// Generated by BusNet PQ (Produktiv) 6.6.4  © 2008 Sulzer GmbH
VERSION "HNNBNNNYNNNNNNNNNNNNNNNNNNNNNNNNNNNNNNNNNN/4/%%%/4/'%**4NNN///"

NS_ :

BS_:

BU_: BAP_Tester Booster_AMP DSP_SKODA Gateway_PQ35 Gateway_PQ46 GSM_Pager Kompassmodul MDI Radio_2DIN Radio_Modul Radio_SKODA Rearview RNS_300_NF RNS_MFD2 RNS_midline SDARS_Tuner Sprachbedienung Standheizung Tastatur Telematik_Basis TV_hybrid UHV_High UHV_low UHV_NAR UHV_Premium UHV_UMTS

BO_ 1349 mParkhilfe_3: 4 Gateway_PQ35
 SG_ PA3_System_codierung : 0|1@1+ (1,0) [0|1] "" Vector__XXX
 SG_ PA3_Anlage_defekt : 1|1@1+ (1,0) [0|1] "" Vector__XXX
 SG_ PA3_Taster_aktiviert : 2|1@1+ (1,0) [0|1] "" Vector__XXX
 SG_ PA3_Rueckwaertsgang_aktiv : 3|1@1+ (1,0) [0|1] "" Vector__XXX
 SG_ PA3_Geschwindigkeit_aus : 4|1@1+ (1,0) [0|1] "" Vector__XXX
 SG_ PA3_Tongeber_v_defekt : 5|1@1+ (1,0) [0|1] "" Vector__XXX
 SG_ PA3_Tongeber_h_defekt : 6|1@1+ (1,0) [0|1] "" Vector__XXX
 SG_ PA3_Audioabsenkung_Anforderung : 7|1@1+ (1,0) [0|1] "" Vector__XXX
 SG_ PA3_Eis_aus : 8|1@1+ (1,0) [0|1] "" Vector__XXX
 SG_ PA3_Schlechtweg_aus : 9|1@1+ (1,0) [0|1] "" Vector__XXX
 SG_ PA3_KD_Fehler : 15|1@1+ (1,0) [0|1] "" Vector__XXX
 SG_ PA3_Sensor_hll_defekt : 16|1@1+ (1,0) [0|1] "" Vector__XXX
 SG_ PA3_Sensor_hlm_defekt : 17|1@1+ (1,0) [0|1] "" Vector__XXX
 SG_ PA3_Sensor_hrm_defekt : 18|1@1+ (1,0) [0|1] "" Vector__XXX
 SG_ PA3_Sensor_hrr_defekt : 19|1@1+ (1,0) [0|1] "" Vector__XXX
 SG_ PA3_Sensor_vll_defekt : 20|1@1+ (1,0) [0|1] "" Vector__XXX
 SG_ PA3_Sensor_vlm_defekt : 21|1@1+ (1,0) [0|1] "" Vector__XXX
 SG_ PA3_Sensor_vrm_defekt : 22|1@1+ (1,0) [0|1] "" Vector__XXX
 SG_ PA3_Sensor_vrr_defekt : 23|1@1+ (1,0) [0|1] "" Vector__XXX
 SG_ PA3_Bereit : 24|1@1+ (1,0) [0|1] "" Vector__XXX
 SG_ PA3_Bereich_vo : 26|2@1+ (1,0) [0|3] "" Vector__XXX
 SG_ PA3_Bereich_hi : 28|2@1+ (1,0) [0|3] "" Vector__XXX
 SG_ PA3_Akust_aus : 30|1@1+ (1,0) [0|1] "" Vector__XXX
 SG_ PA3_Aufbau_erk : 31|1@1+ (1,0) [0|1] "" Vector__XXX

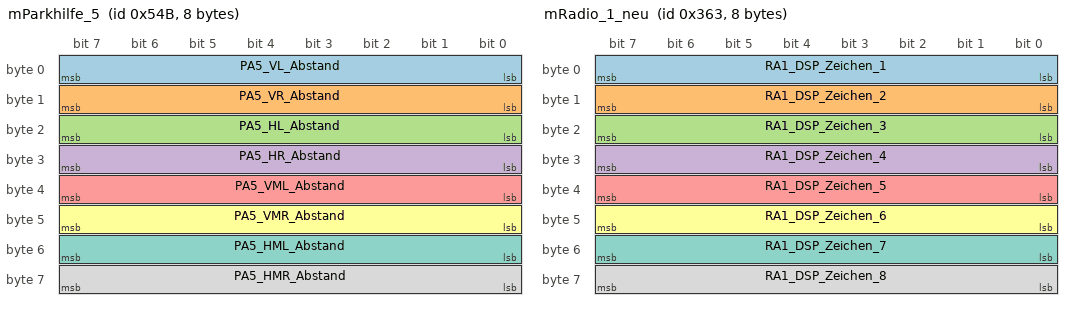
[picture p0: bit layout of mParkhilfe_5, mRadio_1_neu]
BO_ 1355 mParkhilfe_5: 8 Gateway_PQ35
 SG_ PA5_VL_Abstand : 0|8@1+ (1,0) [0|254] "Unit_CentiMeter"  Radio_SKODA
 SG_ PA5_VR_Abstand : 8|8@1+ (1,0) [0|254] "Unit_CentiMeter"  Radio_SKODA
 SG_ PA5_HL_Abstand : 16|8@1+ (1,0) [0|254] "Unit_CentiMeter"  Radio_SKODA
 SG_ PA5_HR_Abstand : 24|8@1+ (1,0) [0|254] "Unit_CentiMeter"  Radio_SKODA
 SG_ PA5_VML_Abstand : 32|8@1+ (1,0) [0|254] "Unit_CentiMeter"  Radio_SKODA
 SG_ PA5_VMR_Abstand : 40|8@1+ (1,0) [0|254] "Unit_CentiMeter"  Radio_SKODA
 SG_ PA5_HML_Abstand : 48|8@1+ (1,0) [0|254] "Unit_CentiMeter"  Radio_SKODA
 SG_ PA5_HMR_Abstand : 56|8@1+ (1,0) [0|254] "Unit_CentiMeter"  Radio_SKODA

BO_ 867 mRadio_1_neu: 8 Vector__XXX
 SG_ RA1_DSP_Zeichen_1 : 0|8@1+ (1,0) [0|255] ""  Gateway_PQ35,Gateway_PQ46
 SG_ RA1_DSP_Zeichen_2 : 8|8@1+ (1,0) [0|255] ""  Gateway_PQ35,Gateway_PQ46
 SG_ RA1_DSP_Zeichen_3 : 16|8@1+ (1,0) [0|255] ""  Gateway_PQ35,Gateway_PQ46
 SG_ RA1_DSP_Zeichen_4 : 24|8@1+ (1,0) [0|255] ""  Gateway_PQ35,Gateway_PQ46
 SG_ RA1_DSP_Zeichen_5 : 32|8@1+ (1,0) [0|255] ""  Gateway_PQ35,Gateway_PQ46
 SG_ RA1_DSP_Zeichen_6 : 40|8@1+ (1,0) [0|255] ""  Gateway_PQ35,Gateway_PQ46
 SG_ RA1_DSP_Zeichen_7 : 48|8@1+ (1,0) [0|255] ""  Gateway_PQ35,Gateway_PQ46
 SG_ RA1_DSP_Zeichen_8 : 56|8@1+ (1,0) [0|255] ""  Gateway_PQ35,Gateway_PQ46

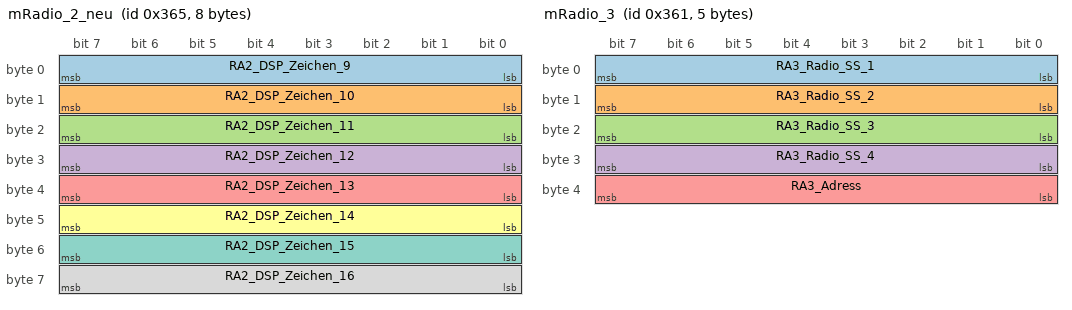
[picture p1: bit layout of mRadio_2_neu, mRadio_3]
BO_ 869 mRadio_2_neu: 8 Vector__XXX
 SG_ RA2_DSP_Zeichen_9 : 0|8@1+ (1,0) [0|255] ""  Gateway_PQ35,Gateway_PQ46
 SG_ RA2_DSP_Zeichen_10 : 8|8@1+ (1,0) [0|255] ""  Gateway_PQ35,Gateway_PQ46
 SG_ RA2_DSP_Zeichen_11 : 16|8@1+ (1,0) [0|255] ""  Gateway_PQ35,Gateway_PQ46
 SG_ RA2_DSP_Zeichen_12 : 24|8@1+ (1,0) [0|255] ""  Gateway_PQ35,Gateway_PQ46
 SG_ RA2_DSP_Zeichen_13 : 32|8@1+ (1,0) [0|255] ""  Gateway_PQ35,Gateway_PQ46
 SG_ RA2_DSP_Zeichen_14 : 40|8@1+ (1,0) [0|255] ""  Gateway_PQ35,Gateway_PQ46
 SG_ RA2_DSP_Zeichen_15 : 48|8@1+ (1,0) [0|255] ""  Gateway_PQ35,Gateway_PQ46
 SG_ RA2_DSP_Zeichen_16 : 56|8@1+ (1,0) [0|255] ""  Gateway_PQ35,Gateway_PQ46

BO_ 865 mRadio_3: 5 Radio_2DIN
 SG_ RA3_Radio_SS_1 : 0|8@1+ (1,0) [0|255] ""  Gateway_PQ35,Gateway_PQ46
 SG_ RA3_Radio_SS_2 : 8|8@1+ (1,0) [0|255] ""  Gateway_PQ35,Gateway_PQ46
 SG_ RA3_Radio_SS_3 : 16|8@1+ (1,0) [0|255] ""  Gateway_PQ35,Gateway_PQ46
 SG_ RA3_Radio_SS_4 : 24|8@1+ (1,0) [0|255] ""  Gateway_PQ35,Gateway_PQ46
 SG_ RA3_Adress : 32|8@1+ (1,0) [0|255] ""  Gateway_PQ35,Gateway_PQ46

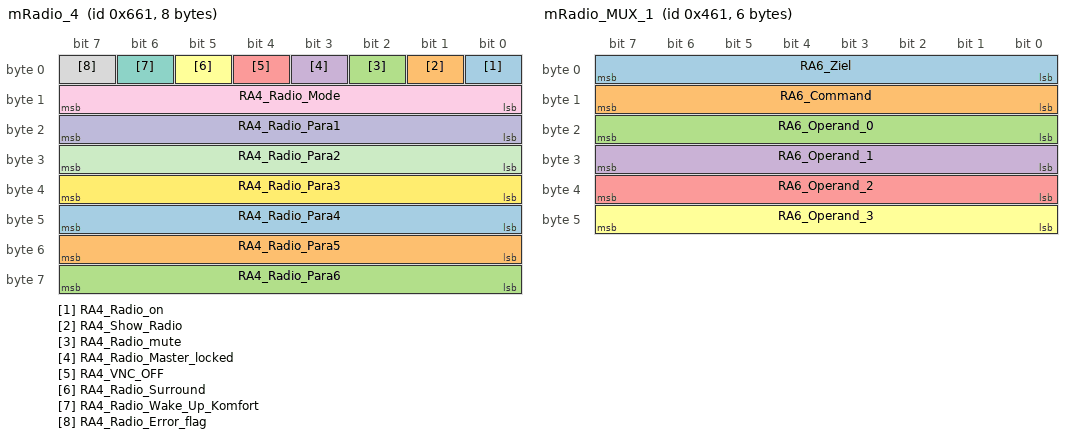
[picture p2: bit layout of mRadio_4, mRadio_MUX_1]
BO_ 1633 mRadio_4: 8 Radio_2DIN
 SG_ RA4_Radio_on : 0|1@1+ (1,0) [0|1] ""  DSP_SKODA,Gateway_PQ35,Gateway_PQ46,MDI,Telematik_Basis,TV_hybrid,UHV_High,UHV_low,UHV_NAR,UHV_Premium,UHV_UMTS
 SG_ RA4_Show_Radio : 1|1@1+ (1,0) [0|1] ""  Gateway_PQ35,Gateway_PQ46
 SG_ RA4_Radio_mute : 2|1@1+ (1,0) [0|1] ""  Booster_AMP,Gateway_PQ35,Gateway_PQ46,Telematik_Basis,UHV_low,UHV_NAR,UHV_Premium,UHV_UMTS
 SG_ RA4_Radio_Master_locked : 3|1@1+ (1,0) [0|1] ""  Gateway_PQ35,Gateway_PQ46
 SG_ RA4_VNC_OFF : 4|1@1+ (1,0) [0|1] ""  Gateway_PQ35,Gateway_PQ46
 SG_ RA4_Radio_Surround : 5|1@1+ (1,0) [0|1] ""  Gateway_PQ35,Gateway_PQ46
 SG_ RA4_Radio_Wake_Up_Komfort : 6|1@1+ (1,0) [0|1] ""  Gateway_PQ35,Gateway_PQ46
 SG_ RA4_Radio_Error_flag : 7|1@1+ (1,0) [0|1] ""  Gateway_PQ35,Gateway_PQ46
 SG_ RA4_Radio_Mode : 8|8@1+ (1,0) [0|255] ""  Gateway_PQ35,Gateway_PQ46
 SG_ RA4_Radio_Para1 : 16|8@1+ (1,0) [0|255] ""  Gateway_PQ35,Gateway_PQ46
 SG_ RA4_Radio_Para2 : 24|8@1+ (1,0) [0|255] ""  Gateway_PQ35,Gateway_PQ46
 SG_ RA4_Radio_Para3 : 32|8@1+ (1,0) [0|255] ""  Gateway_PQ35,Gateway_PQ46
 SG_ RA4_Radio_Para4 : 40|8@1+ (1,0) [0|255] ""  Gateway_PQ35,Gateway_PQ46
 SG_ RA4_Radio_Para5 : 48|8@1+ (1,0) [0|255] ""  Gateway_PQ35,Gateway_PQ46
 SG_ RA4_Radio_Para6 : 56|8@1+ (1,0) [0|255] ""  Gateway_PQ35,Gateway_PQ46

BO_ 1121 mRadio_MUX_1: 6 RNS_MFD2
 SG_ RA6_Ziel : 0|8@1+ (1,0) [0|255] "" Vector__XXX
 SG_ RA6_Command : 8|8@1+ (1,0) [0|255] "" Vector__XXX
 SG_ RA6_Operand_0 : 16|8@1+ (1,0) [0|255] "" Vector__XXX
 SG_ RA6_Operand_1 : 24|8@1+ (1,0) [0|255] "" Vector__XXX
 SG_ RA6_Operand_2 : 32|8@1+ (1,0) [0|255] "" Vector__XXX
 SG_ RA6_Operand_3 : 40|8@1+ (1,0) [0|255] "" Vector__XXX

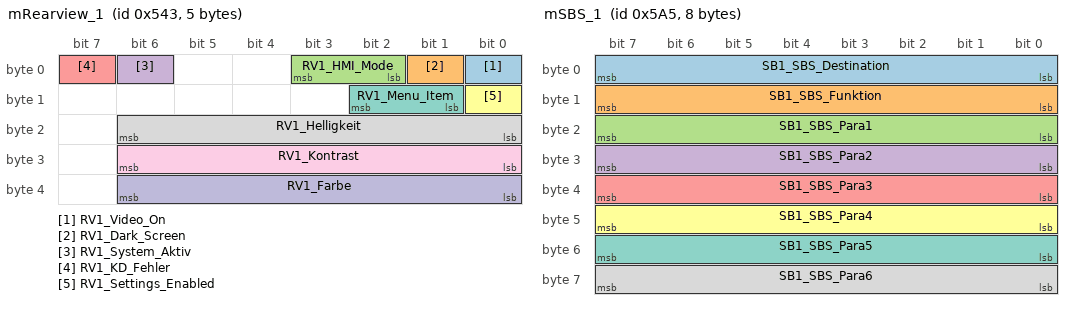
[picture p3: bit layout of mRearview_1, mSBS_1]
BO_ 1347 mRearview_1: 5 Rearview
 SG_ RV1_Video_On : 0|1@1+ (1,0) [0|1] ""  Radio_Modul,RNS_300_NF,RNS_midline
 SG_ RV1_Dark_Screen : 1|1@1+ (1,0) [0|1] "" Vector__XXX
 SG_ RV1_HMI_Mode : 2|2@1+ (1,0) [0|3] "" Vector__XXX
 SG_ RV1_System_Aktiv : 6|1@1+ (1,0) [0|1] "" Vector__XXX
 SG_ RV1_KD_Fehler : 7|1@1+ (1,0) [0|1] ""  Gateway_PQ35,Gateway_PQ46
 SG_ RV1_Settings_Enabled : 8|1@1+ (1,0) [0|1] "" Vector__XXX
 SG_ RV1_Menu_Item : 9|2@1+ (1,0) [0|3] "" Vector__XXX
 SG_ RV1_Helligkeit : 16|7@1+ (1,0) [0|100] "Unit_PerCent" Vector__XXX
 SG_ RV1_Kontrast : 24|7@1+ (1,0) [0|100] "Unit_PerCent" Vector__XXX
 SG_ RV1_Farbe : 32|7@1+ (1,0) [0|100] "Unit_PerCent" Vector__XXX

BO_ 1445 mSBS_1: 8 Sprachbedienung
 SG_ SB1_SBS_Destination : 0|8@1+ (1,0) [1|255] "" Vector__XXX
 SG_ SB1_SBS_Funktion : 8|8@1+ (1,0) [1|255] "" Vector__XXX
 SG_ SB1_SBS_Para1 : 16|8@1+ (1,0) [1|255] "" Vector__XXX
 SG_ SB1_SBS_Para2 : 24|8@1+ (1,0) [1|255] "" Vector__XXX
 SG_ SB1_SBS_Para3 : 32|8@1+ (1,0) [1|255] "" Vector__XXX
 SG_ SB1_SBS_Para4 : 40|8@1+ (1,0) [1|255] "" Vector__XXX
 SG_ SB1_SBS_Para5 : 48|8@1+ (1,0) [1|255] "" Vector__XXX
 SG_ SB1_SBS_Para6 : 56|8@1+ (1,0) [1|255] "" Vector__XXX

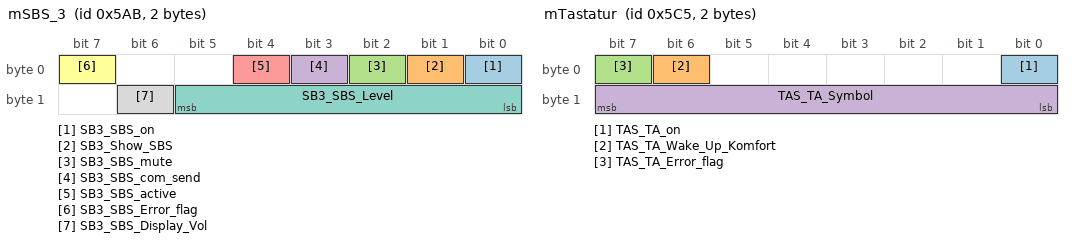
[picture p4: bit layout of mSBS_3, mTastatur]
BO_ 1451 mSBS_3: 2 Sprachbedienung
 SG_ SB3_SBS_on : 0|1@1+ (1,0) [0|1] ""  Gateway_PQ35,Gateway_PQ46
 SG_ SB3_Show_SBS : 1|1@1+ (1,0) [0|1] ""  Gateway_PQ35,Gateway_PQ46
 SG_ SB3_SBS_mute : 2|1@1+ (1,0) [0|1] ""  Gateway_PQ35,Gateway_PQ46,Radio_2DIN,Radio_SKODA
 SG_ SB3_SBS_com_send : 3|1@1+ (1,0) [0|1] ""  Gateway_PQ35,Gateway_PQ46
 SG_ SB3_SBS_active : 4|1@1+ (1,0) [0|1] ""  Gateway_PQ35,Gateway_PQ46
 SG_ SB3_SBS_Error_flag : 7|1@1+ (1,0) [0|1] ""  Gateway_PQ35,Gateway_PQ46
 SG_ SB3_SBS_Level : 8|6@1+ (1,0) [0|63] ""  Gateway_PQ35,Gateway_PQ46
 SG_ SB3_SBS_Display_Vol : 14|1@1+ (1,0) [0|1] ""  Gateway_PQ35,Gateway_PQ46

BO_ 1621 mSollverbau_neu: 8 Gateway_PQ35
 SG_ VBN_Motor_A : 0|1@1+ (1,0) [0|1] ""  Telematik_Basis
 SG_ VBN_Getriebe_A : 1|1@1+ (1,0) [0|1] ""  Telematik_Basis
 SG_ VBN_Bremse_A : 2|1@1+ (1,0) [0|1] ""  Telematik_Basis
 SG_ VBN_Kombi_A : 3|1@1+ (1,0) [0|1] "" Vector__XXX
 SG_ VBN_LSM_A : 4|1@1+ (1,0) [0|1] ""  Telematik_Basis
 SG_ VBN_Airbag_A : 5|1@1+ (1,0) [0|1] ""  Telematik_Basis
 SG_ VBN_Lenkhilfe_A : 6|1@1+ (1,0) [0|1] ""  Telematik_Basis
 SG_ VBN_dyn_LWR_A : 7|1@1+ (1,0) [0|1] ""  Telematik_Basis
 SG_ VBN_Niveau_A : 8|1@1+ (1,0) [0|1] "" Vector__XXX
 SG_ VBN_Allrad_A : 9|1@1+ (1,0) [0|1] ""  RNS_300_NF,RNS_midline,Telematik_Basis
 SG_ VBN_ADR_Sensor_A : 10|1@1+ (1,0) [0|1] ""  Telematik_Basis
 SG_ VBN_ADR_getrennt : 11|1@1+ (1,0) [0|1] ""  Telematik_Basis
 SG_ VBN_Parkbremse_A : 12|1@1+ (1,0) [0|1] ""  Telematik_Basis
 SG_ VBN_EZS_A : 13|1@1+ (1,0) [0|1] "" Vector__XXX
 SG_ VBN_Daempfer_A : 14|1@1+ (1,0) [0|1] ""  Telematik_Basis
 SG_ VBN_Quersperre : 15|1@1+ (1,0) [0|1] "" Vector__XXX
 SG_ VBN_Motor_Slave_A : 16|1@1+ (1,0) [0|1] "" Vector__XXX
 SG_ VBN_SWA_A : 17|1@1+ (1,0) [0|1] "" Vector__XXX
 SG_ VBN_LDW_A : 18|1@1+ (1,0) [0|1] "" Vector__XXX
 SG_ VBN_RKA_Plus_A : 19|1@1+ (1,0) [0|1] "" Vector__XXX
 SG_ VBN_PLA_A : 20|1@1+ (1,0) [0|1] ""  Radio_Modul,RNS_300_NF,RNS_midline
 SG_ VBN_WFS_KBI : 21|1@1+ (1,0) [0|1] ""  Telematik_Basis
 SG_ VBN_Kombi_KBI : 22|1@1+ (1,0) [0|1] ""  Telematik_Basis
 SG_ VBN_Soll_Ist_OK : 23|1@1+ (1,0) [0|1] ""  Booster_AMP,DSP_SKODA,Radio_2DIN,Radio_Modul,Radio_SKODA,RNS_300_NF,RNS_midline,Sprachbedienung,Standheizung,Telematik_Basis,TV_hybrid,UHV_NAR,UHV_UMTS
 SG_ VBN_BSG_K : 24|1@1+ (1,0) [0|1] ""  Telematik_Basis
 SG_ VBN_KSG_K : 25|1@1+ (1,0) [0|1] ""  Telematik_Basis
 SG_ VBN_TSG_FT_K : 26|1@1+ (1,0) [0|1] ""  Telematik_Basis
 SG_ VBN_TSG_BT_K : 27|1@1+ (1,0) [0|1] ""  Telematik_Basis
 SG_ VBN_TSG_HL_K : 28|1@1+ (1,0) [0|1] ""  Telematik_Basis
 SG_ VBN_TSG_HR_K : 29|1@1+ (1,0) [0|1] ""  Telematik_Basis
 SG_ VBN_Memory_K : 30|1@1+ (1,0) [0|1] ""  Telematik_Basis
 SG_ VBN_Dachmodul_K : 31|1@1+ (1,0) [0|1] "" Vector__XXX
 SG_ VBN_Zentralelektrik_II_K : 32|1@1+ (1,0) [0|1] "" Vector__XXX
 SG_ VBN_RDK_K : 33|1@1+ (1,0) [0|1] ""  Telematik_Basis
 SG_ VBN_SMLS_K : 34|1@1+ (1,0) [0|1] ""  Telematik_Basis,UHV_low,UHV_NAR,UHV_Premium,UHV_UMTS
 SG_ VBN_Gateway_K : 35|1@1+ (1,0) [0|1] ""  Telematik_Basis
 SG_ VBN_Clima_K : 36|1@1+ (1,0) [0|1] ""  Radio_Modul,RNS_300_NF,RNS_midline,Standheizung,Telematik_Basis
 SG_ VBN_APS_K : 37|1@1+ (1,0) [0|1] ""  RNS_300_NF,RNS_midline,Telematik_Basis
 SG_ VBN_PTC_Heizung_K : 38|1@1+ (1,0) [0|1] ""  Standheizung,Telematik_Basis
 SG_ VBN_Standhzg_K : 39|1@1+ (1,0) [0|1] ""  Standheizung,Telematik_Basis
 SG_ VBN_VSG_K : 40|1@1+ (1,0) [0|1] ""  Telematik_Basis
 SG_ VBN_RSE_I : 41|1@1+ (1,0) [0|1] "" Vector__XXX
 SG_ VBN_Wischer_K : 42|1@1+ (1,0) [0|1] "" Vector__XXX
 SG_ VBN_MDI_I : 43|1@1+ (1,0) [0|1] ""  Radio_Modul,RNS_300_NF,RNS_midline
 SG_ VBN_AAG_K : 44|1@1+ (1,0) [0|1] ""  Telematik_Basis
 SG_ VBN_Mem_BF_K : 45|1@1+ (1,0) [0|1] ""  Telematik_Basis
 SG_ VBN_Easy_Entry_VF : 46|1@1+ (1,0) [0|1] "" Vector__XXX
 SG_ VBN_Easy_Entry_VB : 47|1@1+ (1,0) [0|1] "" Vector__XXX
 SG_ VBN_Heckdeckel_K : 48|1@1+ (1,0) [0|1] ""  Telematik_Basis
 SG_ VBN_Rearview_I : 49|1@1+ (1,0) [0|1] ""  Radio_Modul
 SG_ VBN_Sonderfahrzeug_SG_K : 50|1@1+ (1,0) [0|1] ""  Telematik_Basis
 SG_ VBN_Tastenmodul_I : 51|1@1+ (1,0) [0|1] ""  Telematik_Basis,UHV_low,UHV_NAR,UHV_Premium,UHV_UMTS
 SG_ VBN_Kompass_I : 52|1@1+ (1,0) [0|1] ""  Telematik_Basis
 SG_ VBN_WFS_K : 53|1@1+ (1,0) [0|1] ""  Telematik_Basis
 SG_ VBN_GSM_Pager_I : 54|1@1+ (1,0) [0|1] "" Vector__XXX
 SG_ VBN_InfoElektronik : 55|1@1+ (1,0) [0|1] "" Vector__XXX
 SG_ VBN_DSP_I : 56|1@1+ (1,0) [0|1] ""  Booster_AMP,DSP_SKODA,Radio_2DIN,Radio_Modul,Radio_SKODA,RNS_300_NF,RNS_midline,Telematik_Basis,UHV_low,UHV_NAR,UHV_Premium,UHV_UMTS
 SG_ VBN_DAB_I : 57|1@1+ (1,0) [0|1] ""  Radio_2DIN,SDARS_Tuner,Telematik_Basis
 SG_ VBN_Telematik_I : 58|1@1+ (1,0) [0|1] ""  Telematik_Basis,UHV_NAR
 SG_ VBN_Navigation_I : 59|1@1+ (1,0) [0|1] ""  Rearview,Telematik_Basis,TV_hybrid,UHV_low,UHV_NAR,UHV_Premium,UHV_UMTS
 SG_ VBN_TV_Tuner_I : 60|1@1+ (1,0) [0|1] ""  Radio_Modul,Rearview,RNS_midline,Telematik_Basis,TV_hybrid
 SG_ VBN_Neigungsmodul_I : 61|1@1+ (1,0) [0|1] "" Vector__XXX
 SG_ VBN_Radio_I : 62|1@1+ (1,0) [0|1] ""  Booster_AMP,DSP_SKODA,Radio_2DIN,Radio_SKODA,Rearview,Telematik_Basis,UHV_low,UHV_NAR,UHV_Premium,UHV_UMTS
 SG_ VBN_Telefon_I : 63|1@1+ (1,0) [0|1] ""  Booster_AMP,DSP_SKODA,Radio_2DIN,Radio_Modul,Radio_SKODA,RNS_300_NF,RNS_midline,Telematik_Basis,UHV_NAR,UHV_UMTS

BO_ 997 mStHeizung_1: 8 Standheizung
 SG_ SH1_Funk_ein : 0|1@1+ (1,0) [0|1] ""  Gateway_PQ35,Gateway_PQ46,Telematik_Basis
 SG_ SH1_Funk_aus : 1|1@1+ (1,0) [0|1] ""  Gateway_PQ35,Gateway_PQ46,Telematik_Basis
 SG_ SH1_FunkSH_Ein : 2|1@1+ (1,0) [0|1] ""  Gateway_PQ35,Gateway_PQ46,Telematik_Basis
 SG_ SH1_FunkStLftg : 3|1@1+ (1,0) [0|1] ""  Gateway_PQ35,Gateway_PQ46,Telematik_Basis
 SG_ SH1_Clima_aus : 4|1@1+ (1,0) [0|1] ""  Gateway_PQ35,Gateway_PQ46
 SG_ SH1_SH_Modus : 5|1@1+ (1,0) [0|1] ""  Gateway_PQ35,Gateway_PQ46,Telematik_Basis
 SG_ SH1_Prog_Modus : 6|1@1+ (1,0) [0|1] ""  Gateway_PQ35,Gateway_PQ46,Telematik_Basis
 SG_ SH1_Wake_Up_Komfort : 7|1@1+ (1,0) [0|1] ""  Gateway_PQ35,Gateway_PQ46
 SG_ SH1_Geblaese : 8|1@1+ (1,0) [0|1] ""  Gateway_PQ35,Gateway_PQ46,Telematik_Basis
 SG_ SH1_LED : 9|1@1+ (1,0) [0|1] ""  Gateway_PQ35,Gateway_PQ46,Telematik_Basis
 SG_ SH1_ZusatzHeizung : 10|1@1+ (1,0) [0|1] ""  Gateway_PQ35,Gateway_PQ46,Telematik_Basis
 SG_ SH1_ein_Wasserpumpe : 11|1@1+ (1,0) [0|1] ""  Gateway_PQ35,Gateway_PQ46
 SG_ SH1_Fehlerstatus : 12|3@1+ (1,0) [0|7] ""  Gateway_PQ35,Gateway_PQ46,Telematik_Basis
 SG_ SH1_KD_Fehler : 15|1@1+ (1,0) [0|1] ""  Gateway_PQ35,Gateway_PQ46
 SG_ SH1_K_Verbrauch : 16|14@1+ (1,0) [0|8191] "Unit_MilliLiter"  Gateway_PQ35,Gateway_PQ46,Telematik_Basis
 SG_ SH1_SH_Verbau : 30|1@1+ (1,0) [0|1] ""  Gateway_PQ35,Gateway_PQ46,Telematik_Basis
 SG_ SH1_K_Fehler : 31|1@1+ (1,0) [0|1] ""  Gateway_PQ35,Gateway_PQ46,Telematik_Basis
 SG_ SH1_Heizleistung : 32|8@1+ (1,0) [0|255] ""  Gateway_PQ35,Gateway_PQ46,Telematik_Basis
 SG_ SH1_HeizkreisTemp : 40|8@1+ (0.75,-48) [-48|142.5] "Unit_DegreCelsi"  Gateway_PQ35,Gateway_PQ46,Telematik_Basis
 SG_ SH1_Pumpe_on : 48|1@1+ (1,0) [0|1] ""  Gateway_PQ35,Gateway_PQ46
 SG_ SH1_KW_Warm : 49|1@1+ (1,0) [0|1] ""  Gateway_PQ35,Gateway_PQ46
 SG_ SH1_Lueften : 56|1@1+ (1,0) [0|1] ""  Gateway_PQ35,Gateway_PQ46

BO_ 1617 mSysteminfo_1: 8 Gateway_PQ35
 SG_ SY1_CAN_Extern : 0|1@1+ (1,0) [0|1] "" Vector__XXX
 SG_ SY1_Diag_Antrieb : 1|1@1+ (1,0) [0|1] "" Vector__XXX
 SG_ SY1_Sleep_Komfort : 2|1@1+ (1,0) [0|1] ""  Booster_AMP,DSP_SKODA,Kompassmodul,MDI,Radio_2DIN,Radio_Modul,Radio_SKODA,Rearview,RNS_300_NF,RNS_MFD2,RNS_midline,SDARS_Tuner,Sprachbedienung,Standheizung,Tastatur,Telematik_Basis,TV_hybrid,UHV_High,UHV_low,UHV_NAR,UHV_Premium,UHV_UMTS
 SG_ SY1_Diag_Komfort : 3|1@1+ (1,0) [0|1] "" Vector__XXX
 SG_ SY1_Sleep_Infotainment : 4|1@1+ (1,0) [0|1] "" Vector__XXX
 SG_ SY1_Diag_Infotainment : 5|1@1+ (1,0) [0|1] ""  UHV_NAR,UHV_UMTS
 SG_ SY1_Infotainment : 6|1@1+ (1,0) [0|1] ""  MDI,RNS_300_NF,RNS_midline,UHV_NAR,UHV_UMTS
 SG_ SY1_Verbauliste_gueltig : 7|1@1+ (1,0) [0|1] ""  Booster_AMP,DSP_SKODA,Kompassmodul,Radio_Modul,RNS_300_NF,RNS_midline,SDARS_Tuner,Sprachbedienung,Standheizung,Tastatur,Telematik_Basis,TV_hybrid,UHV_low,UHV_NAR,UHV_Premium,UHV_UMTS
 SG_ SY1_Klasse : 8|4@1+ (1,0) [0|15] ""  Booster_AMP,DSP_SKODA,Kompassmodul,Radio_2DIN,Radio_Modul,Radio_SKODA,Rearview,RNS_300_NF,RNS_midline,SDARS_Tuner,Sprachbedienung,Standheizung,Tastatur,Telematik_Basis,TV_hybrid,UHV_low,UHV_NAR,UHV_Premium,UHV_UMTS
 SG_ SY1_Marke : 12|4@1+ (1,0) [0|15] ""  Booster_AMP,DSP_SKODA,Kompassmodul,Radio_2DIN,Radio_Modul,Radio_SKODA,Rearview,RNS_300_NF,RNS_midline,SDARS_Tuner,Sprachbedienung,Standheizung,Tastatur,Telematik_Basis,TV_hybrid,UHV_low,UHV_NAR,UHV_Premium,UHV_UMTS
 SG_ SY1_Derivat : 16|4@1+ (1,0) [0|15] ""  Booster_AMP,DSP_SKODA,Kompassmodul,Radio_2DIN,Radio_Modul,Radio_SKODA,Rearview,RNS_300_NF,RNS_midline,SDARS_Tuner,Sprachbedienung,Standheizung,Tastatur,Telematik_Basis,TV_hybrid,UHV_low,UHV_NAR,UHV_Premium,UHV_UMTS
 SG_ SY1_Generation : 20|4@1+ (1,0) [0|15] ""  Booster_AMP,DSP_SKODA,Kompassmodul,Radio_2DIN,Radio_Modul,Radio_SKODA,Rearview,RNS_300_NF,RNS_midline,SDARS_Tuner,Sprachbedienung,Standheizung,Tastatur,Telematik_Basis,TV_hybrid,UHV_low,UHV_NAR,UHV_Premium,UHV_UMTS
 SG_ SY1_Erweiterung : 24|4@1+ (1,0) [0|15] ""  UHV_NAR
 SG_ SY1_Rechtslenker : 28|1@1+ (1,0) [0|1] ""  Booster_AMP,DSP_SKODA,Kompassmodul,Radio_Modul,RNS_300_NF,RNS_midline,SDARS_Tuner,Sprachbedienung,Standheizung,Tastatur,Telematik_Basis,UHV_NAR,UHV_UMTS
 SG_ SY1_Viertuerer : 29|1@1+ (1,0) [0|1] ""  Booster_AMP,DSP_SKODA,Kompassmodul,SDARS_Tuner,Sprachbedienung,Tastatur,Telematik_Basis
 SG_ SY1_Transportmode : 30|1@1+ (1,0) [0|1] ""  Booster_AMP,DSP_SKODA,Kompassmodul,MDI,Radio_2DIN,Radio_Modul,Radio_SKODA,RNS_300_NF,RNS_midline,SDARS_Tuner,Sprachbedienung,Standheizung,Tastatur,Telematik_Basis,TV_hybrid,UHV_low,UHV_NAR,UHV_Premium,UHV_UMTS
 SG_ SY1_KD_Fehler : 31|1@1+ (1,0) [0|1] "" Vector__XXX
 SG_ SY1_VersLowCAN_Komfort : 32|4@1+ (1,0) [0|9] "" Vector__XXX
 SG_ SY1_VersHighCAN_Komfort : 36|4@1+ (1,0) [0|9] "" Vector__XXX
 SG_ SY1_VersLowCAN_Antrieb : 40|4@1+ (1,0) [0|9] "" Vector__XXX
 SG_ SY1_VersHighCAN_Antrieb : 44|4@1+ (1,0) [0|9] "" Vector__XXX
 SG_ SY1_Relais_FAS_Zweig : 48|2@1+ (1,0) [0|3] "" Vector__XXX
 SG_ SY1_ELV_Lock_Supply : 50|1@1+ (1,0) [0|1] "" Vector__XXX
 SG_ SY1_QRS_Messmodus : 51|1@1+ (1,0) [0|1] ""  Radio_Modul,RNS_300_NF,RNS_midline,Standheizung
 SG_ SY1_NWDF_gueltig : 54|1@1+ (1,0) [0|1] ""  MDI,Radio_Modul,Rearview,RNS_300_NF,RNS_midline,Standheizung,UHV_High,UHV_low,UHV_NAR,UHV_Premium,UHV_UMTS
 SG_ SY1_NWDF : 55|1@1+ (1,0) [0|1] ""  MDI,Radio_Modul,Rearview,RNS_300_NF,RNS_midline,Standheizung,UHV_High,UHV_low,UHV_NAR,UHV_Premium,UHV_UMTS
 SG_ SY1_Notbrems_Status : 56|1@1+ (1,0) [0|1] "" Vector__XXX

BO_ 1477 mTastatur: 2 Tastatur
 SG_ TAS_TA_on : 0|1@1+ (1,0) [0|1] ""  Gateway_PQ35,Gateway_PQ46,UHV_Premium,UHV_UMTS
 SG_ TAS_TA_Wake_Up_Komfort : 6|1@1+ (1,0) [0|1] ""  Gateway_PQ35,Gateway_PQ46
 SG_ TAS_TA_Error_flag : 7|1@1+ (1,0) [0|1] ""  Gateway_PQ35,Gateway_PQ46
 SG_ TAS_TA_Symbol : 8|8@1+ (1,0) [0|255] ""  Gateway_PQ35,Gateway_PQ46,UHV_Premium,UHV_UMTS

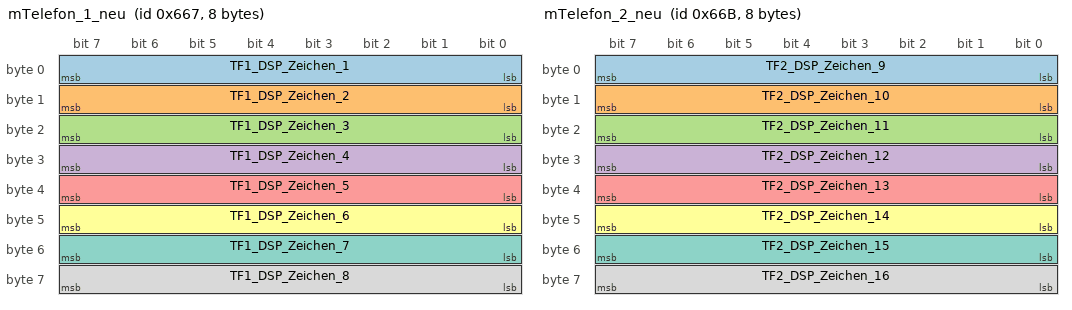
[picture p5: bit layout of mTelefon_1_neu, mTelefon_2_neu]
BO_ 1639 mTelefon_1_neu: 8 Vector__XXX
 SG_ TF1_DSP_Zeichen_1 : 0|8@1+ (1,0) [0|255] ""  Gateway_PQ35,Gateway_PQ46
 SG_ TF1_DSP_Zeichen_2 : 8|8@1+ (1,0) [0|255] ""  Gateway_PQ35,Gateway_PQ46
 SG_ TF1_DSP_Zeichen_3 : 16|8@1+ (1,0) [0|255] ""  Gateway_PQ35,Gateway_PQ46
 SG_ TF1_DSP_Zeichen_4 : 24|8@1+ (1,0) [0|255] ""  Gateway_PQ35,Gateway_PQ46
 SG_ TF1_DSP_Zeichen_5 : 32|8@1+ (1,0) [0|255] ""  Gateway_PQ35,Gateway_PQ46
 SG_ TF1_DSP_Zeichen_6 : 40|8@1+ (1,0) [0|255] ""  Gateway_PQ35,Gateway_PQ46
 SG_ TF1_DSP_Zeichen_7 : 48|8@1+ (1,0) [0|255] ""  Gateway_PQ35,Gateway_PQ46
 SG_ TF1_DSP_Zeichen_8 : 56|8@1+ (1,0) [0|255] ""  Gateway_PQ35,Gateway_PQ46

BO_ 1643 mTelefon_2_neu: 8 Vector__XXX
 SG_ TF2_DSP_Zeichen_9 : 0|8@1+ (1,0) [0|255] ""  Gateway_PQ35,Gateway_PQ46
 SG_ TF2_DSP_Zeichen_10 : 8|8@1+ (1,0) [0|255] ""  Gateway_PQ35,Gateway_PQ46
 SG_ TF2_DSP_Zeichen_11 : 16|8@1+ (1,0) [0|255] ""  Gateway_PQ35,Gateway_PQ46
 SG_ TF2_DSP_Zeichen_12 : 24|8@1+ (1,0) [0|255] ""  Gateway_PQ35,Gateway_PQ46
 SG_ TF2_DSP_Zeichen_13 : 32|8@1+ (1,0) [0|255] ""  Gateway_PQ35,Gateway_PQ46
 SG_ TF2_DSP_Zeichen_14 : 40|8@1+ (1,0) [0|255] ""  Gateway_PQ35,Gateway_PQ46
 SG_ TF2_DSP_Zeichen_15 : 48|8@1+ (1,0) [0|255] ""  Gateway_PQ35,Gateway_PQ46
 SG_ TF2_DSP_Zeichen_16 : 56|8@1+ (1,0) [0|255] ""  Gateway_PQ35,Gateway_PQ46

BO_ 1637 mTelefon_3: 7 UHV_UMTS
 SG_ TF3_BT_ConnectionState : 22|1@1+ (1,0) [0|1] ""  Gateway_PQ46,Gateway_PQ35
 SG_ TF3_Phone_on : 0|1@1+ (1,0) [0|1] ""  Gateway_PQ35,Gateway_PQ46
 SG_ TF3_Show_Phone : 1|1@1+ (1,0) [0|1] ""  Gateway_PQ35,Gateway_PQ46,Radio_Modul,Radio_SKODA,RNS_300_NF,RNS_midline
 SG_ TF3_Phone_mute : 2|1@1+ (1,0) [0|1] ""  Gateway_PQ35,Gateway_PQ46,Radio_2DIN,Radio_Modul,Radio_SKODA,RNS_300_NF,RNS_MFD2,RNS_midline
 SG_ TF3_Phone_active_call : 3|1@1+ (1,0) [0|1] ""  Gateway_PQ35,Gateway_PQ46
 SG_ TF3_Phone_ring : 4|1@1+ (1,0) [0|1] ""  Gateway_PQ35,Gateway_PQ46
 SG_ TF3_Phone_sim_OK : 5|1@1+ (1,0) [0|1] ""  Gateway_PQ35,Gateway_PQ46
 SG_ TF3_Phone_pin_OK : 6|1@1+ (1,0) [0|1] ""  Gateway_PQ35,Gateway_PQ46
 SG_ TF3_Phone_Error_flag : 7|1@1+ (1,0) [0|1] ""  Gateway_PQ35,Gateway_PQ46
 SG_ TF3_Phone_Level : 8|6@1+ (1,0) [0|63] ""  Gateway_PQ35,Gateway_PQ46
 SG_ TF3_Phone_Display_Vol : 14|1@1+ (1,0) [0|1] ""  Gateway_PQ35,Gateway_PQ46
 SG_ TF3_Phone_Init : 15|1@1+ (1,0) [0|1] ""  Gateway_PQ35,Gateway_PQ46
 SG_ TF3_Mute_Msg_Code : 16|3@1+ (1,0) [0|7] ""  Gateway_PQ35,Gateway_PQ46,Radio_2DIN,Radio_Modul,RNS_300_NF,RNS_MFD2,RNS_midline
 SG_ TF3_Wake_Up_Komfort : 19|1@1+ (1,0) [0|1] ""  Gateway_PQ35,Gateway_PQ46
 SG_ TF3_Radio_Access : 20|2@1+ (1,0) [0|3] ""  Gateway_PQ35,Gateway_PQ46
 SG_ TF3_Provider : 24|12@1+ (1,0) [0|4095] ""  Gateway_PQ35,Gateway_PQ46
 SG_ TF3_Feldstaerke : 36|4@1+ (1,0) [0|15] ""  Gateway_PQ35,Gateway_PQ46
 SG_ TF3_Laendercode : 40|12@1+ (1,0) [0|4095] ""  Gateway_PQ35,Gateway_PQ46
 SG_ TF3_Feldstaerke_Fehler : 52|1@1+ (1,0) [0|1] ""  Gateway_PQ35,Gateway_PQ46
 SG_ TF3_Registrierungsstatus : 53|3@1+ (1,0) [0|7] ""  Gateway_PQ35,Gateway_PQ46

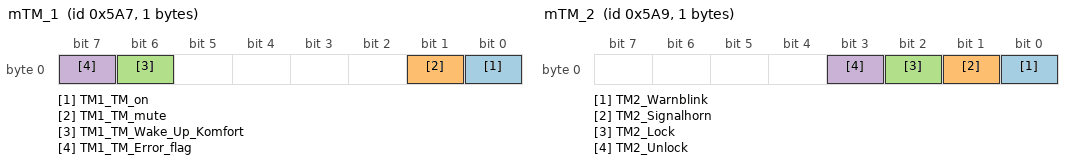
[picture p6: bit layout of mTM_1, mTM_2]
BO_ 1447 mTM_1: 1 Telematik_Basis
 SG_ TM1_TM_on : 0|1@1+ (1,0) [0|1] "" Vector__XXX
 SG_ TM1_TM_mute : 1|1@1+ (1,0) [0|1] ""  Radio_2DIN,Radio_SKODA
 SG_ TM1_TM_Wake_Up_Komfort : 6|1@1+ (1,0) [0|1] ""  Gateway_PQ35,Gateway_PQ46
 SG_ TM1_TM_Error_flag : 7|1@1+ (1,0) [0|1] ""  Gateway_PQ35,Gateway_PQ46

BO_ 1449 mTM_2: 1 Telematik_Basis
 SG_ TM2_Warnblink : 0|1@1+ (1,0) [0|1] ""  Gateway_PQ35,Gateway_PQ46
 SG_ TM2_Signalhorn : 1|1@1+ (1,0) [0|1] ""  Gateway_PQ35,Gateway_PQ46
 SG_ TM2_Lock : 2|1@1+ (1,0) [0|1] ""  Gateway_PQ35,Gateway_PQ46
 SG_ TM2_Unlock : 3|1@1+ (1,0) [0|1] ""  Gateway_PQ35,Gateway_PQ46

BO_ 1745 mTP_DAB_Radio: 8 SDARS_Tuner
 SG_ TP_DAB_Radio : 0|64@1+ (1,0) [0|4294967295] ""  Radio_2DIN,Radio_SKODA,RNS_MFD2

BO_ 1244 mTP_Dyn_DAB_1: 8 Gateway_PQ35
 SG_ TPDyn_DAB_1 : 0|64@1+ (1,0) [0|4294967295] ""  SDARS_Tuner

BO_ 1245 mTP_Dyn_DAB_2: 8 Gateway_PQ35
 SG_ mTPDyn_DAB_2 : 0|64@1+ (1,0) [0|4294967295] ""  SDARS_Tuner

BO_ 768 mTP_Dyn_Diag_1_1: 8 Booster_AMP
 SG_ TPDyn_Diag_1_1 : 0|64@1+ (1,0) [0|4294967295] ""  Gateway_PQ35,Gateway_PQ46

BO_ 769 mTP_Dyn_Diag_1_2: 8 Booster_AMP
 SG_ TPDyn_Diag_1_2 : 0|64@1+ (1,0) [0|4294967295] ""  Gateway_PQ35,Gateway_PQ46

BO_ 770 mTP_Dyn_Diag_1_3: 8 Booster_AMP
 SG_ TPDyn_Diag_1_3 : 0|64@1+ (1,0) [0|4294967295] ""  Gateway_PQ35,Gateway_PQ46

BO_ 771 mTP_Dyn_Diag_1_4: 8 Booster_AMP
 SG_ TPDyn_Diag_1_4 : 0|64@1+ (1,0) [0|4294967295] ""  Gateway_PQ35,Gateway_PQ46

BO_ 772 mTP_Dyn_Diag_1_5: 8 Booster_AMP
 SG_ TPDyn_Diag_1_5 : 0|64@1+ (1,0) [0|4294967295] ""  Gateway_PQ35,Gateway_PQ46

BO_ 773 mTP_Dyn_Diag_1_6: 8 Booster_AMP
 SG_ TPDyn_Diag_1_6 : 0|64@1+ (1,0) [0|4294967295] ""  Gateway_PQ35,Gateway_PQ46

BO_ 774 mTP_Dyn_Diag_1_7: 8 Booster_AMP
 SG_ TPDyn_Diag_1_7 : 0|64@1+ (1,0) [0|4294967295] ""  Gateway_PQ35,Gateway_PQ46

BO_ 775 mTP_Dyn_Diag_1_8: 8 Booster_AMP
 SG_ TPDyn_Diag_1_8 : 0|64@1+ (1,0) [0|4294967295] ""  Gateway_PQ35,Gateway_PQ46

BO_ 1246 mTP_Dyn_DSP_1: 8 Gateway_PQ35
 SG_ TPDyn_DSP_1 : 0|64@1+ (1,0) [0|4294967295] ""  Booster_AMP,DSP_SKODA

BO_ 1247 mTP_Dyn_DSP_2: 8 Gateway_PQ35
 SG_ TPDyn_DSP_2 : 0|64@1+ (1,0) [0|4294967295] ""  Booster_AMP,DSP_SKODA

BO_ 1232 mTP_Dyn_Grafik_1: 8 Standheizung
 SG_ TPDyn_Grafik_1 : 0|64@1+ (1,0) [0|4294967295] ""  Gateway_PQ35,Gateway_PQ46

BO_ 1233 mTP_Dyn_Grafik_2: 8 Standheizung
 SG_ TPDyn_Grafik_2 : 0|64@1+ (1,0) [0|4294967295] ""  Gateway_PQ35,Gateway_PQ46

BO_ 1234 mTP_Dyn_Grafik_3: 8 Standheizung
 SG_ TPDyn_Grafik_3 : 0|64@1+ (1,0) [0|4294967295] ""  Gateway_PQ35,Gateway_PQ46

BO_ 1235 mTP_Dyn_Grafik_4: 8 Standheizung
 SG_ TPDyn_Grafik_4 : 0|64@1+ (1,0) [0|4294967295] ""  Gateway_PQ35,Gateway_PQ46

BO_ 1279 mTP_Dyn_GSM_Pager_1: 8 Gateway_PQ35
 SG_ TPDyn_GSM_1 : 0|64@1+ (1,0) [0|4294967295] ""  GSM_Pager

BO_ 720 mTP_Dyn_Informationselektronik_1: 8 Gateway_PQ35
 SG_ TPDyn_Info_1 : 0|64@1+ (1,0) [0|4294967295] "" Vector__XXX

BO_ 721 mTP_Dyn_Informationselektronik_2: 8 Gateway_PQ35
 SG_ TPDyn_Info_2 : 0|64@1+ (1,0) [0|4294967295] "" Vector__XXX

BO_ 1250 mTP_Dyn_Kompass_1: 8 Gateway_PQ35
 SG_ TPDyn_Kompass_1 : 0|64@1+ (1,0) [0|4294967295] ""  Kompassmodul

BO_ 1251 mTP_Dyn_Kompass_2: 8 Gateway_PQ35
 SG_ TPDyn_Kompass_2 : 0|64@1+ (1,0) [0|4294967295] ""  Kompassmodul

BO_ 1260 mTP_Dyn_MDI_1: 8 Gateway_PQ35
 SG_ TPDyn_MDI_1 : 0|64@1+ (1,0) [0|4294967295] ""  MDI

BO_ 1240 mTP_Dyn_Navigation_1: 8 Gateway_PQ35
 SG_ TPDyn_Navi_1 : 0|64@1+ (1,0) [0|4294967295] ""  RNS_MFD2,RNS_midline

BO_ 1241 mTP_Dyn_Navigation_2: 8 Gateway_PQ35
 SG_ TPDyn_Navi_2 : 0|64@1+ (1,0) [0|4294967295] ""  RNS_MFD2,RNS_midline

BO_ 1242 mTP_Dyn_Radio_1: 8 Gateway_PQ35
 SG_ TPDyn_Radio_1 : 0|64@1+ (1,0) [0|4294967295] ""  Radio_2DIN,Radio_Modul,Radio_SKODA,RNS_MFD2,RNS_midline

BO_ 1243 mTP_Dyn_Radio_2: 8 Gateway_PQ35
 SG_ TPDyn_Radio_2 : 0|64@1+ (1,0) [0|4294967295] ""  Radio_2DIN,Radio_Modul,Radio_SKODA,RNS_midline

BO_ 1276 mTP_Dyn_Rearview_1: 8 Gateway_PQ35
 SG_ TPDyn_Rearview_1 : 0|64@1+ (1,0) [0|4294967295] ""  Rearview

BO_ 1277 mTP_Dyn_Rearview_2: 8 Gateway_PQ35
 SG_ TPDyn_Rearview_2 : 0|64@1+ (1,0) [0|4294967295] ""  Rearview

BO_ 1248 mTP_Dyn_SBS_1: 8 Gateway_PQ35
 SG_ TPDyn_SBS_1 : 0|64@1+ (1,0) [0|4294967295] ""  Sprachbedienung

BO_ 1249 mTP_Dyn_SBS_2: 8 Gateway_PQ35
 SG_ TPDyn_SBS_2 : 0|64@1+ (1,0) [0|4294967295] ""  Sprachbedienung

BO_ 804 mTP_Dyn_SH_1: 8 Gateway_PQ35
 SG_ TPDyn_SH_1 : 0|64@1+ (1,0) [0|4294967295] ""  Standheizung

BO_ 805 mTP_Dyn_SH_2: 8 Gateway_PQ35
 SG_ TPDyn_SH_2 : 0|64@1+ (1,0) [0|4294967295] ""  Standheizung

BO_ 1270 mTP_Dyn_Tastatur_1: 8 Gateway_PQ35
 SG_ TPDyn_Tastatur_1 : 0|64@1+ (1,0) [0|4294967295] ""  Tastatur

BO_ 1271 mTP_Dyn_Tastatur_2: 8 Gateway_PQ35
 SG_ TPDyn_Tastatur_2 : 0|64@1+ (1,0) [0|4294967295] ""  Tastatur

BO_ 1264 mTP_Dyn_Telefon_1: 8 Gateway_PQ35
 SG_ TPDyn_Telefon_1 : 0|64@1+ (1,0) [0|4294967295] ""  UHV_High,UHV_low,UHV_Premium

BO_ 1265 mTP_Dyn_Telefon_2: 8 Gateway_PQ35
 SG_ TPDyn_Telefon_2 : 0|64@1+ (1,0) [0|4294967295] ""  UHV_low,UHV_Premium

BO_ 1268 mTP_Dyn_Telematik_1: 8 Gateway_PQ35
 SG_ TPDyn_Telematik_1 : 0|64@1+ (1,0) [0|4294967295] ""  Telematik_Basis

BO_ 1269 mTP_Dyn_Telematik_2: 8 Gateway_PQ35
 SG_ TPDyn_Telematik_2 : 0|64@1+ (1,0) [0|4294967295] ""  Telematik_Basis

BO_ 1272 mTP_Dyn_TV_1: 8 Gateway_PQ35
 SG_ TPDyn_TV_1 : 0|64@1+ (1,0) [0|4294967295] ""  TV_hybrid

BO_ 1273 mTP_Dyn_TV_2: 8 Gateway_PQ35
 SG_ TPDyn_TV_2 : 0|64@1+ (1,0) [0|4294967295] ""  TV_hybrid

BO_ 591 mTP_Er_DAB_Tuner: 7 SDARS_Tuner
 SG_ DAB_TP_Er : 0|56@1+ (1,0) [0|4294967295] ""  Gateway_PQ35,Gateway_PQ46,Radio_2DIN,Radio_SKODA

BO_ 595 mTP_Er_DSP: 7 Booster_AMP
 SG_ DSP_TP_Er : 0|56@1+ (1,0) [0|4294967295] ""  Gateway_PQ35,Gateway_PQ46

BO_ 584 mTP_Er_Grafik: 7 Gateway_PQ35
 SG_ Grafik_TP_Er : 0|56@1+ (1,0) [0|4294967295] "" Vector__XXX

BO_ 577 mTP_Er_GSM_Pager: 7 GSM_Pager
 SG_ GSM_TP_Er : 0|56@1+ (1,0) [0|4294967295] ""  Gateway_PQ35,Gateway_PQ46

BO_ 589 mTP_Er_Informationselektronik_1: 7 Vector__XXX
 SG_ Informationselektronik1_TP_Er : 0|56@1+ (1,0) [0|4294967295] ""  Gateway_PQ35,Gateway_PQ46

BO_ 576 mTP_Er_Kompass: 7 Kompassmodul
 SG_ Kompass_TP_Er : 0|56@1+ (1,0) [0|4294967295] ""  Gateway_PQ35,Gateway_PQ46

BO_ 596 mTP_Er_MDI: 7 MDI
 SG_ MDI_TP_Er : 0|56@1+ (1,0) [0|4294967295] ""  Gateway_PQ35,Gateway_PQ46

BO_ 603 mTP_Er_Navigation: 7 RNS_MFD2
 SG_ Navi_TP_Er : 0|56@1+ (1,0) [0|4294967295] ""  Gateway_PQ35,Gateway_PQ46

BO_ 594 mTP_Er_Radio: 7 Radio_2DIN
 SG_ Radio_TP_Er : 0|56@1+ (1,0) [0|4294967295] ""  Gateway_PQ35,Gateway_PQ46

BO_ 585 mTP_Er_Rearview: 7 Rearview
 SG_ Rearview_TP_Er : 0|56@1+ (1,0) [0|4294967295] ""  Gateway_PQ35,Gateway_PQ46

BO_ 604 mTP_Er_SBS: 7 Sprachbedienung
 SG_ SBS_TP_Er : 0|56@1+ (1,0) [0|4294967295] ""  Gateway_PQ35,Gateway_PQ46

BO_ 559 mTP_Er_SH: 7 Standheizung
 SG_ SH_TP_Er : 0|56@1+ (1,0) [0|4294967295] ""  Gateway_PQ35,Gateway_PQ46

BO_ 587 mTP_Er_Tastatur: 7 Tastatur
 SG_ Tastatur_TP_Er : 0|56@1+ (1,0) [0|4294967295] ""  Gateway_PQ35,Gateway_PQ46

BO_ 602 mTP_Er_Telefon: 7 UHV_High
 SG_ Telefon_TP_Er : 0|56@1+ (1,0) [0|4294967295] ""  Gateway_PQ35,Gateway_PQ46

BO_ 597 mTP_Er_Telematik: 7 Telematik_Basis
 SG_ TM_TP_Er_Telematik : 0|56@1+ (1,0) [0|4294967295] ""  Gateway_PQ35,Gateway_PQ46

BO_ 512 mTP_Er_Tester: 7 Gateway_PQ35
 SG_ Tester_TP_Er : 0|56@1+ (1,0) [0|4294967295] ""  Booster_AMP,DSP_SKODA,GSM_Pager,Kompassmodul,MDI,Radio_2DIN,Radio_Modul,Radio_SKODA,Rearview,RNS_MFD2,RNS_midline,SDARS_Tuner,Sprachbedienung,Standheizung,Tastatur,Telematik_Basis,TV_hybrid,UHV_High,UHV_low,UHV_Premium

BO_ 599 mTP_Er_TV_Tuner: 7 TV_hybrid
 SG_ TV_A_TP_Er : 0|56@1+ (1,0) [0|4294967295] ""  Gateway_PQ35,Gateway_PQ46

BO_ 1729 mTp_KOM_NSL: 8 Gateway_PQ35
 SG_ DISP_KOM_NSL : 0|64@1+ (1,0) [0|4294967295] "" Vector__XXX

BO_ 1731 mTp_KOM_TM: 8 Gateway_PQ35
 SG_ DISP_KOM_TM : 0|64@1+ (1,0) [0|4294967295] "" Vector__XXX

BO_ 1728 mTp_NSL_KOM: 8 Vector__XXX
 SG_ DISP_NSL_KOM : 0|64@1+ (1,0) [0|4294967295] ""  Gateway_PQ35,Gateway_PQ46

BO_ 1744 mTP_Radio_DAB: 8 Radio_2DIN
 SG_ TPRadio_DAB : 0|64@1+ (1,0) [0|4294967295] ""  SDARS_Tuner

BO_ 1673 mTP_Stat_Grafik_Kompass: 8 Gateway_PQ35
 SG_ TPStat_Grafik_Kompass : 0|64@1+ (1,0) [0|4294967295] ""  Kompassmodul

BO_ 1665 mTP_Stat_Grafik_Radio: 8 Gateway_PQ35
 SG_ TPStat_Grafik_Radio : 0|64@1+ (1,0) [0|4294967295] ""  Radio_2DIN,Radio_Modul,Radio_SKODA,RNS_300_NF,RNS_MFD2,RNS_midline

BO_ 1667 mTP_Stat_Grafik_RNS: 8 Gateway_PQ35
 SG_ TPStat_Grafik_RNS : 0|64@1+ (1,0) [0|4294967295] ""  RNS_300_NF,RNS_MFD2,RNS_midline

BO_ 1669 mTP_Stat_Grafik_Telefon: 8 Gateway_PQ35
 SG_ TPStat_Grafik_Telefon : 0|64@1+ (1,0) [0|4294967295] ""  UHV_Premium

BO_ 1671 mTP_Stat_Grafik_Telematik: 8 Gateway_PQ35
 SG_ TPStat_Grafik_Telematik : 0|64@1+ (1,0) [0|4294967295] ""  Telematik_Basis

BO_ 1672 mTP_Stat_Kompass_Grafik: 8 Kompassmodul
 SG_ TPStat_Kompass_Grafik : 0|64@1+ (1,0) [0|4294967295] ""  Gateway_PQ35,Gateway_PQ46

BO_ 1664 mTP_Stat_Radio_Grafik: 8 Radio_2DIN
 SG_ TPStat_Radio_Grafik : 0|64@1+ (1,0) [0|4294967295] ""  Gateway_PQ35,Gateway_PQ46

BO_ 1666 mTP_Stat_RNS_Grafik: 8 RNS_300_NF
 SG_ TPStat_RNS_Grafik : 0|64@1+ (1,0) [0|4294967295] ""  Gateway_PQ35,Gateway_PQ46

BO_ 1668 mTP_Stat_Telefon_Grafik: 8 UHV_Premium
 SG_ TPStat_Telefon_Grafik : 0|64@1+ (1,0) [0|4294967295] ""  Gateway_PQ35,Gateway_PQ46

BO_ 1670 mTP_Stat_Telematik_Grafik: 8 Telematik_Basis
 SG_ TPStat_Telematik_Grafik : 0|64@1+ (1,0) [0|4294967295] ""  Gateway_PQ35,Gateway_PQ46

BO_ 1730 mTp_TM_KOM: 8 Vector__XXX
 SG_ DISP_TM_KOM : 0|64@1+ (1,0) [0|4294967295] ""  Gateway_PQ35,Gateway_PQ46

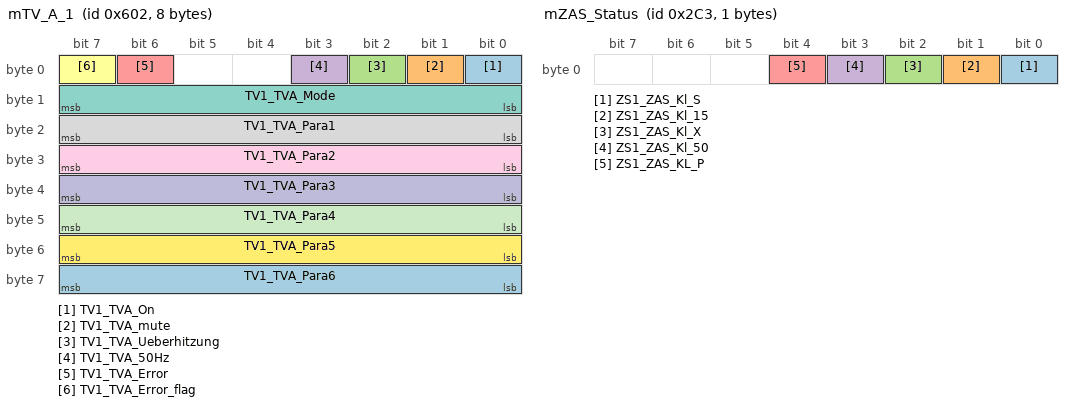
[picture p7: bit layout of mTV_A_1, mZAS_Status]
BO_ 1538 mTV_A_1: 8 TV_hybrid
 SG_ TV1_TVA_On : 0|1@1+ (1,0) [0|1] ""  Rearview,RNS_MFD2
 SG_ TV1_TVA_mute : 1|1@1+ (1,0) [0|1] ""  RNS_MFD2
 SG_ TV1_TVA_Ueberhitzung : 2|1@1+ (1,0) [0|1] ""  RNS_MFD2
 SG_ TV1_TVA_50Hz : 3|1@1+ (1,0) [0|1] ""  RNS_MFD2
 SG_ TV1_TVA_Error : 6|1@1+ (1,0) [0|1] ""  RNS_MFD2,RNS_midline
 SG_ TV1_TVA_Error_flag : 7|1@1+ (1,0) [0|1] ""  Gateway_PQ35,Gateway_PQ46
 SG_ TV1_TVA_Mode : 8|8@1+ (1,0) [0|255] ""  RNS_MFD2
 SG_ TV1_TVA_Para1 : 16|8@1+ (1,0) [0|255] ""  RNS_MFD2
 SG_ TV1_TVA_Para2 : 24|8@1+ (1,0) [0|255] ""  RNS_MFD2
 SG_ TV1_TVA_Para3 : 32|8@1+ (1,0) [0|255] ""  RNS_MFD2
 SG_ TV1_TVA_Para4 : 40|8@1+ (1,0) [0|255] ""  RNS_MFD2
 SG_ TV1_TVA_Para5 : 48|8@1+ (1,0) [0|255] ""  RNS_MFD2
 SG_ TV1_TVA_Para6 : 56|8@1+ (1,0) [0|255] ""  RNS_MFD2

BO_ 1497 mVSG_1: 6 Gateway_PQ35
 SG_ VS1_FH_FT_hoch : 0|1@1+ (1,0) [0|1] "" Vector__XXX
 SG_ VS1_FH_FT_tief : 1|1@1+ (1,0) [0|1] "" Vector__XXX
 SG_ VS1_FH_BT_hoch : 2|1@1+ (1,0) [0|1] "" Vector__XXX
 SG_ VS1_FH_BT_tief : 3|1@1+ (1,0) [0|1] "" Vector__XXX
 SG_ VS1_FH_HL_hoch : 4|1@1+ (1,0) [0|1] "" Vector__XXX
 SG_ VS1_FH_HL_tief : 5|1@1+ (1,0) [0|1] "" Vector__XXX
 SG_ VS1_FH_HR_hoch : 6|1@1+ (1,0) [0|1] "" Vector__XXX
 SG_ VS1_FH_HR_tief : 7|1@1+ (1,0) [0|1] "" Vector__XXX
 SG_ VS1_Freigabe_FH : 8|1@1+ (1,0) [0|1] "" Vector__XXX
 SG_ VS1_ZV_auf : 9|1@1+ (1,0) [0|1] "" Vector__XXX
 SG_ VS1_ZV_zu : 10|1@1+ (1,0) [0|1] "" Vector__XXX
 SG_ VS1_Heckschloss_auf : 11|1@1+ (1,0) [0|1] "" Vector__XXX
 SG_ VS1_auf_Verriegelung : 12|1@1+ (1,0) [0|1] "" Vector__XXX
 SG_ VS1_zu_Verriegelung : 13|1@1+ (1,0) [0|1] "" Vector__XXX
 SG_ VS1_Sperren : 14|1@1+ (1,0) [0|1] "" Vector__XXX
 SG_ VS1_zent_FH_Schalter : 15|1@1+ (1,0) [0|1] "" Vector__XXX
 SG_ VS1_VD_zu_ver : 16|1@1+ (1,0) [0|1] ""  Kompassmodul
 SG_ VS1_VD_entriegelt : 17|1@1+ (1,0) [0|1] "" Vector__XXX
 SG_ VS1_VD_offen_ver : 18|1@1+ (1,0) [0|1] ""  Kompassmodul
 SG_ VS1_VD_Zwischenposition : 19|1@1+ (1,0) [0|1] "" Vector__XXX
 SG_ VS1_VD_Bew_auf : 20|1@1+ (1,0) [0|1] "" Vector__XXX
 SG_ VS1_VD_Bew_zu : 21|1@1+ (1,0) [0|1] "" Vector__XXX
 SG_ VS1_Verdeck_Anf : 22|1@1+ (1,0) [0|1] "" Vector__XXX
 SG_ VS1_Hardtop : 23|1@1+ (1,0) [0|1] "" Vector__XXX
 SG_ VS1_VD_Fehler : 24|1@1+ (1,0) [0|1] "" Vector__XXX
 SG_ VS1_Lampe_Blk : 25|1@1+ (1,0) [0|1] "" Vector__XXX
 SG_ VS1_Text_3 : 26|1@1+ (1,0) [0|1] "" Vector__XXX
 SG_ VS1_Buzzer : 27|1@1+ (1,0) [0|1] "" Vector__XXX
 SG_ VS1_HHS_enable : 28|1@1+ (1,0) [0|1] "" Vector__XXX
 SG_ VS1_VDKD_auf : 29|1@1+ (1,0) [0|1] "" Vector__XXX
 SG_ VS1_Text_1 : 30|1@1+ (1,0) [0|1] "" Vector__XXX
 SG_ VS1_KD_Fehler : 31|1@1+ (1,0) [0|1] "" Vector__XXX
 SG_ VS1_LED : 32|1@1+ (1,0) [0|1] "" Vector__XXX
 SG_ VS1_Blink_LED : 33|1@1+ (1,0) [0|1] "" Vector__XXX
 SG_ VS1_1_Akustik : 34|1@1+ (1,0) [0|1] "" Vector__XXX
 SG_ VS1_2_Akustik : 35|1@1+ (1,0) [0|1] "" Vector__XXX
 SG_ VS1_3_Akustik : 36|1@1+ (1,0) [0|1] "" Vector__XXX
 SG_ VS1_Verdeckbetrieb : 37|1@1+ (1,0) [0|1] "" Vector__XXX
 SG_ VS1_ZZH_offen : 38|1@1+ (1,0) [0|1] "" Vector__XXX
 SG_ VS1_Text_2 : 39|1@1+ (1,0) [0|1] "" Vector__XXX
 SG_ VS1_Texte : 40|5@1+ (1,0) [0|31] "" Vector__XXX

BO_ 707 mZAS_Status: 1 Gateway_PQ35
 SG_ ZS1_ZAS_Kl_S : 0|1@1+ (1,0) [0|1] "" Vector__XXX
 SG_ ZS1_ZAS_Kl_15 : 1|1@1+ (1,0) [0|1] "" Vector__XXX
 SG_ ZS1_ZAS_Kl_X : 2|1@1+ (1,0) [0|1] "" Vector__XXX
 SG_ ZS1_ZAS_Kl_50 : 3|1@1+ (1,0) [0|1] "" Vector__XXX
 SG_ ZS1_ZAS_KL_P : 4|1@1+ (1,0) [0|1] "" Vector__XXX

BO_TX_BU_ 1349 : Gateway_PQ35,Gateway_PQ46;
BO_TX_BU_ 1355 : Gateway_PQ35,Gateway_PQ46;
BO_TX_BU_ 865 : Radio_2DIN,Radio_Modul,Radio_SKODA,RNS_300_NF,RNS_MFD2,RNS_midline;
BO_TX_BU_ 1633 : Radio_2DIN,Radio_Modul,Radio_SKODA,RNS_300_NF,RNS_MFD2,RNS_midline;
BO_TX_BU_ 1451 : Sprachbedienung,Telematik_Basis;
BO_TX_BU_ 1621 : Gateway_PQ35,Gateway_PQ46;
BO_TX_BU_ 1617 : Gateway_PQ35,Gateway_PQ46;
BO_TX_BU_ 1637 : UHV_High,UHV_low,UHV_NAR,UHV_Premium,UHV_UMTS;
BO_TX_BU_ 1244 : Gateway_PQ35,Gateway_PQ46,Radio_2DIN,Radio_SKODA;
BO_TX_BU_ 1245 : Gateway_PQ35,Gateway_PQ46,Radio_2DIN,Radio_SKODA;
BO_TX_BU_ 768 : Booster_AMP,DSP_SKODA,GSM_Pager,Kompassmodul,MDI,Radio_2DIN,Radio_Modul,Radio_SKODA,Rearview,RNS_MFD2,RNS_midline,Sprachbedienung,Standheizung,Tastatur,Telematik_Basis,TV_hybrid,UHV_High,UHV_low,UHV_Premium;
BO_TX_BU_ 769 : Booster_AMP,DSP_SKODA,GSM_Pager,Kompassmodul,MDI,Radio_2DIN,Radio_Modul,Radio_SKODA,Rearview,RNS_MFD2,RNS_midline,Sprachbedienung,Standheizung,Tastatur,Telematik_Basis,TV_hybrid,UHV_High,UHV_low,UHV_Premium;
BO_TX_BU_ 770 : Booster_AMP,DSP_SKODA,GSM_Pager,Kompassmodul,MDI,Radio_2DIN,Radio_Modul,Radio_SKODA,Rearview,RNS_MFD2,RNS_midline,Sprachbedienung,Standheizung,Tastatur,Telematik_Basis,TV_hybrid,UHV_High,UHV_low,UHV_Premium;
BO_TX_BU_ 771 : Booster_AMP,DSP_SKODA,GSM_Pager,Kompassmodul,MDI,Radio_2DIN,Radio_Modul,Radio_SKODA,Rearview,RNS_MFD2,RNS_midline,Sprachbedienung,Standheizung,Tastatur,Telematik_Basis,TV_hybrid,UHV_High,UHV_low,UHV_Premium;
BO_TX_BU_ 772 : Booster_AMP,DSP_SKODA,GSM_Pager,Kompassmodul,MDI,Radio_2DIN,Radio_Modul,Radio_SKODA,Rearview,RNS_MFD2,RNS_midline,Sprachbedienung,Standheizung,Tastatur,Telematik_Basis,TV_hybrid,UHV_High,UHV_low,UHV_Premium;
BO_TX_BU_ 773 : Booster_AMP,DSP_SKODA,GSM_Pager,Kompassmodul,MDI,Radio_2DIN,Radio_Modul,Radio_SKODA,Rearview,RNS_MFD2,RNS_midline,Sprachbedienung,Standheizung,Tastatur,Telematik_Basis,TV_hybrid,UHV_High,UHV_low,UHV_Premium;
BO_TX_BU_ 774 : Booster_AMP,DSP_SKODA,GSM_Pager,Kompassmodul,MDI,Radio_2DIN,Radio_Modul,Radio_SKODA,Rearview,RNS_MFD2,RNS_midline,Sprachbedienung,Standheizung,Tastatur,Telematik_Basis,TV_hybrid,UHV_High,UHV_low,UHV_Premium;
BO_TX_BU_ 775 : Booster_AMP,DSP_SKODA,GSM_Pager,Kompassmodul,MDI,Radio_2DIN,Radio_Modul,Radio_SKODA,Rearview,RNS_MFD2,RNS_midline,Sprachbedienung,Standheizung,Tastatur,Telematik_Basis,TV_hybrid,UHV_High,UHV_low,UHV_Premium;
BO_TX_BU_ 1246 : Gateway_PQ35,Gateway_PQ46;
BO_TX_BU_ 1247 : Gateway_PQ35,Gateway_PQ46;
BO_TX_BU_ 1279 : Gateway_PQ35,Gateway_PQ46;
BO_TX_BU_ 720 : Gateway_PQ35,Gateway_PQ46;
BO_TX_BU_ 721 : Gateway_PQ35,Gateway_PQ46;
BO_TX_BU_ 1250 : Gateway_PQ35,Gateway_PQ46;
BO_TX_BU_ 1251 : Gateway_PQ35,Gateway_PQ46;
BO_TX_BU_ 1260 : Gateway_PQ35,Gateway_PQ46;
BO_TX_BU_ 1240 : Gateway_PQ35,Gateway_PQ46;
BO_TX_BU_ 1241 : Gateway_PQ35,Gateway_PQ46;
BO_TX_BU_ 1242 : Gateway_PQ35,Gateway_PQ46;
BO_TX_BU_ 1243 : Gateway_PQ35,Gateway_PQ46;
BO_TX_BU_ 1276 : Gateway_PQ35,Gateway_PQ46;
BO_TX_BU_ 1277 : Gateway_PQ35,Gateway_PQ46;
BO_TX_BU_ 1248 : Gateway_PQ35,Gateway_PQ46;
BO_TX_BU_ 1249 : Gateway_PQ35,Gateway_PQ46;
BO_TX_BU_ 804 : Gateway_PQ35,Gateway_PQ46;
BO_TX_BU_ 805 : Gateway_PQ35,Gateway_PQ46;
BO_TX_BU_ 1270 : Gateway_PQ35,Gateway_PQ46,Kompassmodul,RNS_MFD2;
BO_TX_BU_ 1271 : Gateway_PQ35,Gateway_PQ46,Kompassmodul,RNS_MFD2;
BO_TX_BU_ 1264 : Gateway_PQ35,Gateway_PQ46;
BO_TX_BU_ 1265 : Gateway_PQ35,Gateway_PQ46;
BO_TX_BU_ 1268 : Gateway_PQ35,Gateway_PQ46;
BO_TX_BU_ 1269 : Gateway_PQ35,Gateway_PQ46;
BO_TX_BU_ 1272 : Gateway_PQ35,Gateway_PQ46;
BO_TX_BU_ 1273 : Gateway_PQ35,Gateway_PQ46;
BO_TX_BU_ 595 : Booster_AMP,DSP_SKODA;
BO_TX_BU_ 584 : Gateway_PQ35,Gateway_PQ46;
BO_TX_BU_ 603 : RNS_MFD2,RNS_midline;
BO_TX_BU_ 594 : Radio_2DIN,Radio_Modul,Radio_SKODA,RNS_midline;
BO_TX_BU_ 602 : UHV_High,UHV_low,UHV_Premium;
BO_TX_BU_ 512 : Gateway_PQ35,Gateway_PQ46;
BO_TX_BU_ 1729 : Gateway_PQ35,Gateway_PQ46;
BO_TX_BU_ 1731 : Gateway_PQ35,Gateway_PQ46;
BO_TX_BU_ 1744 : Radio_2DIN,Radio_SKODA,RNS_MFD2;
BO_TX_BU_ 1673 : Gateway_PQ35,Gateway_PQ46;
BO_TX_BU_ 1665 : Gateway_PQ35,Gateway_PQ46;
BO_TX_BU_ 1667 : Gateway_PQ35,Gateway_PQ46;
BO_TX_BU_ 1669 : Gateway_PQ35,Gateway_PQ46;
BO_TX_BU_ 1671 : Gateway_PQ35,Gateway_PQ46;
BO_TX_BU_ 1664 : Radio_2DIN,Radio_Modul,Radio_SKODA,RNS_300_NF,RNS_MFD2,RNS_midline;
BO_TX_BU_ 1666 : RNS_300_NF,RNS_MFD2,RNS_midline;
BO_TX_BU_ 1497 : Gateway_PQ35,Gateway_PQ46;
BO_TX_BU_ 707 : Gateway_PQ35,Gateway_PQ46;
CM_ SG_ 1349 PA3_System_codierung "0 = 4 Kanal PDC
1 = 8 Kanal PDC

Bei VW:
0 = hinten
1 = Vorn und Hinten

8/4-Kanal-Anlage";
CM_ SG_ 1349 PA3_Anlage_defekt "1 = PDC wurde aufgrund eines Defektes deaktiviert
Anlage defekt";
CM_ SG_ 1349 PA3_Taster_aktiviert "1 = Anlage wurde manuell ueber Einschalttaster aktiviert
Aktivierung durch Taster (Nur 8-Kanal)";
CM_ SG_ 1349 PA3_Rueckwaertsgang_aktiv "1 = Anlage wurde durch Einlegen des Rueckwaertsgangs aktiviert";
CM_ SG_ 1349 PA3_Geschwindigkeit_aus "1 = Durch Erreichen von vMax PDC wurde die PDC abgeschaltet";
CM_ SG_ 1349 PA3_Tongeber_v_defekt "1 = Tongeber Vorne ist defekt";
CM_ SG_ 1349 PA3_Tongeber_h_defekt "1 = Tongeber Hinten ist defekt";
CM_ SG_ 1349 PA3_Audioabsenkung_Anforderung "1= Anforderung an das Audiosystem fuer Absenkung der Lautstaerke";
CM_ SG_ 1349 PA3_Eis_aus "1 = Wegen erkanntem Eis auf den Sensoren wurde die PDC abgeschaltet";
CM_ SG_ 1349 PA3_Schlechtweg_aus "1 = Aufgrund von signalisierten Schlechtweginformationen wurde die PDC abgeschaltet";
CM_ SG_ 1349 PA3_KD_Fehler "1 = mindestens ein Fehler ist im Kundendienstfehlerspeicher eingetragen";
CM_ SG_ 1349 PA3_Sensor_hll_defekt "0 = Sensor OK / 1 = Sensor defekt
Sensor hinten links links defekt";
CM_ SG_ 1349 PA3_Sensor_hlm_defekt "0 = Sensor OK / 1 = Sensor defekt
Sensor hinten links mitte defekt";
CM_ SG_ 1349 PA3_Sensor_hrm_defekt "0 = Sensor OK / 1 = Sensor defekt
Sensor hinten rechts mitte defekt";
CM_ SG_ 1349 PA3_Sensor_hrr_defekt "0 = Sensor OK / 1 = Sensor defekt
Sensor hinten rechts rechts defekt";
CM_ SG_ 1349 PA3_Sensor_vll_defekt "0 = Sensor OK / 1 = Sensor defekt
Sensor vorn links links defekt";
CM_ SG_ 1349 PA3_Sensor_vlm_defekt "0 = Sensor OK / 1 = Sensor defekt
Sensor vorn links mitte defekt";
CM_ SG_ 1349 PA3_Sensor_vrm_defekt "0 = Sensor OK / 1 = Sensor defekt
Sensor vorn rechts mitte defekt";
CM_ SG_ 1349 PA3_Sensor_vrr_defekt "0 = Sensor OK / 1 = Sensor defekt
Sensor vorn rechts rechts defekt";
CM_ SG_ 1349 PA3_Bereit "1 = PDC ist Betriebsbereit und kann aktiviert werden";
CM_ SG_ 1349 PA3_Bereich_vo "0 = Initwert (Ausserhalb Gefahrenbereich)
1 = Vorwarnbereich nur NFZ
2 = Hauptwarnbereich
3 = Kollisionsbereich
Bereichserkennung vorn";
CM_ SG_ 1349 PA3_Bereich_hi "0 = Initwert (Ausserhalb Gefahrenbereich)
1 = Vorwarnbereich nur NFZ
2 = Hauptwarnbereich
3 = Kollisionsbereich
Bereichserkennung hinten";
CM_ SG_ 1349 PA3_Akust_aus "1 = Tonausgabe der ParkDistanceControll manuell abgeschaltet
Akustische Ausgabe der PDC abschalten";
CM_ SG_ 1349 PA3_Aufbau_erk "Aufbauten erkannt";
CM_ SG_ 1355 PA5_VL_Abstand "FFh = kein Hindernis im Erfassungsbereich
Abstand vorne links";
CM_ SG_ 1355 PA5_VR_Abstand "FFh = kein Hindernis im Erfassungsbereich
Abstand vorne rechts";
CM_ SG_ 1355 PA5_HL_Abstand "FFh = kein Hindernis im Erfassungsbereich
Abstand hinten links";
CM_ SG_ 1355 PA5_HR_Abstand "FFh = kein Hindernis im Erfassungsbereich
Abstand hinten rechts";
CM_ SG_ 1355 PA5_VML_Abstand "FFh = kein Hindernis im Erfassungsbereich
Abstand vorne mitte links";
CM_ SG_ 1355 PA5_VMR_Abstand "FFh = kein Hindernis im Erfassungsbereich
Abstand vorne mitte rechts";
CM_ SG_ 1355 PA5_HML_Abstand "FFh = kein Hindernis im Erfassungsbereich
Abstand hinten mitte links";
CM_ SG_ 1355 PA5_HMR_Abstand "FFh = kein Hindernis im Erfassungsbereich
Abstand hinten mitte rechts";
CM_ SG_ 867 RA1_DSP_Zeichen_1 "Display-Daten fuer das 2 Zeilen Display hier Zeile 1
Display-Daten 1. Zeichen Zeile 1";
CM_ SG_ 867 RA1_DSP_Zeichen_2 "Die Daten werden nach Kl15 ein selbstaendig vom Radio gesendet.
Display-Daten 2. Zeichen Zeile 1";
CM_ SG_ 867 RA1_DSP_Zeichen_3 "Display-Daten 3. Zeichen Zeile 1";
CM_ SG_ 867 RA1_DSP_Zeichen_4 "Display-Daten 4. Zeichen Zeile 1";
CM_ SG_ 867 RA1_DSP_Zeichen_5 "Bei Aenderung sofort mit minimalen Aktualisierungsabstand dt: 50 ms
Display-Daten 5. Zeichen Zeile 1";
CM_ SG_ 867 RA1_DSP_Zeichen_6 "Wenn disp busy oder RA2_Display_disabled Sendung einstellen
Display-Daten 6. Zeichen Zeile 1";
CM_ SG_ 867 RA1_DSP_Zeichen_7 "Display-Daten 7. Zeichen Zeile 1";
CM_ SG_ 867 RA1_DSP_Zeichen_8 "Display-Daten 8. Zeichen Zeile 1";
CM_ SG_ 869 RA2_DSP_Zeichen_9 "Display-Daten fuer das 2 Zeilen Display hier Zeile 2
Display-Daten 1. Zeichen Zeile 2";
CM_ SG_ 869 RA2_DSP_Zeichen_10 "Die Daten werden nach Kl15 ein selbstaendig vom Radio gesendet.
Display-Daten 2. Zeichen Zeile 2";
CM_ SG_ 869 RA2_DSP_Zeichen_11 "Die Daten duerfen nicht gesendet werden, wenn das Telefon
Display-Daten 3. Zeichen Zeile 2";
CM_ SG_ 869 RA2_DSP_Zeichen_12 "aktiv-Bit gesetzt ist.
Display-Daten 4. Zeichen Zeile 2";
CM_ SG_ 869 RA2_DSP_Zeichen_13 "Bei Aenderung sofort mit minimalen Aktualisierungsabstand dt: 50 ms
Display-Daten 5. Zeichen Zeile 2";
CM_ SG_ 869 RA2_DSP_Zeichen_14 "Wenn disp busy oder RA2_Display_disabled Sendung einstellen
Display-Daten 6. Zeichen Zeile 2";
CM_ SG_ 869 RA2_DSP_Zeichen_15 "Display-Daten 7. Zeichen Zeile 2";
CM_ SG_ 869 RA2_DSP_Zeichen_16 "Display-Daten 8. Zeichen Zeile 2";
CM_ BO_ 865 "CAN-Komfort";
CM_ SG_ 865 RA3_Radio_SS_1 "Diese Botschaft wird einmalig nach Kl30 ein gesendet.
Security Acces_Mode_1_Byte_1";
CM_ SG_ 865 RA3_Radio_SS_2 "Security Acces_Mode_1_Byte_2";
CM_ SG_ 865 RA3_Radio_SS_3 "Security Acces_Mode_1_Byte_3";
CM_ SG_ 865 RA3_Radio_SS_4 "Security Acces_Mode_1_Byte_4";
CM_ SG_ 865 RA3_Adress "NM- Adresse - 400h
Fuer Radio= 438h- 400h = 38h
Stationsadresse des anfragenden Clients";
CM_ SG_ 1633 RA4_Radio_on "1 = Radio ein
0 = Radio aus
Radio ist eingeschaltet";
CM_ SG_ 1633 RA4_Show_Radio "1 =Display request
Zur Zeit immer 1 wenn Radio eingeschaltet

VW: Show_Request für Infotainmentinhalt in Kombizeile
Display_requirement_Vorhalt

AU: PowerAmpON (0x0 mute PowerAmp, 0x1 demute PowerAmp)";
CM_ SG_ 1633 RA4_Radio_mute "Vorhalt fuer NF request";
CM_ SG_ 1633 RA4_Radio_Master_locked "1 = Radio gesperrt
0 = Radio freigeschaltet
Radiokomponenten gesperrt nach Kl. 30";
CM_ SG_ 1633 RA4_VNC_OFF "1 = VNC (Vehicle Noice Cancellation) ausgeschaltet
(vorher: RA4_Radio_Audiopilot_OFF, 1 = Audiopilot ausgeschaltet)";
CM_ SG_ 1633 RA4_Radio_Surround "vorher RA4_Radio_Surround_OFF (1 = Surround ausgeschaltet)";
CM_ SG_ 1633 RA4_Radio_Wake_Up_Komfort "Wecken des Komfort-CAN";
CM_ SG_ 1633 RA4_Radio_Error_flag "Fehlereintrag vorhanden";
CM_ SG_ 1633 RA4_Radio_Mode "Mode-Information";
CM_ SG_ 1633 RA4_Radio_Para1 "Parameter des jew. Modes";
CM_ SG_ 1633 RA4_Radio_Para2 "Parameter des jew. Modes";
CM_ SG_ 1633 RA4_Radio_Para3 "Parameter des jew. Modes";
CM_ SG_ 1633 RA4_Radio_Para4 "Parameter des jew. Modes";
CM_ SG_ 1633 RA4_Radio_Para5 "Vorhalt";
CM_ SG_ 1633 RA4_Radio_Para6 "Vorhalt";
CM_ SG_ 1121 RA6_Ziel "Festlegung von Zieladresse (CD, CDW, TV, ..), Comand und
Zieladresse";
CM_ SG_ 1121 RA6_Command "Operand in separater Tabelle: mRadio_MUX_1
Radiobefehl";
CM_ SG_ 1121 RA6_Operand_0 "Operand_0";
CM_ SG_ 1121 RA6_Operand_1 "Operand_1";
CM_ SG_ 1121 RA6_Operand_2 "Operand_2";
CM_ SG_ 1121 RA6_Operand_3 "Operand_3";
CM_ SG_ 1347 RV1_Video_On "1 = Video-Bild ein
0 = Video-Bild aus
Kamerabild wird aufgeschaltet";
CM_ SG_ 1347 RV1_Dark_Screen "0: Kamerabild nicht dunkel geschaltet
1: Kamerabild dunkel geschaltet
Dunkelschalten des RV-Bildes";
CM_ SG_ 1347 RV1_HMI_Mode "0: Parktasche
1: tbd parallel to road
2: reserviert
3: Kalibrierung (nur Diagnose)
Ist-Wert für HMI-Mode";
CM_ SG_ 1347 RV1_System_Aktiv "0: RV System nicht betriebsbereit
1: RV System betriebsbereit
Initialisierungsphase";
CM_ SG_ 1347 RV1_KD_Fehler "Kundendienst-Fehler";
CM_ SG_ 1347 RV1_Settings_Enabled "0: nicht aufgeschaltet
1: aufgeschaltet
Einstellungsmenue";
CM_ SG_ 1347 RV1_Menu_Item "0: HMI-Mode ausgewählt
1: Helligkeit ausgewählt
2: Kontrast ausgewählt
3: Farbsättigung
ausgewähltes Menue-ltem";
CM_ SG_ 1347 RV1_Helligkeit "Ist-Wert für Helligkeit";
CM_ SG_ 1347 RV1_Kontrast "Ist-Wert für Kontrast";
CM_ SG_ 1347 RV1_Farbe "Ist-Wert für Farbe";
CM_ SG_ 1445 SB1_SBS_Destination "logische Zieladressierung
SG-Nummer als Ziel";
CM_ SG_ 1445 SB1_SBS_Funktion "zu startende Funktion in der logischen Einheit
Funktionsnummer";
CM_ SG_ 1445 SB1_SBS_Para1 "Parameter_1 zu der jeweiligen Funktion";
CM_ SG_ 1445 SB1_SBS_Para2 "falls keine Parameter notwendig sind Param_1 bis Param_6 auf 0 zu setzen
Parameter_2 der Funktion";
CM_ SG_ 1445 SB1_SBS_Para3 "Parameter_3 der Funktion";
CM_ SG_ 1445 SB1_SBS_Para4 "Parameter_4 der Funktion";
CM_ SG_ 1445 SB1_SBS_Para5 "Parameter_5 der Funktion";
CM_ SG_ 1445 SB1_SBS_Para6 "Parameter_6 der Funktion";
CM_ SG_ 1451 SB3_SBS_on "Betriebsbereit bei Klemme 15
Sprachbedienung Betriebsbereit";
CM_ SG_ 1451 SB3_Show_SBS "Display-Request durch SBS
Vorhalt fuer Displayanzeige";
CM_ SG_ 1451 SB3_SBS_mute "Bei Spracheingabe =1 wenn NF gemutet
NF-Stummschaltung";
CM_ SG_ 1451 SB3_SBS_com_send "Flag fuer abgesendeten Befehl (Impuls)";
CM_ SG_ 1451 SB3_SBS_active "bei Aktivierung durch PTT=1
SBS Bedienung aktiv";
CM_ SG_ 1451 SB3_SBS_Error_flag "Fehlereintrag liegt vor";
CM_ SG_ 1451 SB3_SBS_Level "Pegel der Lautstaerke am Line_out fuer Schalldruckanpassung
Lautstaerke SBS Line_Out";
CM_ SG_ 1451 SB3_SBS_Display_Vol "Anzeige Lautstärke im Radio Display";
CM_ BO_ 1621 "CAN-Dashboard CAN-Komfort CAN-Infotainment";
CM_ SG_ 1621 VBN_Motor_A "immer 1! (Motorsteuergeraet immer verbaut)";
CM_ SG_ 1621 VBN_Getriebe_A "Sollverbau Getriebesteuergeraet";
CM_ SG_ 1621 VBN_Bremse_A "Sollverbau ABS fuer Schlechtweginformation";
CM_ SG_ 1621 VBN_Kombi_A "1 = Kombi am Antriebs-CAN verbaut";
CM_ SG_ 1621 VBN_LSM_A "Sollverbau Lenkwinkel";
CM_ SG_ 1621 VBN_Airbag_A "Airbag-Steuergerät im CAN-Antrieb-Netzwerk
Anmerkungen: Bit auf 0 heißt nicht verbaut (Sollzustand)
Initwert 'const' bedeutet, daß der kodierte Zustand gesendet wird";
CM_ SG_ 1621 VBN_Lenkhilfe_A "Lenkhilfe (Elektrohydraulische Servolenkung) im CAN-Antrieb-Netzwerk
Anmerkungen: Bit auf 0 heißt nicht verbaut (Sollzustand)
Initwert 'alt' bedeutet, daß der letzte erkannte Zustand gesendet wird (ggfs. 0 nach Klemme 30 Reset)
Clima_VW: Zur Unterschei";
CM_ SG_ 1621 VBN_dyn_LWR_A "Dynamische Leuchtweitenregulierung / AFS";
CM_ SG_ 1621 VBN_Niveau_A "Niveauregulierung am CAN Antrieb";
CM_ SG_ 1621 VBN_Allrad_A "Sollverbau Allrad
";
CM_ SG_ 1621 VBN_ADR_Sensor_A "Sollverbau ADR-Steuergeraet";
CM_ SG_ 1621 VBN_ADR_getrennt "ADR-Sensor kann vom CAN-Antrieb abgetrennt werden:
aktueller Zustand dieses Relais wird übertragen
Initwert 0: Hardware ohne Abtrennmöglichkeit (z. Zt. PQ35)
Initwert 1: Hardware mit bestückbarer Abtrennmöglichkeit (z. Zt. alle PQ46)";
CM_ SG_ 1621 VBN_Parkbremse_A "Parkbremse am CAN-Antrieb, bzw. Bremsen-SUB-CAN";
CM_ SG_ 1621 VBN_EZS_A "EZS Steuergeraet";
CM_ SG_ 1621 VBN_Daempfer_A "Daempfer-SG am CAN Antrieb";
CM_ SG_ 1621 VBN_Quersperre "Quersperre im CAN-Antrieb-Netzwerk";
CM_ SG_ 1621 VBN_Motor_Slave_A "Motor Slave im CAN-Antrieb-Netzwerk";
CM_ SG_ 1621 VBN_SWA_A "SWA Spurwechselassistent";
CM_ SG_ 1621 VBN_LDW_A "LDW / Heading Control am Antriebsstrang";
CM_ SG_ 1621 VBN_RKA_Plus_A "RKA-SG (RKA_Plus) am CAN Antrieb";
CM_ SG_ 1621 VBN_PLA_A "PDC / Park Lenk Assistent am Antiebsstrang";
CM_ SG_ 1621 VBN_WFS_KBI "1 = Wegfahrsperre am Kombi-CAN oder Antriebs-CAN";
CM_ SG_ 1621 VBN_Kombi_KBI "1 = Kombi am Kombi-CAN verbaut";
CM_ SG_ 1621 VBN_Soll_Ist_OK "1 = Sollverbau = Istverbau
0 = Sollverbau ungleich Istverbau";
CM_ SG_ 1621 VBN_BSG_K "Sollverbau BSG_Komfort bzw. ILM_Komfort";
CM_ SG_ 1621 VBN_KSG_K "Sollverbau ZKE";
CM_ SG_ 1621 VBN_TSG_FT_K "Sollverbau TSG_FT";
CM_ SG_ 1621 VBN_TSG_BT_K "Sollverbau TSG_BT";
CM_ SG_ 1621 VBN_TSG_HL_K "Sollverbau TSG_HL";
CM_ SG_ 1621 VBN_TSG_HR_K "Sollverbau TSG_HR";
CM_ SG_ 1621 VBN_Memory_K "Sollverbau Memory";
CM_ SG_ 1621 VBN_Dachmodul_K "Reserviert für Dachmodul / Dachdisplay im CAN-Komfort-Netzwerk
Anmerkungen: Bit auf 0 heißt nicht verbaut (Sollzustand)
Initwert 'const' bedeutet, daß der kodierte Zustand gesendet wird";
CM_ SG_ 1621 VBN_Zentralelektrik_II_K "Sollverbau Zentralelektrik 2 am CAN-Komfort";
CM_ SG_ 1621 VBN_RDK_K "Sollverbau Reifendruck";
CM_ SG_ 1621 VBN_SMLS_K "Sollverbau Lenksaeulenmodul/Multifunktionslenkrad";
CM_ SG_ 1621 VBN_Gateway_K "Sollverbau Gatewaymodul am CAN-Komfort";
CM_ SG_ 1621 VBN_Clima_K "Sollverbau Climasteuerung am CAN-Komfort";
CM_ SG_ 1621 VBN_APS_K "Sollverbau Einparkhilfe";
CM_ SG_ 1621 VBN_PTC_Heizung_K "1 = PTC-Heizung verbaut";
CM_ SG_ 1621 VBN_Standhzg_K "Sollverbau, Standheizung am Komfort oder Infotainment";
CM_ SG_ 1621 VBN_VSG_K "Sollverbau Verdecksteuergeraet";
CM_ SG_ 1621 VBN_RSE_I "Sollverbau Rearseatentertainment";
CM_ SG_ 1621 VBN_Wischer_K "Reserviert für Wischermodul im CAN-Komfort / CAN-Infotainment-Netzwerk
Anmerkungen: Bit auf 0 heißt nicht verbaut (Sollzustand)
Initwert 'const' bedeutet, daß der kodierte Zustand gesendet wird";
CM_ SG_ 1621 VBN_MDI_I "Sollverbau Mobil Device Interface";
CM_ SG_ 1621 VBN_AAG_K "Sollverbau Anhaengermodul";
CM_ SG_ 1621 VBN_Mem_BF_K "Sollverbau Sitzmemory_BF";
CM_ SG_ 1621 VBN_Easy_Entry_VF "Sollverbau Easy Entry Fahrer";
CM_ SG_ 1621 VBN_Easy_Entry_VB "Easy Entry Beifahrer";
CM_ SG_ 1621 VBN_Heckdeckel_K "Verbau des Heckdeckel-Steuergeraetes";
CM_ SG_ 1621 VBN_Rearview_I "Sollverbau, Rearview am Infotainment";
CM_ SG_ 1621 VBN_Sonderfahrzeug_SG_K "Sonderfahrzeug-SG";
CM_ SG_ 1621 VBN_Tastenmodul_I "Sollverbau 10-er Tastatur am CAN-Infotainment";
CM_ SG_ 1621 VBN_Kompass_I "Sollverbau Kompass am CAN-Infotainment";
CM_ SG_ 1621 VBN_WFS_K "1 = Wegfahrsperre am CAN-Komfort verbaut";
CM_ SG_ 1621 VBN_GSM_Pager_I "Sollverbau GSM-Pager am CAN-Infotainment";
CM_ SG_ 1621 VBN_InfoElektronik "Sollverbau Infotainment Cockpit am CAN-Komfort";
CM_ SG_ 1621 VBN_DSP_I "Sollverbau DSP am CAN-Infotainment";
CM_ SG_ 1621 VBN_DAB_I "Sollverbau auch fuer SDARS Tuner";
CM_ SG_ 1621 VBN_Telematik_I "Sollverbau Telematik am CAN-Infotainment";
CM_ SG_ 1621 VBN_Navigation_I "Sollverbau; Fuer RNS werden die BITs Radio und Navigation gesetzt (Logische Komponenten)
Navigation am CAN-Infotainment";
CM_ SG_ 1621 VBN_TV_Tuner_I "Sollverbau TV_Tuner am CAN-Infotainment";
CM_ SG_ 1621 VBN_Neigungsmodul_I "Sollverbau Neigungsmodul am CAN-Infotainment";
CM_ SG_ 1621 VBN_Radio_I "Sollverbau; Fuer RNS werden die BITs Radio und Navigation gesetzt (Logische Komponenten)
Radio am CAN-Infotainment";
CM_ SG_ 1621 VBN_Telefon_I "Sollverbau Telefon am CAN-Infotainment";
CM_ SG_ 997 SH1_Funk_ein "1 = Funkbefehl zum Einschalten erhalten
Signal wird bei Aenderung 5 mal als '1' gesendet und dann auf '0' zurückgesetzt.
Funkbefehl 'Standheizung/-Luefung ein' erhalten";
CM_ SG_ 997 SH1_Funk_aus "1 = Funkbefehl zum Ausschalten erhalten
Signal wird bei Aenderung 5 mal als '1' gesendet und dann auf '0' zurückgesetzt.
Funkbefehl 'Standheizung/-Lueftung aus' erhalten";
CM_ SG_ 997 SH1_FunkSH_Ein "Funkbefehl 'Standheizung ein' erhalten";
CM_ SG_ 997 SH1_FunkStLftg "Funkbefehl 'Standlueftung ein' erhalten";
CM_ SG_ 997 SH1_Clima_aus "Befehl Klimaanlage abschalten";
CM_ SG_ 997 SH1_SH_Modus "0 = Heizgerät ist Standheizung
1 = Heizgerät ist Zuheizer
Befehl Standheizungsmodus aktivieren";
CM_ SG_ 997 SH1_Prog_Modus "1 = Standheizungsprogrammierung aktiv";
CM_ SG_ 997 SH1_Wake_Up_Komfort "1 = Anforderung um den CAN-Komfort zu Wecken, nur unterstuetzt, wenn die Standheizung auf einem anderen CAN verbaut ist.";
CM_ SG_ 997 SH1_Geblaese "1 = Geblaese ein";
CM_ SG_ 997 SH1_LED "1 = Kontroll-LED Standheizung ein";
CM_ SG_ 997 SH1_ZusatzHeizung "0 = Verbrennungszuheizer aus (brennt nicht)
1 = Verbrennungszuheizer ein (brennt)";
CM_ SG_ 997 SH1_ein_Wasserpumpe "1 = Wasserpumpe der Standheizung (gesteuert von der Climatonic) einschalten";
CM_ SG_ 997 SH1_Fehlerstatus "0 = kein Fehler
1 = Battery Low
2 = Fuel Low
3 = HW defekt
4 = Crash
5 = Betriebsstoerung
6 = Ueberhitzung
7 = keine Standheizung beim Tanken
Fehlerstatus Standheizung";
CM_ SG_ 997 SH1_KD_Fehler "1 = mindestens 1 Kundendienstfehler ist im Fehlerspeicher eingetragen";
CM_ SG_ 997 SH1_K_Verbrauch "Kraftstoffsignal";
CM_ SG_ 997 SH1_SH_Verbau "1 = Steuergeraet ist Standheizung, d.h. kann auch ohne Klemme 15 heizen
0 = Steuergeraet ist Zuheizer, d.h. kann nur mit Klemme 15 betrieben werden
Status (Verbau) SH-Steuergeraet";
CM_ SG_ 997 SH1_K_Fehler "1 = Kraftstoffverbrauch Fehler ( Klemme 30 war weg )";
CM_ SG_ 997 SH1_Heizleistung "Heizleistung";
CM_ SG_ 997 SH1_HeizkreisTemp "FF = Fehler
aktuelle Heizkreistemperatur fuer Standheizungskreislauf";
CM_ SG_ 997 SH1_Pumpe_on "Wenn das Signal auf 1 ist, ist die Kraftstoffpumpe eingeschaltet, d.h. Standheizung arbeitet im Heizbetrieb. Bei 0 Erfolgt keine Heizleistung der Standheizung, d.h. im Betriebsfall ist nur die Lüftung aktiv.
Kraftstoffpumpe ein";
CM_ SG_ 997 SH1_KW_Warm "Bit zeigt an, dass die Standheizung das Wasser im Heizungskreislauf erwaermt hat und dieses in den Kuehlkreislauf des Motors abgibt bzw. kuerzlich abgegeben hat.
Kuehlwasser erwaermt";
CM_ SG_ 997 SH1_Lueften "1= Standlueften aktiv";
CM_ BO_ 1617 "CAN-Dashboard CAN-Komfort CAN-Infotainment";
CM_ SG_ 1617 SY1_CAN_Extern "zweipoliger Schalter, der den CAN-Antrieb auf den Diagnosestecker legt, ist geschlossen oder es werden Nutzdaten des CAN-Antrieb auf den Diagnose-CAN gespiegelt
CAN-Extern zugeschaltet";
CM_ SG_ 1617 SY1_Diag_Antrieb "mindestens ein Teilnehmer hat die Diagnoseeröffnung auf dem CAN bestätigt; im PQ35/46 derzeit nicht unterstützt
CAN-Antrieb in Diagnose";
CM_ SG_ 1617 SY1_Sleep_Komfort "CAN-Komfort-Netzwerk schläft";
CM_ SG_ 1617 SY1_Diag_Komfort "mindestens ein Teilnehmer hat die Diagnoseeröffnung auf dem Komfort-CAN bestätigt; im PQ35/46 derzeit nicht unterstützt
CAN-Komfort in Diagnose";
CM_ SG_ 1617 SY1_Sleep_Infotainment "CAN-Infotainment-Netzwerk schläft";
CM_ SG_ 1617 SY1_Diag_Infotainment "mindestens ein Teilnehmer hat die Diagnoseeröffnung auf dem Infotainment-CAN bestätigt; im PQ35/46 derzeit nicht unterstützt
CAN-Infotainment in Diagnose";
CM_ SG_ 1617 SY1_Infotainment "der CAN-Infotainment ist vom CAN-Komfort physikalisch getrennt";
CM_ SG_ 1617 SY1_Verbauliste_gueltig "ungültig bedeutet: Verbauinformation ist noch nicht vollständig: Gateway nicht kodiert";
CM_ SG_ 1617 SY1_Klasse "bei PQ24 wird z.Zt. A0-Klasse ausgegeben
Fahrzeug-Klasse";
CM_ SG_ 1617 SY1_Marke "Marke wird im Gateway-SG kodiert: Unkodierte PQ35-Gateway-SG geben '1' aus
Fahrzeug-Marke";
CM_ SG_ 1617 SY1_Derivat "Achtung: Derivate, die sich im Bordnetz nicht unterscheiden, werden ggfs. zusammengefaßt
Derivat wird im Gateway-SG kodiert
Unkodierte PQ35/46-Gateway-SG geben 15d aus
0 = Kurzheck oder Multivan
1 = Stufenheck oder Nutzfzg.
2 = Variant
3 = Fliesshec";
CM_ SG_ 1617 SY1_Generation "z.B. 5 für PQ35
Fahrzeug-Generation";
CM_ SG_ 1617 SY1_Erweiterung "Im PQ35/46 derzeit nicht unterstützt: 15d für 'nicht bekannt' wird ausgegeben";
CM_ SG_ 1617 SY1_Rechtslenker "Info wird im Gateway-SG kodiert
Unkodierte PQ35/46-Gateway-SG geben 0 aus";
CM_ SG_ 1617 SY1_Viertuerer "Info wird im Gateway-SG kodiert
Unkodierte PQ35/46-Gateway-SG geben 0 aus";
CM_ SG_ 1617 SY1_Transportmode "1 = Transportmodus aktiv, funktionale Einschränkungen bzw. Änderungen für den Fzg.-Transport";
CM_ SG_ 1617 SY1_KD_Fehler "Bei gesetztem Bit ist mindestens ein KD-Fehler unter der Gateway Adresse abgelegt";
CM_ SG_ 1617 SY1_VersLowCAN_Komfort "Anmerkung: das Gateway-Steuergerät erfüllt die Funktionalität dieser CAN-Version
CAN-Stand Komfort-Daten-Nebenversion";
CM_ SG_ 1617 SY1_VersHighCAN_Komfort "Anmerkung: das Gateway-Steuergerät erfüllt die Funktionalität dieser CAN-Version
CAN-Stand Komfort-Daten-Hauptversion";
CM_ SG_ 1617 SY1_VersLowCAN_Antrieb "Anmerkung: das Gateway-Steuergerät erfüllt die Funktionalität dieser CAN-Version
CAN-Stand Antrieb-Daten-Nebenversion";
CM_ SG_ 1617 SY1_VersHighCAN_Antrieb "Anmerkung: das Gateway-Steuergerät erfüllt die Funktionalität dieser CAN-Version
CAN-Stand Antrieb-Daten-Hauptversion";
CM_ SG_ 1617 SY1_Relais_FAS_Zweig "FAS-Zweig (mit ACC, SWA,...) wird vom CAN-Antrieb über ein Relais abgetrennt:
01: gewolltes Abschalten (zu schützende Kommunikation, z. B. im Hochlauf)
10: nach zweimaligem BusOff bis 'Kl. 15' aus abgetrennt
(im PQ46 und Touareg GP, D1GP/BY61x)
Hinwei";
CM_ SG_ 1617 SY1_ELV_Lock_Supply "Gateway gibt eine zusätzliche Freigabe für die ELV (elektrische Lenkradverriegelung) (z. Zt. nur PQ46)";
CM_ SG_ 1617 SY1_QRS_Messmodus "1 = Quick-Ruhestrommessmodus (früher: Fabrikmodus), Fzg geht innerhalb 1min in Ruhestrom
siehe auch Lastenheft LH_TRM_QRS";
CM_ SG_ 1617 SY1_NWDF_gueltig "Gültigkeit der Netzwerk-Diagnose Freigabe (Byte 7, Bit 7)";
CM_ SG_ 1617 SY1_NWDF "Netzwerk-Diagnose Freigabe zur zentralen Aktivierung der Netzwerkdiagnose";
CM_ SG_ 1617 SY1_Notbrems_Status "Gateway erkennt Notbremssituation (z. Zt. nur PQ46, PQ35 ab MJ07)
Notbremsstatus";
CM_ SG_ 1477 TAS_TA_on "Tastatur ist betriebsbereit, wenn ausgeklappt";
CM_ SG_ 1477 TAS_TA_Wake_Up_Komfort "Wecken des Komfortbus";
CM_ SG_ 1477 TAS_TA_Error_flag "Fehlereintrag vorhanden";
CM_ SG_ 1477 TAS_TA_Symbol "siehe Spezifikation 12er Tastatur
Symbolcode der Tastenbelegung";
CM_ SG_ 1639 TF1_DSP_Zeichen_1 "Display-Daten fuer das 2 Zeilen Display hier Zeile 1
Display-Daten 1. Zeichen Zeile 1";
CM_ SG_ 1639 TF1_DSP_Zeichen_2 "Bei Aenderung sofort mit minimalen Aktualisierungsabstand dt: 50ms
Display-Daten 2. Zeichen Zeile 1";
CM_ SG_ 1639 TF1_DSP_Zeichen_3 "Display-Daten 3. Zeichen Zeile 1";
CM_ SG_ 1639 TF1_DSP_Zeichen_4 "Display-Daten 4. Zeichen Zeile 1";
CM_ SG_ 1639 TF1_DSP_Zeichen_5 "Display-Daten 5. Zeichen Zeile 1";
CM_ SG_ 1639 TF1_DSP_Zeichen_6 "Display-Daten 6. Zeichen Zeile 1";
CM_ SG_ 1639 TF1_DSP_Zeichen_7 "Display-Daten 7. Zeichen Zeile 1";
CM_ SG_ 1639 TF1_DSP_Zeichen_8 "Display-Daten 8. Zeichen Zeile 1";
CM_ SG_ 1643 TF2_DSP_Zeichen_9 "Display-Daten fuer das 2 Zeilen Display hier Zeile 2
Display-Daten 1. Zeichen Zeile 2";
CM_ SG_ 1643 TF2_DSP_Zeichen_10 "Bei Aenderung sofort mit minimalen Aktualisierungsabstand dt: 50ms
Display-Daten 2. Zeichen Zeile 2";
CM_ SG_ 1643 TF2_DSP_Zeichen_11 "Display-Daten 3. Zeichen Zeile 2";
CM_ SG_ 1643 TF2_DSP_Zeichen_12 "Display-Daten 4. Zeichen Zeile 2";
CM_ SG_ 1643 TF2_DSP_Zeichen_13 "Display-Daten 5. Zeichen Zeile 2";
CM_ SG_ 1643 TF2_DSP_Zeichen_14 "Display-Daten 6. Zeichen Zeile 2";
CM_ SG_ 1643 TF2_DSP_Zeichen_15 "Display-Daten 7. Zeichen Zeile 2";
CM_ SG_ 1643 TF2_DSP_Zeichen_16 "Display-Daten 8. Zeichen Zeile 2";
CM_ SG_ 1637 TF3_Phone_on "1 = Telefon eingeschaltet";
CM_ SG_ 1637 TF3_Show_Phone "1 = Radioanzeige disabled
0 = Radioanzeige enable
Kombi soll Tel-Daten anzeigen";
CM_ SG_ 1637 TF3_Phone_mute "1 =Car Radio Mute (CRM) / Vorhalt vorerst konventionell verdrahtet";
CM_ SG_ 1637 TF3_Phone_active_call "1 = Verbindungsaufbau/Gespraechszustand
Ein-/Ausgehender Anruf";
CM_ SG_ 1637 TF3_Phone_ring "1 = Anrufsignalisierung
Eingehender Anruf";
CM_ SG_ 1637 TF3_Phone_sim_OK "1 = gueltige Simkarte eingelegt
Simkarte eingelegt";
CM_ SG_ 1637 TF3_Phone_pin_OK "1 = PIN richtig eingegeben";
CM_ SG_ 1637 TF3_Phone_Error_flag "1 = mindestens ein Kundendienstfehler ist im Steuergeraet eingetragen";
CM_ SG_ 1637 TF3_Phone_Level "Lautstaerke Handsfree Line_Out";
CM_ SG_ 1637 TF3_Phone_Display_Vol "Anzeige der Telefonlautstärkeänderung im Komiinstrument
Anzeige Lautstärke Radi Display";
CM_ SG_ 1637 TF3_Phone_Init "1 =Bluetooth phone initialized (Bluetooth link to pone active)
0= Bluetooth phone not initialized (Bluetooth link to phone not active)
Telefoninitialisierung";
CM_ SG_ 1637 TF3_Mute_Msg_Code "siehe Mutespezifikation";
CM_ SG_ 1637 TF3_Wake_Up_Komfort "Wecken des Komfortbus";
CM_ SG_ 1637 TF3_Radio_Access "res";
CM_ SG_ 1637 TF3_Provider "MNC Codierung gemaess GSM 04.08 oder MoU Liste - BCD Codiert Bit 11..8 - MNC Dig. 3,Bit 7..4 - MNC Dig. 2, Bit 3..0 - MNC Dig. 1
Netzwerkprovidercode (MNC) BCD codiert";
CM_ SG_ 1637 TF3_Feldstaerke "Feldstaerkeinformation 0 = kein Feld, 15 = sehr gutes Feld
Aktuelle Feldstaerke des Netzes";
CM_ SG_ 1637 TF3_Laendercode "MCC Codierung gemaess GSM 04.08 oder MoU Liste - BCD Codiert Bit 11..8 - MCC Dig. 3,Bit 7..4 - MCC Dig. 2, Bit 3..0 - MCC Dig. 1
Laendercode (MCC) BCD codiert";
CM_ SG_ 1637 TF3_Feldstaerke_Fehler "1 = Feldstaerkeinformation nicht ermittelbar (z.B. nicht in ein Netz eingebucht) - Alle Providerinfos sind ungueltig
Feldstaekeinfo nicht verfuegbar oder Fehler";
CM_ SG_ 1637 TF3_Registrierungsstatus "Netzregistrierungsstatus :
0 - 'no service, not searching'
1 - 'registered at home network'
2 - 'no service, searching'
3 - res.
4 - res.
5 - 'registered, roaming'
6 - res.
7 - Info nicht Verfuegbar";
CM_ SG_ 1447 TM1_TM_on "Telematik Einheit: Einsatz dieser Botschaft noch unklar
Telematik ist betriebsbereit";
CM_ SG_ 1447 TM1_TM_mute "1 = Car Radio Mute (CRM) / Vorhalt vorerst konventionell verdrahtet";
CM_ SG_ 1447 TM1_TM_Wake_Up_Komfort "Wecken des Komfortbus";
CM_ SG_ 1447 TM1_TM_Error_flag "Fehlereintrag vorhanden";
CM_ SG_ 1449 TM2_Warnblink "0: Warnblinker sind ausgeschaltet
1: Warnblinker blinken, Takt wird vom SG für Blinken (z.B. BSG) vorgegebenen";
CM_ SG_ 1449 TM2_Signalhorn "0 = Hupe aus
1 = Hupe ein
Der Takt muss von der Telematik vorgegeben werden";
CM_ SG_ 1449 TM2_Lock "ZV zu/ Verriegeln";
CM_ SG_ 1449 TM2_Unlock "ZV auf/ Entriegeln";
CM_ SG_ 1745 TP_DAB_Radio "vom SDARS bzw. DAB zum Radio
Befehl Digital Radio Tuner (DAB-Radio)";
CM_ SG_ 1244 TPDyn_DAB_1 "DAB
TP 2.0 Empfangskanal 1 fuer DAB";
CM_ SG_ 1245 mTPDyn_DAB_2 "DAB
TP 2.0 Empfangskanal 1 fuer DAB";
CM_ SG_ 768 TPDyn_Diag_1_1 "Tester
TP 2.0 Empfangskanal 1 fuer Tester";
CM_ SG_ 769 TPDyn_Diag_1_2 "Tester
TP 2.0 Empfangskanal 2 fuer Tester";
CM_ SG_ 770 TPDyn_Diag_1_3 "Tester
TP 2.0 Empfangskanal 3 fuer Tester";
CM_ SG_ 771 TPDyn_Diag_1_4 "Tester
TP 2.0 Empfangskanal 4 fuer Tester";
CM_ SG_ 772 TPDyn_Diag_1_5 "Tester
TP 2.0 Empfangskanal 5 fuer Tester";
CM_ SG_ 773 TPDyn_Diag_1_6 "Tester
TP 2.0 Empfangskanal 6 fuer Tester";
CM_ SG_ 774 TPDyn_Diag_1_7 "Tester
TP 2.0 Empfangskanal 7 fuer Tester";
CM_ SG_ 775 TPDyn_Diag_1_8 "Tester
TP 2.0 Empfangskanal 8 fuer Tester";
CM_ SG_ 1246 TPDyn_DSP_1 "DSP
TP 2.0 Empfangskanal 1 fuer DSP";
CM_ SG_ 1247 TPDyn_DSP_2 "DSP
TP 2.0 Empfangskanal 1 fuer DSP";
CM_ SG_ 1232 TPDyn_Grafik_1 "Grafikeinheit im Kombi
TP 2.0 Empfangskanal 1 fuer Grafikeinheit";
CM_ SG_ 1233 TPDyn_Grafik_2 "Grafikeinheit im Kombi
TP 2.0 Empfangskanal 2 fuer Grafikeinheit";
CM_ SG_ 1234 TPDyn_Grafik_3 "Grafikeinheit im Kombi
TP 2.0 Empfangskanal 3 fuer Grafikeinheit";
CM_ SG_ 1235 TPDyn_Grafik_4 "Grafikeinheit im Kombi
TP 2.0 Empfangskanal 4 fuer Grafikeinheit";
CM_ SG_ 1279 TPDyn_GSM_1 "GSM_Pager
TP 2.0 Empfangskanal 1 für den GSM";
CM_ SG_ 720 TPDyn_Info_1 "Informationselektronik
TP 2.0 Empfangskanal 1 fuer Informationselektronik";
CM_ SG_ 721 TPDyn_Info_2 "Informationselektronik
TP 2.0 Empfangskanal 2 fuer Informationselektronik";
CM_ SG_ 1250 TPDyn_Kompass_1 "Kompass
TP 2.0 Empfangskanal 1 für den Kompass";
CM_ SG_ 1251 TPDyn_Kompass_2 "Kompass
TP 2.0 Empfangskanal 1 für den Kompass";
CM_ SG_ 1260 TPDyn_MDI_1 "MDI
TP 2.0 Empfangskanal 1 fuer MDI";
CM_ SG_ 1240 TPDyn_Navi_1 "Navigation
TP 2.0 Empfangskanal 1 fuer Navigation";
CM_ SG_ 1241 TPDyn_Navi_2 "Navigation
TP 2.0 Empfangskanal 2 fuer Navigation";
CM_ SG_ 1242 TPDyn_Radio_1 "Radio
TP 2.0 Empfangskanal 1 fuer Radio";
CM_ SG_ 1243 TPDyn_Radio_2 "Radio
TP 2.0 Empfangskanal 1 fuer Radio";
CM_ SG_ 1276 TPDyn_Rearview_1 "Rearview
TP 2.0 Empfangskanal 1 fuer Rearview";
CM_ SG_ 1277 TPDyn_Rearview_2 "Rearview
TP 2.0 Empfangskanal 2 fuer Rearview";
CM_ SG_ 1248 TPDyn_SBS_1 "Sprachbedienung
TP 2.0 Empfangskanal 1 fuer SBS";
CM_ SG_ 1249 TPDyn_SBS_2 "Sprachbedienung
TP 2.0 Empfangskanal 1 fuer SBS";
CM_ SG_ 804 TPDyn_SH_1 "Standheizung
TP 2.0 Empfangskanal 1 fuer Standheizung_SG";
CM_ SG_ 805 TPDyn_SH_2 "Standheizung
TP 2.0 Empfangskanal 2 fuer Standheizung_SG";
CM_ SG_ 1270 TPDyn_Tastatur_1 "Tastatur
TP 2.0 Empfangskanal 1 fuer Tastatur";
CM_ SG_ 1271 TPDyn_Tastatur_2 "Tastatur
TP 2.0 Empfangskanal 2 fuer Tastatur";
CM_ SG_ 1264 TPDyn_Telefon_1 "Telefon
TP 2.0 Empfangskanal 1 fuer Telefon";
CM_ SG_ 1265 TPDyn_Telefon_2 "Telefon
TP 2.0 Empfangskanal 1 fuer Telefon";
CM_ SG_ 1268 TPDyn_Telematik_1 "Telematik
TP 2.0 Empfangskanal 1 fuer Telematik";
CM_ SG_ 1269 TPDyn_Telematik_2 "Telematik
TP 2.0 Empfangskanal 1 fuer Telematik";
CM_ SG_ 1272 TPDyn_TV_1 "TV analog
TP 2.0 Empfangskanal 1 fuer TV";
CM_ SG_ 1273 TPDyn_TV_2 "TV analog
TP 2.0 Empfangskanal 2 fuer TV";
CM_ SG_ 591 DAB_TP_Er "SDARS oder DAB-Tuner
TP 2.0 Eroeffnungskanal";
CM_ SG_ 595 DSP_TP_Er "Digitaler Sound Prozessor
TP 2.0 Eroeffnungskanal";
CM_ SG_ 584 Grafik_TP_Er "Grafikeinheit im Kombiinstrument
TP 2.0 Eroeffnungskanal";
CM_ SG_ 577 GSM_TP_Er "GSM
TP 2.0 Eroeffnungskanal";
CM_ SG_ 589 Informationselektronik1_TP_Er "Informationselektronik
TP 2.0 Eroeffnungskanal";
CM_ SG_ 576 Kompass_TP_Er "Kompass
TP 2.0 Eroeffnungskanal";
CM_ SG_ 596 MDI_TP_Er "MDI
TP 2.0 Eroeffnungskanal";
CM_ SG_ 603 Navi_TP_Er "Navigation
TP 2.0 Eroeffnungskanal";
CM_ SG_ 594 Radio_TP_Er "Radio
TP 2.0 Eroeffnungskanal";
CM_ SG_ 585 Rearview_TP_Er "Rearview
TP 2.0 Eroeffnungskanal";
CM_ SG_ 604 SBS_TP_Er "Sprachbediensystem
TP 2.0 Eroeffnungskanal";
CM_ SG_ 559 SH_TP_Er "Standheizung
TP 2.0 Eroeffnungskanal";
CM_ SG_ 587 Tastatur_TP_Er "Tastatur
TP 2.0 Eroeffnungskanal";
CM_ SG_ 602 Telefon_TP_Er "Telefon
TP 2.0 Eroeffnungskanal";
CM_ SG_ 597 TM_TP_Er_Telematik "Telematik
TP 2.0 Eroeffnungskanal";
CM_ SG_ 512 Tester_TP_Er "Transportkanaleroeffnung vom Tester zu allen Steuergeraeten mit CAN-Diagnose; TP 2.0
TP 2.0 Eroeffnungskanal";
CM_ SG_ 599 TV_A_TP_Er "TV_Tuner analog
TP 2.0 Eroeffnungskanal";
CM_ SG_ 1729 DISP_KOM_NSL "Im D2GP verwendet
Displaydaten Navigation (KOM->NAV)
DISP_KOM_NSL";
CM_ SG_ 1731 DISP_KOM_TM "reserviert fuer Vollduplex-Kanal
Displaydaten Telematik (KOM->TM)
DISP_KOM_TM";
CM_ SG_ 1728 DISP_NSL_KOM "Im D2GP verwendet
Displaydaten Navigation (NAV->KOM)
DISP_NSL_KOM";
CM_ SG_ 1744 TPRadio_DAB "vom Radio zum SDARS bzw. DAB
Befehl Digital Radio Tuner (Radio-DAB)";
CM_ SG_ 1673 TPStat_Grafik_Kompass "Von Grafikeinheit zum Kompass
TP 2.0 Empfangskanal vom Kompass";
CM_ SG_ 1665 TPStat_Grafik_Radio "Von Grafikeinheit zum Radio
TP 2.0 Empfangskanal vom Radio";
CM_ SG_ 1667 TPStat_Grafik_RNS "Von Grafikeinheit zum RNS
TP 2.0 Empfangskanal vom Radio";
CM_ SG_ 1669 TPStat_Grafik_Telefon "Von Grafikeinheit zum Telefon
TP 2.0 Empfangskanal vom Radio";
CM_ SG_ 1671 TPStat_Grafik_Telematik "Von Grafikeinheit zur Telematik
TP 2.0 Empfangskanal von der Telematik";
CM_ SG_ 1672 TPStat_Kompass_Grafik "Vom der Kompass zur Grafikeinheit
TP 2.0 Sendekanal vom Kompass";
CM_ SG_ 1664 TPStat_Radio_Grafik "Vom Radio zur Grafikeinheit
TP 2.0 Sendekanal vom Radio";
CM_ SG_ 1666 TPStat_RNS_Grafik "Vom RNS zur Grafikeinheit
TP 2.0 Sendekanal vom RNS";
CM_ SG_ 1668 TPStat_Telefon_Grafik "Vom Telefon zur Grafikeinheit
TP 2.0 Sendekanal vom Telefon";
CM_ SG_ 1670 TPStat_Telematik_Grafik "Von der Telematik zur Grafikeinheit
TP 2.0 Sendekanal von der Telematik";
CM_ SG_ 1730 DISP_TM_KOM "reserviert fuer Vollduplex-Kanal
Displaydaten Telematik (TM->KOM)
DISP_TM_KOM";
CM_ SG_ 1538 TV1_TVA_On "Festlegung von Statuscodes und Parametern erfolgt in separater Tabelle.
TV_Tuner Einschaltzustand";
CM_ SG_ 1538 TV1_TVA_mute "Mute On/Off";
CM_ SG_ 1538 TV1_TVA_Ueberhitzung "0= i.O
1= Ueberhitzung";
CM_ SG_ 1538 TV1_TVA_50Hz "0= 50Hz
1= 60Hz
Bildfrequenz";
CM_ SG_ 1538 TV1_TVA_Error "1 = interner Fehler im TV-Tuner; evtl. Fehlfunktion";
CM_ SG_ 1538 TV1_TVA_Error_flag "1 = mindestens 1 Fehler im Kundendienstfehlerspeicher eingetragen";
CM_ SG_ 1538 TV1_TVA_Mode "siehe Spezifikation Mode-Codierung
Mode-Information";
CM_ SG_ 1538 TV1_TVA_Para1 "Parameter des jew. Modes";
CM_ SG_ 1538 TV1_TVA_Para2 "Parameter des jew. Modes";
CM_ SG_ 1538 TV1_TVA_Para3 "Parameter des jew. Modes";
CM_ SG_ 1538 TV1_TVA_Para4 "Parameter des jew. Modes";
CM_ SG_ 1538 TV1_TVA_Para5 "Parameter des jew. Modes";
CM_ SG_ 1538 TV1_TVA_Para6 "Parameter des jew. Modes";
CM_ SG_ 1497 VS1_FH_FT_hoch "Ansteuerung Fensterheber vom Verdecksteuergeraet
Fenster Fahrer hoch";
CM_ SG_ 1497 VS1_FH_FT_tief "Fenster Fahrer tief";
CM_ SG_ 1497 VS1_FH_BT_hoch "Fenster Beifahrer hoch";
CM_ SG_ 1497 VS1_FH_BT_tief "Fenster Beifahrer tief";
CM_ SG_ 1497 VS1_FH_HL_hoch "Fenster hinten links hoch";
CM_ SG_ 1497 VS1_FH_HL_tief "Fenster hinten links tief";
CM_ SG_ 1497 VS1_FH_HR_hoch "Fenster hinten rechts hoch";
CM_ SG_ 1497 VS1_FH_HR_tief "Fenster hinten rechts tief";
CM_ SG_ 1497 VS1_Freigabe_FH "Freigabe der Fenstersteuerung Komfortfunktion";
CM_ SG_ 1497 VS1_ZV_auf "ZV: Auf von Infrarot-Fernbedienung";
CM_ SG_ 1497 VS1_ZV_zu "ZV: Zu von Infrarot-Fernbedienung";
CM_ SG_ 1497 VS1_Heckschloss_auf "Bit wird gesetzt, wenn fuer einen Verdeckbetrieb das Öffnen des Heckschlosses erforderlich ist.";
CM_ SG_ 1497 VS1_auf_Verriegelung "Bit wird gesetzt, wenn bei Verdeckbetrieb die Verriegelung Heckdeckel/Verdeckkasten geoeffnet werden soll";
CM_ SG_ 1497 VS1_zu_Verriegelung "Bit wird gesetzt, wenn bei Verdeckbetrieb die Verriegelung Heckdeckel/Verdeckkasten geschlossen werden soll";
CM_ SG_ 1497 VS1_Sperren "Sperren der FH zum Schutz der Verdeckkomponenten in der Initialisierungsphase und bei bestimmten Verdeckstati";
CM_ SG_ 1497 VS1_zent_FH_Schalter "Nur Baustufe 1 B6 Cabrio, entfaellt anschliessend wieder
Zentraler FH Schalter";
CM_ SG_ 1497 VS1_VD_zu_ver "1 = Zustand des Verdecks verriegelt und geschlossen";
CM_ SG_ 1497 VS1_VD_entriegelt "Verrriegeltzustand des Verdeck bzw. des Verdeckkastendeckel (VDKD)";
CM_ SG_ 1497 VS1_VD_offen_ver "1 = Zustand des Verdecks geoeffnet und abgelegt (In Ablage verriegelt)";
CM_ SG_ 1497 VS1_VD_Zwischenposition "1 = Verdeck in Zwischenposition";
CM_ SG_ 1497 VS1_VD_Bew_auf "1 = Verdeck in Bewegung auf";
CM_ SG_ 1497 VS1_VD_Bew_zu "1 = Verdeck in Bewegung zu";
CM_ SG_ 1497 VS1_Verdeck_Anf "1 = Verdeck nicht in den Zustaenden 'geschlossen verriegelt' oder 'offen verriegelt'";
CM_ SG_ 1497 VS1_Hardtop "1 = Hardtop ist montiert";
CM_ SG_ 1497 VS1_VD_Fehler "1 = Fehlerzustand Verdeck";
CM_ SG_ 1497 VS1_Lampe_Blk "Ansteuerung Lampe im Kombi";
CM_ SG_ 1497 VS1_Text_3 "Text zur Anzeige im Kombiinstrument: Bitte Heckdeckel schliessen";
CM_ SG_ 1497 VS1_Buzzer "Ansteuerung Buzzer im Kombi";
CM_ SG_ 1497 VS1_HHS_enable "1 = Betrieb Heckscheibenheizung erlaubt fuer Hardtop";
CM_ SG_ 1497 VS1_VDKD_auf "Signal wird gesetzt, wenn der Verdeckkastendeckel vollstaendig geoeffnet ist";
CM_ SG_ 1497 VS1_Text_1 "Anzeige des Textes im Kombiinstrument
Textmeldung Verdeckbetätigung nicht moeglich";
CM_ SG_ 1497 VS1_KD_Fehler "1 = mindestens 1 Kundendienstfehlereintrag im Steuergeraet";
CM_ SG_ 1497 VS1_LED "LED im Kombiinstrument soll angesteuert werden.
LED fuer Verdecksteuergeraet";
CM_ SG_ 1497 VS1_Blink_LED "Eintakten der LED in den Blinktakt des Kombiinstrumentes
Taktforderung fuer die LED";
CM_ SG_ 1497 VS1_1_Akustik "Ansteuerung der Akustik 1 (Einmaliger Warnton 2kHz) im Kombiinstrument gefordert";
CM_ SG_ 1497 VS1_2_Akustik "Ansteuerung der Akustik 2 (einmaliger Gong) im Kombiinstrument gefordert";
CM_ SG_ 1497 VS1_3_Akustik "Ansteuerung der Akustik 3 (Dauerhafter Warnton 600Hz) im Kombiinstrument gefordert";
CM_ SG_ 1497 VS1_Verdeckbetrieb "Anzeige, dass ein Verdeckbetrieb stattfindet. Fuehrt im Kombi dazu, dass die Hauptraste des Heckdeckels für die Zeit unterdrückt wird, solange dieses Bit gesetzt ist. (Notwendig, damit die DDP Verdecktexte nicht durch Car-Outline verdraengt werden)";
CM_ SG_ 1497 VS1_ZZH_offen "Status der Zuziehhilfe des Heckdeckels beim Cabrio. Wenn die Zuziehhilfe offen (nicht eingefahren) ist, muss eine Anzeige im Kombi erfolgen.";
CM_ SG_ 1497 VS1_Text_2 "Text zur Anzeige im Kombiinstrument
Textmeldung Verdeck nicht in Endlage";
CM_ SG_ 1497 VS1_Texte "Texte zur Anzeige im Kombi
0 = keine Anzeige
1 = Verdeckbetrieb
2 = Systemfehler Verdeck! Werkstatt
3 = Systemfehler Verdeck schliessen!
4 = Systemfehler Verdeck öffnen!
5 = Geschwindigkeit zu hoch!
6 = Übertemperatur Verdeck!
7 = Übertemperatur S";
CM_ SG_ 707 ZS1_ZAS_Kl_S "1 = Schluessel steckt
0 = kein Schlüssel im Zuendschloss, bzw. kein S-Kontakt
S-Kontakt (Schluessel steckt)";
CM_ SG_ 707 ZS1_ZAS_Kl_15 "1 = Klemme 15 ein
0 = Klemme 15 aus
Sollzustand
Klemme 15 (Zuendung ein)";
CM_ SG_ 707 ZS1_ZAS_Kl_X "0=keine Spannung
1 =Spannung vorhanden, entspricht Kl. 15 ausser im Startvorgang
Sollzustand
Klemme X (Startvorgang)";
CM_ SG_ 707 ZS1_ZAS_Kl_50 "1 = Klemme 50 ein
0 = Klemme 50 aus
Sollzustand
Klemme 50 (Starten)";
CM_ SG_ 707 ZS1_ZAS_KL_P "1 = Klemme P ein (Parklichtstellung)";
BA_DEF_ BO_  "GenMsgAutoGenDsp" ENUM  "No","Yes";
BA_DEF_ BO_  "GenMsgAutoGenSnd" ENUM  "No","Yes";
BA_DEF_ BO_  "GenMsgCycleTime" INT 0 65535;
BA_DEF_ BO_  "GenMsgCycleTimeFast" INT 0 65535;
BA_DEF_ BO_  "GenMsgDelayTime" INT 0 100000;
BA_DEF_ BO_  "GenMsgILSupport" ENUM  "No","Yes";
BA_DEF_ BO_  "GenMsgNrOfRepetition" INT 0 100;
BA_DEF_ BO_  "GenMsgSendType" ENUM  "Cyclic","not_used","not_used","not_used","not_used","not_used","not_used","IfActive","NoMsgSendType";
BA_DEF_ BO_  "GenMsgStartDelayTime" INT 0 100000;
BA_DEF_ BO_  "NmMessage" ENUM  "No","Yes";
BA_DEF_ BO_  "NmhMessage" ENUM  "No","Yes";
BA_DEF_ BO_  "VAGTP20_API" HEX 0 255;
BA_DEF_ BO_  "VAGTP20_DynConnection" ENUM  "No","Yes";
BA_DEF_ BO_  "VAGTP20_DynSetup" ENUM  "No","Yes";
BA_DEF_ BO_  "VAGTP20_StatConnection" ENUM  "No","Yes";
BA_DEF_ BO_  "DiagRequest" ENUM  "No","Yes";
BA_DEF_ BO_  "DiagResponse" ENUM  "No","Yes";
BA_DEF_ BO_  "DiagState" ENUM  "No","Yes";
BA_DEF_ SG_  "GenSigAutoGenDsp" ENUM  "No","Yes";
BA_DEF_ SG_  "GenSigAutoGenSnd" ENUM  "No","Yes";
BA_DEF_ SG_  "GenSigEnvVarType" ENUM  "int","float","undef";
BA_DEF_ SG_  "GenSigInactiveValue" INT -2147483648 2147483647;
BA_DEF_ SG_  "GenSigSendType" ENUM  "Cyclic","OnWrite","OnWriteWithRepetition","OnChange","OnChangeWithRepetition","IfActive","IfActiveWithRepetition","NoSigSendType","OnChangeAndIfActive","OnChangeAndIfActiveWithRepetition";
BA_DEF_ SG_  "GenSigStartValue" INT -2147483648 2147483647;
BA_DEF_ SG_  "NWM-WakeupAllowed" ENUM  "No","Yes";
BA_DEF_ SG_  "GenSigFuncType" ENUM  "NoFunction","MsgCounter","CRC-8","XOR","XOR-2","DatedBit","SW-Kl15","CHK","Constant","Protocol";
BA_DEF_ SG_  "GenSigSwitchedByIgnition" ENUM  "No","Yes";
BA_DEF_ SG_  "Fehlerwert" HEX 0 2147483647;
BA_DEF_DEF_  "GenMsgAutoGenDsp" "Yes";
BA_DEF_DEF_  "GenMsgAutoGenSnd" "Yes";
BA_DEF_DEF_  "GenMsgCycleTime" 0;
BA_DEF_DEF_  "GenMsgCycleTimeFast" 0;
BA_DEF_DEF_  "GenMsgDelayTime" 0;
BA_DEF_DEF_  "GenMsgILSupport" "No";
BA_DEF_DEF_  "GenMsgNrOfRepetition" 0;
BA_DEF_DEF_  "GenMsgSendType" "NoMsgSendType";
BA_DEF_DEF_  "GenMsgStartDelayTime" 0;
BA_DEF_DEF_  "NmMessage" "No";
BA_DEF_DEF_  "NmhMessage" "No";
BA_DEF_DEF_  "VAGTP20_API" 0;
BA_DEF_DEF_  "VAGTP20_DynConnection" "No";
BA_DEF_DEF_  "VAGTP20_DynSetup" "No";
BA_DEF_DEF_  "VAGTP20_StatConnection" "No";
BA_DEF_DEF_  "DiagRequest" "No";
BA_DEF_DEF_  "DiagResponse" "No";
BA_DEF_DEF_  "DiagState" "No";
BA_DEF_DEF_  "GenSigAutoGenDsp" "No";
BA_DEF_DEF_  "GenSigAutoGenSnd" "No";
BA_DEF_DEF_  "GenSigEnvVarType" "undef";
BA_DEF_DEF_  "GenSigInactiveValue" 0;
BA_DEF_DEF_  "GenSigSendType" "NoSigSendType";
BA_DEF_DEF_  "GenSigStartValue" 0;
BA_DEF_DEF_  "NWM-WakeupAllowed" "No";
BA_DEF_DEF_  "GenSigFuncType" "NoFunction";
BA_DEF_DEF_  "GenSigSwitchedByIgnition" "No";
BA_DEF_DEF_  "Fehlerwert" 0;
BA_ "GenMsgCycleTime" BO_ 1349 500;
BA_ "GenMsgDelayTime" BO_ 1349 50;
BA_ "GenMsgILSupport" BO_ 1349 1;
BA_ "GenMsgSendType" BO_ 1349 0;
BA_ "GenMsgCycleTimeFast" BO_ 1355 100;
BA_ "GenMsgILSupport" BO_ 1355 1;
BA_ "GenMsgSendType" BO_ 1355 7;
BA_ "GenMsgCycleTimeFast" BO_ 867 800;
BA_ "GenMsgDelayTime" BO_ 867 80;
BA_ "GenMsgILSupport" BO_ 867 1;
BA_ "GenMsgSendType" BO_ 867 7;
BA_ "GenMsgCycleTimeFast" BO_ 869 800;
BA_ "GenMsgDelayTime" BO_ 869 80;
BA_ "GenMsgILSupport" BO_ 869 1;
BA_ "GenMsgSendType" BO_ 869 7;
BA_ "GenMsgCycleTimeFast" BO_ 865 100;
BA_ "GenMsgILSupport" BO_ 865 1;
BA_ "GenMsgSendType" BO_ 865 7;
BA_ "GenMsgCycleTime" BO_ 1633 1000;
BA_ "GenMsgDelayTime" BO_ 1633 100;
BA_ "GenMsgILSupport" BO_ 1633 1;
BA_ "GenMsgSendType" BO_ 1633 0;
BA_ "GenMsgCycleTime" BO_ 1121 100;
BA_ "GenMsgCycleTimeFast" BO_ 1121 100;
BA_ "GenMsgILSupport" BO_ 1121 1;
BA_ "GenMsgNrOfRepetition" BO_ 1121 5;
BA_ "GenMsgSendType" BO_ 1121 7;
BA_ "DiagState" BO_ 1121 1;
BA_ "GenMsgCycleTime" BO_ 1347 1000;
BA_ "GenMsgDelayTime" BO_ 1347 100;
BA_ "GenMsgILSupport" BO_ 1347 1;
BA_ "GenMsgSendType" BO_ 1347 0;
BA_ "GenMsgCycleTimeFast" BO_ 1445 1000;
BA_ "GenMsgDelayTime" BO_ 1445 100;
BA_ "GenMsgILSupport" BO_ 1445 1;
BA_ "GenMsgSendType" BO_ 1445 7;
BA_ "GenMsgCycleTime" BO_ 1451 1000;
BA_ "GenMsgDelayTime" BO_ 1451 100;
BA_ "GenMsgILSupport" BO_ 1451 1;
BA_ "GenMsgSendType" BO_ 1451 0;
BA_ "GenMsgCycleTime" BO_ 1621 500;
BA_ "GenMsgILSupport" BO_ 1621 1;
BA_ "GenMsgSendType" BO_ 1621 0;
BA_ "GenMsgCycleTime" BO_ 997 200;
BA_ "GenMsgDelayTime" BO_ 997 20;
BA_ "GenMsgILSupport" BO_ 997 1;
BA_ "GenMsgSendType" BO_ 997 0;
BA_ "GenMsgCycleTime" BO_ 1617 100;
BA_ "GenMsgDelayTime" BO_ 1617 50;
BA_ "GenMsgILSupport" BO_ 1617 1;
BA_ "GenMsgSendType" BO_ 1617 0;
BA_ "GenMsgCycleTime" BO_ 1477 200;
BA_ "GenMsgDelayTime" BO_ 1477 20;
BA_ "GenMsgILSupport" BO_ 1477 1;
BA_ "GenMsgSendType" BO_ 1477 0;
BA_ "GenMsgCycleTimeFast" BO_ 1639 800;
BA_ "GenMsgDelayTime" BO_ 1639 80;
BA_ "GenMsgILSupport" BO_ 1639 1;
BA_ "GenMsgSendType" BO_ 1639 7;
BA_ "GenMsgCycleTimeFast" BO_ 1643 800;
BA_ "GenMsgDelayTime" BO_ 1643 80;
BA_ "GenMsgILSupport" BO_ 1643 1;
BA_ "GenMsgSendType" BO_ 1643 7;
BA_ "GenMsgCycleTime" BO_ 1637 1000;
BA_ "GenMsgDelayTime" BO_ 1637 100;
BA_ "GenMsgILSupport" BO_ 1637 1;
BA_ "GenMsgSendType" BO_ 1637 0;
BA_ "GenMsgCycleTime" BO_ 1447 1000;
BA_ "GenMsgDelayTime" BO_ 1447 100;
BA_ "GenMsgILSupport" BO_ 1447 1;
BA_ "GenMsgSendType" BO_ 1447 0;
BA_ "GenMsgCycleTimeFast" BO_ 1449 100;
BA_ "GenMsgILSupport" BO_ 1449 1;
BA_ "GenMsgSendType" BO_ 1449 7;
BA_ "GenMsgAutoGenDsp" BO_ 1745 0;
BA_ "GenMsgAutoGenSnd" BO_ 1745 0;
BA_ "VAGTP20_API" BO_ 1745 16;
BA_ "VAGTP20_StatConnection" BO_ 1745 1;
BA_ "GenMsgAutoGenDsp" BO_ 1244 0;
BA_ "GenMsgAutoGenSnd" BO_ 1244 0;
BA_ "VAGTP20_DynConnection" BO_ 1244 1;
BA_ "GenMsgAutoGenDsp" BO_ 1245 0;
BA_ "GenMsgAutoGenSnd" BO_ 1245 0;
BA_ "VAGTP20_DynConnection" BO_ 1245 1;
BA_ "GenMsgAutoGenDsp" BO_ 768 0;
BA_ "GenMsgAutoGenSnd" BO_ 768 0;
BA_ "VAGTP20_DynConnection" BO_ 768 1;
BA_ "GenMsgAutoGenDsp" BO_ 769 0;
BA_ "GenMsgAutoGenSnd" BO_ 769 0;
BA_ "VAGTP20_DynConnection" BO_ 769 1;
BA_ "GenMsgAutoGenDsp" BO_ 770 0;
BA_ "GenMsgAutoGenSnd" BO_ 770 0;
BA_ "VAGTP20_DynConnection" BO_ 770 1;
BA_ "GenMsgAutoGenDsp" BO_ 771 0;
BA_ "GenMsgAutoGenSnd" BO_ 771 0;
BA_ "VAGTP20_DynConnection" BO_ 771 1;
BA_ "GenMsgAutoGenDsp" BO_ 772 0;
BA_ "GenMsgAutoGenSnd" BO_ 772 0;
BA_ "VAGTP20_DynConnection" BO_ 772 1;
BA_ "GenMsgAutoGenDsp" BO_ 773 0;
BA_ "GenMsgAutoGenSnd" BO_ 773 0;
BA_ "VAGTP20_DynConnection" BO_ 773 1;
BA_ "GenMsgAutoGenDsp" BO_ 774 0;
BA_ "GenMsgAutoGenSnd" BO_ 774 0;
BA_ "VAGTP20_DynConnection" BO_ 774 1;
BA_ "GenMsgAutoGenDsp" BO_ 775 0;
BA_ "GenMsgAutoGenSnd" BO_ 775 0;
BA_ "VAGTP20_DynConnection" BO_ 775 1;
BA_ "GenMsgAutoGenDsp" BO_ 1246 0;
BA_ "GenMsgAutoGenSnd" BO_ 1246 0;
BA_ "VAGTP20_DynConnection" BO_ 1246 1;
BA_ "GenMsgAutoGenDsp" BO_ 1247 0;
BA_ "GenMsgAutoGenSnd" BO_ 1247 0;
BA_ "VAGTP20_DynConnection" BO_ 1247 1;
BA_ "GenMsgAutoGenDsp" BO_ 1232 0;
BA_ "GenMsgAutoGenSnd" BO_ 1232 0;
BA_ "VAGTP20_DynConnection" BO_ 1232 1;
BA_ "GenMsgAutoGenDsp" BO_ 1233 0;
BA_ "GenMsgAutoGenSnd" BO_ 1233 0;
BA_ "VAGTP20_DynConnection" BO_ 1233 1;
BA_ "GenMsgAutoGenDsp" BO_ 1234 0;
BA_ "GenMsgAutoGenSnd" BO_ 1234 0;
BA_ "VAGTP20_DynConnection" BO_ 1234 1;
BA_ "GenMsgAutoGenDsp" BO_ 1235 0;
BA_ "GenMsgAutoGenSnd" BO_ 1235 0;
BA_ "VAGTP20_DynConnection" BO_ 1235 1;
BA_ "GenMsgAutoGenDsp" BO_ 1279 0;
BA_ "GenMsgAutoGenSnd" BO_ 1279 0;
BA_ "VAGTP20_DynConnection" BO_ 1279 1;
BA_ "GenMsgAutoGenDsp" BO_ 720 0;
BA_ "GenMsgAutoGenSnd" BO_ 720 0;
BA_ "VAGTP20_DynConnection" BO_ 720 1;
BA_ "GenMsgAutoGenDsp" BO_ 721 0;
BA_ "GenMsgAutoGenSnd" BO_ 721 0;
BA_ "VAGTP20_DynConnection" BO_ 721 1;
BA_ "GenMsgAutoGenDsp" BO_ 1250 0;
BA_ "GenMsgAutoGenSnd" BO_ 1250 0;
BA_ "VAGTP20_DynConnection" BO_ 1250 1;
BA_ "GenMsgAutoGenDsp" BO_ 1251 0;
BA_ "GenMsgAutoGenSnd" BO_ 1251 0;
BA_ "VAGTP20_DynConnection" BO_ 1251 1;
BA_ "GenMsgAutoGenDsp" BO_ 1260 0;
BA_ "GenMsgAutoGenSnd" BO_ 1260 0;
BA_ "VAGTP20_DynConnection" BO_ 1260 1;
BA_ "GenMsgAutoGenDsp" BO_ 1240 0;
BA_ "GenMsgAutoGenSnd" BO_ 1240 0;
BA_ "VAGTP20_DynConnection" BO_ 1240 1;
BA_ "GenMsgAutoGenDsp" BO_ 1241 0;
BA_ "GenMsgAutoGenSnd" BO_ 1241 0;
BA_ "VAGTP20_DynConnection" BO_ 1241 1;
BA_ "GenMsgAutoGenDsp" BO_ 1242 0;
BA_ "GenMsgAutoGenSnd" BO_ 1242 0;
BA_ "VAGTP20_DynConnection" BO_ 1242 1;
BA_ "GenMsgAutoGenDsp" BO_ 1243 0;
BA_ "GenMsgAutoGenSnd" BO_ 1243 0;
BA_ "VAGTP20_DynConnection" BO_ 1243 1;
BA_ "GenMsgAutoGenDsp" BO_ 1276 0;
BA_ "GenMsgAutoGenSnd" BO_ 1276 0;
BA_ "VAGTP20_DynConnection" BO_ 1276 1;
BA_ "GenMsgAutoGenDsp" BO_ 1277 0;
BA_ "GenMsgAutoGenSnd" BO_ 1277 0;
BA_ "VAGTP20_DynConnection" BO_ 1277 1;
BA_ "GenMsgAutoGenDsp" BO_ 1248 0;
BA_ "GenMsgAutoGenSnd" BO_ 1248 0;
BA_ "VAGTP20_DynConnection" BO_ 1248 1;
BA_ "GenMsgAutoGenDsp" BO_ 1249 0;
BA_ "GenMsgAutoGenSnd" BO_ 1249 0;
BA_ "VAGTP20_DynConnection" BO_ 1249 1;
BA_ "GenMsgAutoGenDsp" BO_ 804 0;
BA_ "GenMsgAutoGenSnd" BO_ 804 0;
BA_ "VAGTP20_DynConnection" BO_ 804 1;
BA_ "GenMsgAutoGenDsp" BO_ 805 0;
BA_ "GenMsgAutoGenSnd" BO_ 805 0;
BA_ "VAGTP20_DynConnection" BO_ 805 1;
BA_ "GenMsgAutoGenDsp" BO_ 1270 0;
BA_ "GenMsgAutoGenSnd" BO_ 1270 0;
BA_ "VAGTP20_DynConnection" BO_ 1270 1;
BA_ "GenMsgAutoGenDsp" BO_ 1271 0;
BA_ "GenMsgAutoGenSnd" BO_ 1271 0;
BA_ "VAGTP20_DynConnection" BO_ 1271 1;
BA_ "GenMsgAutoGenDsp" BO_ 1264 0;
BA_ "GenMsgAutoGenSnd" BO_ 1264 0;
BA_ "VAGTP20_DynConnection" BO_ 1264 1;
BA_ "GenMsgAutoGenDsp" BO_ 1265 0;
BA_ "GenMsgAutoGenSnd" BO_ 1265 0;
BA_ "VAGTP20_DynConnection" BO_ 1265 1;
BA_ "GenMsgAutoGenDsp" BO_ 1268 0;
BA_ "GenMsgAutoGenSnd" BO_ 1268 0;
BA_ "VAGTP20_DynConnection" BO_ 1268 1;
BA_ "GenMsgAutoGenDsp" BO_ 1269 0;
BA_ "GenMsgAutoGenSnd" BO_ 1269 0;
BA_ "VAGTP20_DynConnection" BO_ 1269 1;
BA_ "GenMsgAutoGenDsp" BO_ 1272 0;
BA_ "GenMsgAutoGenSnd" BO_ 1272 0;
BA_ "VAGTP20_DynConnection" BO_ 1272 1;
BA_ "GenMsgAutoGenDsp" BO_ 1273 0;
BA_ "GenMsgAutoGenSnd" BO_ 1273 0;
BA_ "VAGTP20_DynConnection" BO_ 1273 1;
BA_ "GenMsgAutoGenDsp" BO_ 591 0;
BA_ "GenMsgAutoGenSnd" BO_ 591 0;
BA_ "VAGTP20_DynSetup" BO_ 591 1;
BA_ "GenMsgAutoGenDsp" BO_ 595 0;
BA_ "GenMsgAutoGenSnd" BO_ 595 0;
BA_ "VAGTP20_DynSetup" BO_ 595 1;
BA_ "GenMsgAutoGenDsp" BO_ 584 0;
BA_ "GenMsgAutoGenSnd" BO_ 584 0;
BA_ "VAGTP20_DynSetup" BO_ 584 1;
BA_ "GenMsgAutoGenDsp" BO_ 577 0;
BA_ "GenMsgAutoGenSnd" BO_ 577 0;
BA_ "VAGTP20_DynSetup" BO_ 577 1;
BA_ "GenMsgAutoGenDsp" BO_ 589 0;
BA_ "GenMsgAutoGenSnd" BO_ 589 0;
BA_ "VAGTP20_DynSetup" BO_ 589 1;
BA_ "GenMsgAutoGenDsp" BO_ 576 0;
BA_ "GenMsgAutoGenSnd" BO_ 576 0;
BA_ "VAGTP20_DynSetup" BO_ 576 1;
BA_ "GenMsgAutoGenDsp" BO_ 596 0;
BA_ "GenMsgAutoGenSnd" BO_ 596 0;
BA_ "VAGTP20_DynSetup" BO_ 596 1;
BA_ "GenMsgAutoGenDsp" BO_ 603 0;
BA_ "GenMsgAutoGenSnd" BO_ 603 0;
BA_ "VAGTP20_DynSetup" BO_ 603 1;
BA_ "GenMsgAutoGenDsp" BO_ 594 0;
BA_ "GenMsgAutoGenSnd" BO_ 594 0;
BA_ "VAGTP20_DynSetup" BO_ 594 1;
BA_ "GenMsgAutoGenDsp" BO_ 585 0;
BA_ "GenMsgAutoGenSnd" BO_ 585 0;
BA_ "VAGTP20_DynSetup" BO_ 585 1;
BA_ "GenMsgAutoGenDsp" BO_ 604 0;
BA_ "GenMsgAutoGenSnd" BO_ 604 0;
BA_ "VAGTP20_DynSetup" BO_ 604 1;
BA_ "GenMsgAutoGenDsp" BO_ 559 0;
BA_ "GenMsgAutoGenSnd" BO_ 559 0;
BA_ "VAGTP20_DynSetup" BO_ 559 1;
BA_ "GenMsgAutoGenDsp" BO_ 587 0;
BA_ "GenMsgAutoGenSnd" BO_ 587 0;
BA_ "VAGTP20_DynSetup" BO_ 587 1;
BA_ "GenMsgAutoGenDsp" BO_ 602 0;
BA_ "GenMsgAutoGenSnd" BO_ 602 0;
BA_ "VAGTP20_DynSetup" BO_ 602 1;
BA_ "GenMsgAutoGenDsp" BO_ 597 0;
BA_ "GenMsgAutoGenSnd" BO_ 597 0;
BA_ "VAGTP20_DynSetup" BO_ 597 1;
BA_ "GenMsgAutoGenDsp" BO_ 512 0;
BA_ "GenMsgAutoGenSnd" BO_ 512 0;
BA_ "VAGTP20_DynSetup" BO_ 512 1;
BA_ "GenMsgAutoGenDsp" BO_ 599 0;
BA_ "GenMsgAutoGenSnd" BO_ 599 0;
BA_ "VAGTP20_DynSetup" BO_ 599 1;
BA_ "VAGTP20_StatConnection" BO_ 1729 1;
BA_ "VAGTP20_StatConnection" BO_ 1731 1;
BA_ "VAGTP20_StatConnection" BO_ 1728 1;
BA_ "GenMsgAutoGenDsp" BO_ 1744 0;
BA_ "GenMsgAutoGenSnd" BO_ 1744 0;
BA_ "VAGTP20_API" BO_ 1744 16;
BA_ "VAGTP20_StatConnection" BO_ 1744 1;
BA_ "GenMsgAutoGenDsp" BO_ 1673 0;
BA_ "GenMsgAutoGenSnd" BO_ 1673 0;
BA_ "VAGTP20_API" BO_ 1673 16;
BA_ "VAGTP20_StatConnection" BO_ 1673 1;
BA_ "GenMsgAutoGenDsp" BO_ 1665 0;
BA_ "GenMsgAutoGenSnd" BO_ 1665 0;
BA_ "VAGTP20_API" BO_ 1665 16;
BA_ "VAGTP20_StatConnection" BO_ 1665 1;
BA_ "GenMsgAutoGenDsp" BO_ 1667 0;
BA_ "GenMsgAutoGenSnd" BO_ 1667 0;
BA_ "VAGTP20_API" BO_ 1667 16;
BA_ "VAGTP20_StatConnection" BO_ 1667 1;
BA_ "GenMsgAutoGenDsp" BO_ 1669 0;
BA_ "GenMsgAutoGenSnd" BO_ 1669 0;
BA_ "VAGTP20_API" BO_ 1669 16;
BA_ "VAGTP20_StatConnection" BO_ 1669 1;
BA_ "GenMsgAutoGenDsp" BO_ 1671 0;
BA_ "GenMsgAutoGenSnd" BO_ 1671 0;
BA_ "VAGTP20_API" BO_ 1671 16;
BA_ "VAGTP20_StatConnection" BO_ 1671 1;
BA_ "GenMsgAutoGenDsp" BO_ 1672 0;
BA_ "GenMsgAutoGenSnd" BO_ 1672 0;
BA_ "VAGTP20_API" BO_ 1672 16;
BA_ "VAGTP20_StatConnection" BO_ 1672 1;
BA_ "GenMsgAutoGenDsp" BO_ 1664 0;
BA_ "GenMsgAutoGenSnd" BO_ 1664 0;
BA_ "VAGTP20_API" BO_ 1664 16;
BA_ "VAGTP20_StatConnection" BO_ 1664 1;
BA_ "GenMsgAutoGenDsp" BO_ 1666 0;
BA_ "GenMsgAutoGenSnd" BO_ 1666 0;
BA_ "VAGTP20_API" BO_ 1666 16;
BA_ "VAGTP20_StatConnection" BO_ 1666 1;
BA_ "GenMsgAutoGenDsp" BO_ 1668 0;
BA_ "GenMsgAutoGenSnd" BO_ 1668 0;
BA_ "VAGTP20_API" BO_ 1668 16;
BA_ "VAGTP20_StatConnection" BO_ 1668 1;
BA_ "GenMsgAutoGenDsp" BO_ 1670 0;
BA_ "GenMsgAutoGenSnd" BO_ 1670 0;
BA_ "VAGTP20_API" BO_ 1670 16;
BA_ "VAGTP20_StatConnection" BO_ 1670 1;
BA_ "VAGTP20_StatConnection" BO_ 1730 1;
BA_ "GenMsgCycleTime" BO_ 1538 1000;
BA_ "GenMsgDelayTime" BO_ 1538 100;
BA_ "GenMsgILSupport" BO_ 1538 1;
BA_ "GenMsgSendType" BO_ 1538 0;
BA_ "GenMsgCycleTime" BO_ 1497 100;
BA_ "GenMsgDelayTime" BO_ 1497 10;
BA_ "GenMsgILSupport" BO_ 1497 1;
BA_ "GenMsgSendType" BO_ 1497 0;
BA_ "GenMsgCycleTime" BO_ 707 100;
BA_ "GenMsgDelayTime" BO_ 707 10;
BA_ "GenMsgILSupport" BO_ 707 1;
BA_ "GenMsgSendType" BO_ 707 0;
BA_ "GenSigAutoGenDsp" SG_ 1349 PA3_System_codierung 1;
BA_ "GenSigAutoGenSnd" SG_ 1349 PA3_System_codierung 1;
BA_ "GenSigSendType" SG_ 1349 PA3_System_codierung 3;
BA_ "GenSigAutoGenDsp" SG_ 1349 PA3_Anlage_defekt 1;
BA_ "GenSigAutoGenSnd" SG_ 1349 PA3_Anlage_defekt 1;
BA_ "GenSigSendType" SG_ 1349 PA3_Anlage_defekt 3;
BA_ "GenSigAutoGenDsp" SG_ 1349 PA3_Taster_aktiviert 1;
BA_ "GenSigAutoGenSnd" SG_ 1349 PA3_Taster_aktiviert 1;
BA_ "GenSigSendType" SG_ 1349 PA3_Taster_aktiviert 3;
BA_ "GenSigAutoGenDsp" SG_ 1349 PA3_Rueckwaertsgang_aktiv 1;
BA_ "GenSigAutoGenSnd" SG_ 1349 PA3_Rueckwaertsgang_aktiv 1;
BA_ "GenSigSendType" SG_ 1349 PA3_Rueckwaertsgang_aktiv 3;
BA_ "GenSigAutoGenDsp" SG_ 1349 PA3_Geschwindigkeit_aus 1;
BA_ "GenSigAutoGenSnd" SG_ 1349 PA3_Geschwindigkeit_aus 1;
BA_ "GenSigSendType" SG_ 1349 PA3_Geschwindigkeit_aus 3;
BA_ "GenSigAutoGenDsp" SG_ 1349 PA3_Tongeber_v_defekt 1;
BA_ "GenSigAutoGenSnd" SG_ 1349 PA3_Tongeber_v_defekt 1;
BA_ "GenSigSendType" SG_ 1349 PA3_Tongeber_v_defekt 3;
BA_ "GenSigAutoGenDsp" SG_ 1349 PA3_Tongeber_h_defekt 1;
BA_ "GenSigAutoGenSnd" SG_ 1349 PA3_Tongeber_h_defekt 1;
BA_ "GenSigSendType" SG_ 1349 PA3_Tongeber_h_defekt 3;
BA_ "GenSigAutoGenDsp" SG_ 1349 PA3_Audioabsenkung_Anforderung 1;
BA_ "GenSigAutoGenSnd" SG_ 1349 PA3_Audioabsenkung_Anforderung 1;
BA_ "GenSigSendType" SG_ 1349 PA3_Audioabsenkung_Anforderung 3;
BA_ "GenSigAutoGenDsp" SG_ 1349 PA3_Eis_aus 1;
BA_ "GenSigAutoGenSnd" SG_ 1349 PA3_Eis_aus 1;
BA_ "GenSigSendType" SG_ 1349 PA3_Eis_aus 3;
BA_ "GenSigAutoGenDsp" SG_ 1349 PA3_Schlechtweg_aus 1;
BA_ "GenSigAutoGenSnd" SG_ 1349 PA3_Schlechtweg_aus 1;
BA_ "GenSigSendType" SG_ 1349 PA3_Schlechtweg_aus 3;
BA_ "GenSigAutoGenDsp" SG_ 1349 PA3_KD_Fehler 1;
BA_ "GenSigAutoGenSnd" SG_ 1349 PA3_KD_Fehler 1;
BA_ "GenSigSendType" SG_ 1349 PA3_KD_Fehler 3;
BA_ "GenSigAutoGenDsp" SG_ 1349 PA3_Sensor_hll_defekt 1;
BA_ "GenSigAutoGenSnd" SG_ 1349 PA3_Sensor_hll_defekt 1;
BA_ "GenSigSendType" SG_ 1349 PA3_Sensor_hll_defekt 3;
BA_ "GenSigAutoGenDsp" SG_ 1349 PA3_Sensor_hlm_defekt 1;
BA_ "GenSigAutoGenSnd" SG_ 1349 PA3_Sensor_hlm_defekt 1;
BA_ "GenSigSendType" SG_ 1349 PA3_Sensor_hlm_defekt 3;
BA_ "GenSigAutoGenDsp" SG_ 1349 PA3_Sensor_hrm_defekt 1;
BA_ "GenSigAutoGenSnd" SG_ 1349 PA3_Sensor_hrm_defekt 1;
BA_ "GenSigSendType" SG_ 1349 PA3_Sensor_hrm_defekt 3;
BA_ "GenSigAutoGenDsp" SG_ 1349 PA3_Sensor_hrr_defekt 1;
BA_ "GenSigAutoGenSnd" SG_ 1349 PA3_Sensor_hrr_defekt 1;
BA_ "GenSigSendType" SG_ 1349 PA3_Sensor_hrr_defekt 3;
BA_ "GenSigAutoGenDsp" SG_ 1349 PA3_Sensor_vll_defekt 1;
BA_ "GenSigAutoGenSnd" SG_ 1349 PA3_Sensor_vll_defekt 1;
BA_ "GenSigSendType" SG_ 1349 PA3_Sensor_vll_defekt 3;
BA_ "GenSigAutoGenDsp" SG_ 1349 PA3_Sensor_vlm_defekt 1;
BA_ "GenSigAutoGenSnd" SG_ 1349 PA3_Sensor_vlm_defekt 1;
BA_ "GenSigSendType" SG_ 1349 PA3_Sensor_vlm_defekt 3;
BA_ "GenSigAutoGenDsp" SG_ 1349 PA3_Sensor_vrm_defekt 1;
BA_ "GenSigAutoGenSnd" SG_ 1349 PA3_Sensor_vrm_defekt 1;
BA_ "GenSigSendType" SG_ 1349 PA3_Sensor_vrm_defekt 3;
BA_ "GenSigAutoGenDsp" SG_ 1349 PA3_Sensor_vrr_defekt 1;
BA_ "GenSigAutoGenSnd" SG_ 1349 PA3_Sensor_vrr_defekt 1;
BA_ "GenSigSendType" SG_ 1349 PA3_Sensor_vrr_defekt 3;
BA_ "GenSigAutoGenDsp" SG_ 1349 PA3_Bereit 1;
BA_ "GenSigAutoGenSnd" SG_ 1349 PA3_Bereit 1;
BA_ "GenSigSendType" SG_ 1349 PA3_Bereit 3;
BA_ "GenSigAutoGenDsp" SG_ 1349 PA3_Bereich_vo 1;
BA_ "GenSigAutoGenSnd" SG_ 1349 PA3_Bereich_vo 1;
BA_ "GenSigSendType" SG_ 1349 PA3_Bereich_vo 3;
BA_ "GenSigAutoGenDsp" SG_ 1349 PA3_Bereich_hi 1;
BA_ "GenSigAutoGenSnd" SG_ 1349 PA3_Bereich_hi 1;
BA_ "GenSigSendType" SG_ 1349 PA3_Bereich_hi 3;
BA_ "GenSigAutoGenDsp" SG_ 1349 PA3_Akust_aus 1;
BA_ "GenSigAutoGenSnd" SG_ 1349 PA3_Akust_aus 1;
BA_ "GenSigSendType" SG_ 1349 PA3_Akust_aus 3;
BA_ "GenSigAutoGenDsp" SG_ 1349 PA3_Aufbau_erk 1;
BA_ "GenSigAutoGenSnd" SG_ 1349 PA3_Aufbau_erk 1;
BA_ "GenSigSendType" SG_ 1349 PA3_Aufbau_erk 3;
BA_ "GenSigAutoGenDsp" SG_ 1355 PA5_VL_Abstand 1;
BA_ "GenSigAutoGenSnd" SG_ 1355 PA5_VL_Abstand 1;
BA_ "GenSigInactiveValue" SG_ 1355 PA5_VL_Abstand 255;
BA_ "GenSigSendType" SG_ 1355 PA5_VL_Abstand 5;
BA_ "GenSigStartValue" SG_ 1355 PA5_VL_Abstand 255;
BA_ "GenSigSwitchedByIgnition" SG_ 1355 PA5_VL_Abstand 1;
BA_ "GenSigAutoGenDsp" SG_ 1355 PA5_VR_Abstand 1;
BA_ "GenSigAutoGenSnd" SG_ 1355 PA5_VR_Abstand 1;
BA_ "GenSigInactiveValue" SG_ 1355 PA5_VR_Abstand 255;
BA_ "GenSigSendType" SG_ 1355 PA5_VR_Abstand 5;
BA_ "GenSigStartValue" SG_ 1355 PA5_VR_Abstand 255;
BA_ "GenSigSwitchedByIgnition" SG_ 1355 PA5_VR_Abstand 1;
BA_ "GenSigAutoGenDsp" SG_ 1355 PA5_HL_Abstand 1;
BA_ "GenSigAutoGenSnd" SG_ 1355 PA5_HL_Abstand 1;
BA_ "GenSigInactiveValue" SG_ 1355 PA5_HL_Abstand 255;
BA_ "GenSigSendType" SG_ 1355 PA5_HL_Abstand 5;
BA_ "GenSigStartValue" SG_ 1355 PA5_HL_Abstand 255;
BA_ "GenSigSwitchedByIgnition" SG_ 1355 PA5_HL_Abstand 1;
BA_ "GenSigAutoGenDsp" SG_ 1355 PA5_HR_Abstand 1;
BA_ "GenSigAutoGenSnd" SG_ 1355 PA5_HR_Abstand 1;
BA_ "GenSigInactiveValue" SG_ 1355 PA5_HR_Abstand 255;
BA_ "GenSigSendType" SG_ 1355 PA5_HR_Abstand 5;
BA_ "GenSigStartValue" SG_ 1355 PA5_HR_Abstand 255;
BA_ "GenSigSwitchedByIgnition" SG_ 1355 PA5_HR_Abstand 1;
BA_ "GenSigAutoGenDsp" SG_ 1355 PA5_VML_Abstand 1;
BA_ "GenSigAutoGenSnd" SG_ 1355 PA5_VML_Abstand 1;
BA_ "GenSigInactiveValue" SG_ 1355 PA5_VML_Abstand 255;
BA_ "GenSigSendType" SG_ 1355 PA5_VML_Abstand 5;
BA_ "GenSigStartValue" SG_ 1355 PA5_VML_Abstand 255;
BA_ "GenSigSwitchedByIgnition" SG_ 1355 PA5_VML_Abstand 1;
BA_ "GenSigAutoGenDsp" SG_ 1355 PA5_VMR_Abstand 1;
BA_ "GenSigAutoGenSnd" SG_ 1355 PA5_VMR_Abstand 1;
BA_ "GenSigInactiveValue" SG_ 1355 PA5_VMR_Abstand 255;
BA_ "GenSigSendType" SG_ 1355 PA5_VMR_Abstand 5;
BA_ "GenSigStartValue" SG_ 1355 PA5_VMR_Abstand 255;
BA_ "GenSigSwitchedByIgnition" SG_ 1355 PA5_VMR_Abstand 1;
BA_ "GenSigAutoGenDsp" SG_ 1355 PA5_HML_Abstand 1;
BA_ "GenSigAutoGenSnd" SG_ 1355 PA5_HML_Abstand 1;
BA_ "GenSigInactiveValue" SG_ 1355 PA5_HML_Abstand 255;
BA_ "GenSigSendType" SG_ 1355 PA5_HML_Abstand 5;
BA_ "GenSigStartValue" SG_ 1355 PA5_HML_Abstand 255;
BA_ "GenSigSwitchedByIgnition" SG_ 1355 PA5_HML_Abstand 1;
BA_ "GenSigAutoGenDsp" SG_ 1355 PA5_HMR_Abstand 1;
BA_ "GenSigAutoGenSnd" SG_ 1355 PA5_HMR_Abstand 1;
BA_ "GenSigInactiveValue" SG_ 1355 PA5_HMR_Abstand 255;
BA_ "GenSigSendType" SG_ 1355 PA5_HMR_Abstand 5;
BA_ "GenSigStartValue" SG_ 1355 PA5_HMR_Abstand 255;
BA_ "GenSigSwitchedByIgnition" SG_ 1355 PA5_HMR_Abstand 1;
BA_ "GenSigAutoGenDsp" SG_ 867 RA1_DSP_Zeichen_1 1;
BA_ "GenSigAutoGenSnd" SG_ 867 RA1_DSP_Zeichen_1 1;
BA_ "GenSigSendType" SG_ 867 RA1_DSP_Zeichen_1 3;
BA_ "GenSigAutoGenDsp" SG_ 867 RA1_DSP_Zeichen_2 1;
BA_ "GenSigAutoGenSnd" SG_ 867 RA1_DSP_Zeichen_2 1;
BA_ "GenSigSendType" SG_ 867 RA1_DSP_Zeichen_2 3;
BA_ "GenSigAutoGenDsp" SG_ 867 RA1_DSP_Zeichen_3 1;
BA_ "GenSigAutoGenSnd" SG_ 867 RA1_DSP_Zeichen_3 1;
BA_ "GenSigSendType" SG_ 867 RA1_DSP_Zeichen_3 3;
BA_ "GenSigAutoGenDsp" SG_ 867 RA1_DSP_Zeichen_4 1;
BA_ "GenSigAutoGenSnd" SG_ 867 RA1_DSP_Zeichen_4 1;
BA_ "GenSigSendType" SG_ 867 RA1_DSP_Zeichen_4 3;
BA_ "GenSigAutoGenDsp" SG_ 867 RA1_DSP_Zeichen_5 1;
BA_ "GenSigAutoGenSnd" SG_ 867 RA1_DSP_Zeichen_5 1;
BA_ "GenSigSendType" SG_ 867 RA1_DSP_Zeichen_5 3;
BA_ "GenSigAutoGenDsp" SG_ 867 RA1_DSP_Zeichen_6 1;
BA_ "GenSigAutoGenSnd" SG_ 867 RA1_DSP_Zeichen_6 1;
BA_ "GenSigSendType" SG_ 867 RA1_DSP_Zeichen_6 3;
BA_ "GenSigAutoGenDsp" SG_ 867 RA1_DSP_Zeichen_7 1;
BA_ "GenSigAutoGenSnd" SG_ 867 RA1_DSP_Zeichen_7 1;
BA_ "GenSigSendType" SG_ 867 RA1_DSP_Zeichen_7 3;
BA_ "GenSigAutoGenDsp" SG_ 867 RA1_DSP_Zeichen_8 1;
BA_ "GenSigAutoGenSnd" SG_ 867 RA1_DSP_Zeichen_8 1;
BA_ "GenSigSendType" SG_ 867 RA1_DSP_Zeichen_8 3;
BA_ "GenSigAutoGenDsp" SG_ 869 RA2_DSP_Zeichen_9 1;
BA_ "GenSigAutoGenSnd" SG_ 869 RA2_DSP_Zeichen_9 1;
BA_ "GenSigSendType" SG_ 869 RA2_DSP_Zeichen_9 3;
BA_ "GenSigAutoGenDsp" SG_ 869 RA2_DSP_Zeichen_10 1;
BA_ "GenSigAutoGenSnd" SG_ 869 RA2_DSP_Zeichen_10 1;
BA_ "GenSigSendType" SG_ 869 RA2_DSP_Zeichen_10 3;
BA_ "GenSigAutoGenDsp" SG_ 869 RA2_DSP_Zeichen_11 1;
BA_ "GenSigAutoGenSnd" SG_ 869 RA2_DSP_Zeichen_11 1;
BA_ "GenSigSendType" SG_ 869 RA2_DSP_Zeichen_11 3;
BA_ "GenSigAutoGenDsp" SG_ 869 RA2_DSP_Zeichen_12 1;
BA_ "GenSigAutoGenSnd" SG_ 869 RA2_DSP_Zeichen_12 1;
BA_ "GenSigSendType" SG_ 869 RA2_DSP_Zeichen_12 3;
BA_ "GenSigAutoGenDsp" SG_ 869 RA2_DSP_Zeichen_13 1;
BA_ "GenSigAutoGenSnd" SG_ 869 RA2_DSP_Zeichen_13 1;
BA_ "GenSigSendType" SG_ 869 RA2_DSP_Zeichen_13 3;
BA_ "GenSigAutoGenDsp" SG_ 869 RA2_DSP_Zeichen_14 1;
BA_ "GenSigAutoGenSnd" SG_ 869 RA2_DSP_Zeichen_14 1;
BA_ "GenSigSendType" SG_ 869 RA2_DSP_Zeichen_14 3;
BA_ "GenSigAutoGenDsp" SG_ 869 RA2_DSP_Zeichen_15 1;
BA_ "GenSigAutoGenSnd" SG_ 869 RA2_DSP_Zeichen_15 1;
BA_ "GenSigSendType" SG_ 869 RA2_DSP_Zeichen_15 3;
BA_ "GenSigAutoGenDsp" SG_ 869 RA2_DSP_Zeichen_16 1;
BA_ "GenSigAutoGenSnd" SG_ 869 RA2_DSP_Zeichen_16 1;
BA_ "GenSigSendType" SG_ 869 RA2_DSP_Zeichen_16 3;
BA_ "GenSigAutoGenDsp" SG_ 865 RA3_Radio_SS_1 1;
BA_ "GenSigAutoGenSnd" SG_ 865 RA3_Radio_SS_1 1;
BA_ "GenSigSendType" SG_ 865 RA3_Radio_SS_1 0;
BA_ "GenSigAutoGenDsp" SG_ 865 RA3_Radio_SS_2 1;
BA_ "GenSigAutoGenSnd" SG_ 865 RA3_Radio_SS_2 1;
BA_ "GenSigSendType" SG_ 865 RA3_Radio_SS_2 0;
BA_ "GenSigAutoGenDsp" SG_ 865 RA3_Radio_SS_3 1;
BA_ "GenSigAutoGenSnd" SG_ 865 RA3_Radio_SS_3 1;
BA_ "GenSigSendType" SG_ 865 RA3_Radio_SS_3 0;
BA_ "GenSigAutoGenDsp" SG_ 865 RA3_Radio_SS_4 1;
BA_ "GenSigAutoGenSnd" SG_ 865 RA3_Radio_SS_4 1;
BA_ "GenSigSendType" SG_ 865 RA3_Radio_SS_4 0;
BA_ "GenSigAutoGenDsp" SG_ 865 RA3_Adress 1;
BA_ "GenSigAutoGenSnd" SG_ 865 RA3_Adress 1;
BA_ "GenSigSendType" SG_ 865 RA3_Adress 0;
BA_ "GenSigAutoGenDsp" SG_ 1633 RA4_Radio_on 1;
BA_ "GenSigAutoGenSnd" SG_ 1633 RA4_Radio_on 1;
BA_ "GenSigSendType" SG_ 1633 RA4_Radio_on 3;
BA_ "GenSigAutoGenDsp" SG_ 1633 RA4_Show_Radio 1;
BA_ "GenSigAutoGenSnd" SG_ 1633 RA4_Show_Radio 1;
BA_ "GenSigSendType" SG_ 1633 RA4_Show_Radio 3;
BA_ "GenSigAutoGenDsp" SG_ 1633 RA4_Radio_mute 1;
BA_ "GenSigAutoGenSnd" SG_ 1633 RA4_Radio_mute 1;
BA_ "GenSigSendType" SG_ 1633 RA4_Radio_mute 3;
BA_ "GenSigAutoGenDsp" SG_ 1633 RA4_Radio_Master_locked 1;
BA_ "GenSigAutoGenSnd" SG_ 1633 RA4_Radio_Master_locked 1;
BA_ "GenSigSendType" SG_ 1633 RA4_Radio_Master_locked 3;
BA_ "GenSigAutoGenDsp" SG_ 1633 RA4_VNC_OFF 1;
BA_ "GenSigAutoGenSnd" SG_ 1633 RA4_VNC_OFF 1;
BA_ "GenSigSendType" SG_ 1633 RA4_VNC_OFF 3;
BA_ "GenSigAutoGenDsp" SG_ 1633 RA4_Radio_Surround 1;
BA_ "GenSigAutoGenSnd" SG_ 1633 RA4_Radio_Surround 1;
BA_ "GenSigSendType" SG_ 1633 RA4_Radio_Surround 3;
BA_ "GenSigAutoGenDsp" SG_ 1633 RA4_Radio_Wake_Up_Komfort 1;
BA_ "GenSigAutoGenSnd" SG_ 1633 RA4_Radio_Wake_Up_Komfort 1;
BA_ "GenSigSendType" SG_ 1633 RA4_Radio_Wake_Up_Komfort 3;
BA_ "GenSigAutoGenDsp" SG_ 1633 RA4_Radio_Error_flag 1;
BA_ "GenSigAutoGenSnd" SG_ 1633 RA4_Radio_Error_flag 1;
BA_ "GenSigSendType" SG_ 1633 RA4_Radio_Error_flag 3;
BA_ "GenSigAutoGenDsp" SG_ 1633 RA4_Radio_Mode 1;
BA_ "GenSigAutoGenSnd" SG_ 1633 RA4_Radio_Mode 1;
BA_ "GenSigSendType" SG_ 1633 RA4_Radio_Mode 3;
BA_ "GenSigAutoGenDsp" SG_ 1633 RA4_Radio_Para1 1;
BA_ "GenSigAutoGenSnd" SG_ 1633 RA4_Radio_Para1 1;
BA_ "GenSigSendType" SG_ 1633 RA4_Radio_Para1 3;
BA_ "GenSigAutoGenDsp" SG_ 1633 RA4_Radio_Para2 1;
BA_ "GenSigAutoGenSnd" SG_ 1633 RA4_Radio_Para2 1;
BA_ "GenSigSendType" SG_ 1633 RA4_Radio_Para2 3;
BA_ "GenSigAutoGenDsp" SG_ 1633 RA4_Radio_Para3 1;
BA_ "GenSigAutoGenSnd" SG_ 1633 RA4_Radio_Para3 1;
BA_ "GenSigSendType" SG_ 1633 RA4_Radio_Para3 3;
BA_ "GenSigAutoGenDsp" SG_ 1633 RA4_Radio_Para4 1;
BA_ "GenSigAutoGenSnd" SG_ 1633 RA4_Radio_Para4 1;
BA_ "GenSigSendType" SG_ 1633 RA4_Radio_Para4 3;
BA_ "GenSigAutoGenDsp" SG_ 1633 RA4_Radio_Para5 1;
BA_ "GenSigAutoGenSnd" SG_ 1633 RA4_Radio_Para5 1;
BA_ "GenSigSendType" SG_ 1633 RA4_Radio_Para5 3;
BA_ "GenSigAutoGenDsp" SG_ 1633 RA4_Radio_Para6 1;
BA_ "GenSigAutoGenSnd" SG_ 1633 RA4_Radio_Para6 1;
BA_ "GenSigSendType" SG_ 1633 RA4_Radio_Para6 3;
BA_ "GenSigAutoGenDsp" SG_ 1121 RA6_Ziel 1;
BA_ "GenSigAutoGenSnd" SG_ 1121 RA6_Ziel 1;
BA_ "GenSigSendType" SG_ 1121 RA6_Ziel 6;
BA_ "GenSigAutoGenDsp" SG_ 1121 RA6_Command 1;
BA_ "GenSigAutoGenSnd" SG_ 1121 RA6_Command 1;
BA_ "GenSigSendType" SG_ 1121 RA6_Command 6;
BA_ "GenSigAutoGenDsp" SG_ 1121 RA6_Operand_0 1;
BA_ "GenSigAutoGenSnd" SG_ 1121 RA6_Operand_0 1;
BA_ "GenSigSendType" SG_ 1121 RA6_Operand_0 6;
BA_ "GenSigAutoGenDsp" SG_ 1121 RA6_Operand_1 1;
BA_ "GenSigAutoGenSnd" SG_ 1121 RA6_Operand_1 1;
BA_ "GenSigSendType" SG_ 1121 RA6_Operand_1 6;
BA_ "GenSigAutoGenDsp" SG_ 1121 RA6_Operand_2 1;
BA_ "GenSigAutoGenSnd" SG_ 1121 RA6_Operand_2 1;
BA_ "GenSigSendType" SG_ 1121 RA6_Operand_2 6;
BA_ "GenSigAutoGenDsp" SG_ 1121 RA6_Operand_3 1;
BA_ "GenSigAutoGenSnd" SG_ 1121 RA6_Operand_3 1;
BA_ "GenSigSendType" SG_ 1121 RA6_Operand_3 6;
BA_ "GenSigAutoGenDsp" SG_ 1347 RV1_Video_On 1;
BA_ "GenSigAutoGenSnd" SG_ 1347 RV1_Video_On 1;
BA_ "GenSigSendType" SG_ 1347 RV1_Video_On 3;
BA_ "GenSigAutoGenDsp" SG_ 1347 RV1_Dark_Screen 1;
BA_ "GenSigAutoGenSnd" SG_ 1347 RV1_Dark_Screen 1;
BA_ "GenSigSendType" SG_ 1347 RV1_Dark_Screen 3;
BA_ "GenSigAutoGenDsp" SG_ 1347 RV1_HMI_Mode 1;
BA_ "GenSigAutoGenSnd" SG_ 1347 RV1_HMI_Mode 1;
BA_ "GenSigSendType" SG_ 1347 RV1_HMI_Mode 3;
BA_ "GenSigAutoGenDsp" SG_ 1347 RV1_System_Aktiv 1;
BA_ "GenSigAutoGenSnd" SG_ 1347 RV1_System_Aktiv 1;
BA_ "GenSigSendType" SG_ 1347 RV1_System_Aktiv 3;
BA_ "GenSigAutoGenDsp" SG_ 1347 RV1_KD_Fehler 1;
BA_ "GenSigAutoGenSnd" SG_ 1347 RV1_KD_Fehler 1;
BA_ "GenSigSendType" SG_ 1347 RV1_KD_Fehler 3;
BA_ "GenSigAutoGenDsp" SG_ 1347 RV1_Settings_Enabled 1;
BA_ "GenSigAutoGenSnd" SG_ 1347 RV1_Settings_Enabled 1;
BA_ "GenSigSendType" SG_ 1347 RV1_Settings_Enabled 3;
BA_ "GenSigAutoGenDsp" SG_ 1347 RV1_Menu_Item 1;
BA_ "GenSigAutoGenSnd" SG_ 1347 RV1_Menu_Item 1;
BA_ "GenSigSendType" SG_ 1347 RV1_Menu_Item 3;
BA_ "GenSigAutoGenDsp" SG_ 1347 RV1_Helligkeit 1;
BA_ "GenSigAutoGenSnd" SG_ 1347 RV1_Helligkeit 1;
BA_ "GenSigSendType" SG_ 1347 RV1_Helligkeit 3;
BA_ "GenSigAutoGenDsp" SG_ 1347 RV1_Kontrast 1;
BA_ "GenSigAutoGenSnd" SG_ 1347 RV1_Kontrast 1;
BA_ "GenSigSendType" SG_ 1347 RV1_Kontrast 3;
BA_ "GenSigAutoGenDsp" SG_ 1347 RV1_Farbe 1;
BA_ "GenSigAutoGenSnd" SG_ 1347 RV1_Farbe 1;
BA_ "GenSigSendType" SG_ 1347 RV1_Farbe 3;
BA_ "GenSigAutoGenDsp" SG_ 1445 SB1_SBS_Destination 1;
BA_ "GenSigAutoGenSnd" SG_ 1445 SB1_SBS_Destination 1;
BA_ "GenSigSendType" SG_ 1445 SB1_SBS_Destination 3;
BA_ "GenSigAutoGenDsp" SG_ 1445 SB1_SBS_Funktion 1;
BA_ "GenSigAutoGenSnd" SG_ 1445 SB1_SBS_Funktion 1;
BA_ "GenSigSendType" SG_ 1445 SB1_SBS_Funktion 3;
BA_ "GenSigAutoGenDsp" SG_ 1445 SB1_SBS_Para1 1;
BA_ "GenSigAutoGenSnd" SG_ 1445 SB1_SBS_Para1 1;
BA_ "GenSigSendType" SG_ 1445 SB1_SBS_Para1 3;
BA_ "GenSigAutoGenDsp" SG_ 1445 SB1_SBS_Para2 1;
BA_ "GenSigAutoGenSnd" SG_ 1445 SB1_SBS_Para2 1;
BA_ "GenSigSendType" SG_ 1445 SB1_SBS_Para2 3;
BA_ "GenSigAutoGenDsp" SG_ 1445 SB1_SBS_Para3 1;
BA_ "GenSigAutoGenSnd" SG_ 1445 SB1_SBS_Para3 1;
BA_ "GenSigSendType" SG_ 1445 SB1_SBS_Para3 3;
BA_ "GenSigAutoGenDsp" SG_ 1445 SB1_SBS_Para4 1;
BA_ "GenSigAutoGenSnd" SG_ 1445 SB1_SBS_Para4 1;
BA_ "GenSigSendType" SG_ 1445 SB1_SBS_Para4 3;
BA_ "GenSigAutoGenDsp" SG_ 1445 SB1_SBS_Para5 1;
BA_ "GenSigAutoGenSnd" SG_ 1445 SB1_SBS_Para5 1;
BA_ "GenSigSendType" SG_ 1445 SB1_SBS_Para5 3;
BA_ "GenSigAutoGenDsp" SG_ 1445 SB1_SBS_Para6 1;
BA_ "GenSigAutoGenSnd" SG_ 1445 SB1_SBS_Para6 1;
BA_ "GenSigSendType" SG_ 1445 SB1_SBS_Para6 3;
BA_ "GenSigAutoGenDsp" SG_ 1451 SB3_SBS_on 1;
BA_ "GenSigAutoGenSnd" SG_ 1451 SB3_SBS_on 1;
BA_ "GenSigSendType" SG_ 1451 SB3_SBS_on 3;
BA_ "GenSigAutoGenDsp" SG_ 1451 SB3_Show_SBS 1;
BA_ "GenSigAutoGenSnd" SG_ 1451 SB3_Show_SBS 1;
BA_ "GenSigSendType" SG_ 1451 SB3_Show_SBS 3;
BA_ "GenSigAutoGenDsp" SG_ 1451 SB3_SBS_mute 1;
BA_ "GenSigAutoGenSnd" SG_ 1451 SB3_SBS_mute 1;
BA_ "GenSigSendType" SG_ 1451 SB3_SBS_mute 3;
BA_ "GenSigAutoGenDsp" SG_ 1451 SB3_SBS_com_send 1;
BA_ "GenSigAutoGenSnd" SG_ 1451 SB3_SBS_com_send 1;
BA_ "GenSigSendType" SG_ 1451 SB3_SBS_com_send 3;
BA_ "GenSigAutoGenDsp" SG_ 1451 SB3_SBS_active 1;
BA_ "GenSigAutoGenSnd" SG_ 1451 SB3_SBS_active 1;
BA_ "GenSigSendType" SG_ 1451 SB3_SBS_active 3;
BA_ "GenSigAutoGenDsp" SG_ 1451 SB3_SBS_Error_flag 1;
BA_ "GenSigAutoGenSnd" SG_ 1451 SB3_SBS_Error_flag 1;
BA_ "GenSigSendType" SG_ 1451 SB3_SBS_Error_flag 3;
BA_ "GenSigAutoGenDsp" SG_ 1451 SB3_SBS_Level 1;
BA_ "GenSigAutoGenSnd" SG_ 1451 SB3_SBS_Level 1;
BA_ "GenSigSendType" SG_ 1451 SB3_SBS_Level 3;
BA_ "GenSigAutoGenDsp" SG_ 1451 SB3_SBS_Display_Vol 1;
BA_ "GenSigAutoGenSnd" SG_ 1451 SB3_SBS_Display_Vol 1;
BA_ "GenSigSendType" SG_ 1451 SB3_SBS_Display_Vol 3;
BA_ "GenSigAutoGenDsp" SG_ 1621 VBN_Motor_A 1;
BA_ "GenSigAutoGenSnd" SG_ 1621 VBN_Motor_A 1;
BA_ "GenSigSendType" SG_ 1621 VBN_Motor_A 0;
BA_ "GenSigAutoGenDsp" SG_ 1621 VBN_Getriebe_A 1;
BA_ "GenSigAutoGenSnd" SG_ 1621 VBN_Getriebe_A 1;
BA_ "GenSigSendType" SG_ 1621 VBN_Getriebe_A 0;
BA_ "GenSigAutoGenDsp" SG_ 1621 VBN_Bremse_A 1;
BA_ "GenSigAutoGenSnd" SG_ 1621 VBN_Bremse_A 1;
BA_ "GenSigSendType" SG_ 1621 VBN_Bremse_A 0;
BA_ "GenSigAutoGenDsp" SG_ 1621 VBN_Kombi_A 1;
BA_ "GenSigAutoGenSnd" SG_ 1621 VBN_Kombi_A 1;
BA_ "GenSigSendType" SG_ 1621 VBN_Kombi_A 0;
BA_ "GenSigAutoGenDsp" SG_ 1621 VBN_LSM_A 1;
BA_ "GenSigAutoGenSnd" SG_ 1621 VBN_LSM_A 1;
BA_ "GenSigSendType" SG_ 1621 VBN_LSM_A 0;
BA_ "GenSigAutoGenDsp" SG_ 1621 VBN_Airbag_A 1;
BA_ "GenSigAutoGenSnd" SG_ 1621 VBN_Airbag_A 1;
BA_ "GenSigSendType" SG_ 1621 VBN_Airbag_A 0;
BA_ "GenSigAutoGenDsp" SG_ 1621 VBN_Lenkhilfe_A 1;
BA_ "GenSigAutoGenSnd" SG_ 1621 VBN_Lenkhilfe_A 1;
BA_ "GenSigSendType" SG_ 1621 VBN_Lenkhilfe_A 0;
BA_ "GenSigAutoGenDsp" SG_ 1621 VBN_dyn_LWR_A 1;
BA_ "GenSigAutoGenSnd" SG_ 1621 VBN_dyn_LWR_A 1;
BA_ "GenSigSendType" SG_ 1621 VBN_dyn_LWR_A 0;
BA_ "GenSigAutoGenDsp" SG_ 1621 VBN_Niveau_A 1;
BA_ "GenSigAutoGenSnd" SG_ 1621 VBN_Niveau_A 1;
BA_ "GenSigSendType" SG_ 1621 VBN_Niveau_A 0;
BA_ "GenSigAutoGenDsp" SG_ 1621 VBN_Allrad_A 1;
BA_ "GenSigAutoGenSnd" SG_ 1621 VBN_Allrad_A 1;
BA_ "GenSigSendType" SG_ 1621 VBN_Allrad_A 0;
BA_ "GenSigAutoGenDsp" SG_ 1621 VBN_ADR_Sensor_A 1;
BA_ "GenSigAutoGenSnd" SG_ 1621 VBN_ADR_Sensor_A 1;
BA_ "GenSigSendType" SG_ 1621 VBN_ADR_Sensor_A 0;
BA_ "GenSigAutoGenDsp" SG_ 1621 VBN_ADR_getrennt 1;
BA_ "GenSigAutoGenSnd" SG_ 1621 VBN_ADR_getrennt 1;
BA_ "GenSigSendType" SG_ 1621 VBN_ADR_getrennt 0;
BA_ "GenSigAutoGenDsp" SG_ 1621 VBN_Parkbremse_A 1;
BA_ "GenSigAutoGenSnd" SG_ 1621 VBN_Parkbremse_A 1;
BA_ "GenSigSendType" SG_ 1621 VBN_Parkbremse_A 0;
BA_ "GenSigAutoGenDsp" SG_ 1621 VBN_EZS_A 1;
BA_ "GenSigAutoGenSnd" SG_ 1621 VBN_EZS_A 1;
BA_ "GenSigSendType" SG_ 1621 VBN_EZS_A 0;
BA_ "GenSigAutoGenDsp" SG_ 1621 VBN_Daempfer_A 1;
BA_ "GenSigAutoGenSnd" SG_ 1621 VBN_Daempfer_A 1;
BA_ "GenSigSendType" SG_ 1621 VBN_Daempfer_A 0;
BA_ "GenSigAutoGenDsp" SG_ 1621 VBN_Quersperre 1;
BA_ "GenSigAutoGenSnd" SG_ 1621 VBN_Quersperre 1;
BA_ "GenSigSendType" SG_ 1621 VBN_Quersperre 0;
BA_ "GenSigAutoGenDsp" SG_ 1621 VBN_Motor_Slave_A 1;
BA_ "GenSigAutoGenSnd" SG_ 1621 VBN_Motor_Slave_A 1;
BA_ "GenSigSendType" SG_ 1621 VBN_Motor_Slave_A 0;
BA_ "GenSigAutoGenDsp" SG_ 1621 VBN_SWA_A 1;
BA_ "GenSigAutoGenSnd" SG_ 1621 VBN_SWA_A 1;
BA_ "GenSigSendType" SG_ 1621 VBN_SWA_A 0;
BA_ "GenSigAutoGenDsp" SG_ 1621 VBN_LDW_A 1;
BA_ "GenSigAutoGenSnd" SG_ 1621 VBN_LDW_A 1;
BA_ "GenSigSendType" SG_ 1621 VBN_LDW_A 0;
BA_ "GenSigAutoGenDsp" SG_ 1621 VBN_RKA_Plus_A 1;
BA_ "GenSigAutoGenSnd" SG_ 1621 VBN_RKA_Plus_A 1;
BA_ "GenSigSendType" SG_ 1621 VBN_RKA_Plus_A 0;
BA_ "GenSigAutoGenDsp" SG_ 1621 VBN_PLA_A 1;
BA_ "GenSigAutoGenSnd" SG_ 1621 VBN_PLA_A 1;
BA_ "GenSigSendType" SG_ 1621 VBN_PLA_A 0;
BA_ "GenSigAutoGenDsp" SG_ 1621 VBN_WFS_KBI 1;
BA_ "GenSigAutoGenSnd" SG_ 1621 VBN_WFS_KBI 1;
BA_ "GenSigSendType" SG_ 1621 VBN_WFS_KBI 0;
BA_ "GenSigAutoGenDsp" SG_ 1621 VBN_Kombi_KBI 1;
BA_ "GenSigAutoGenSnd" SG_ 1621 VBN_Kombi_KBI 1;
BA_ "GenSigSendType" SG_ 1621 VBN_Kombi_KBI 0;
BA_ "GenSigAutoGenDsp" SG_ 1621 VBN_Soll_Ist_OK 1;
BA_ "GenSigAutoGenSnd" SG_ 1621 VBN_Soll_Ist_OK 1;
BA_ "GenSigSendType" SG_ 1621 VBN_Soll_Ist_OK 0;
BA_ "GenSigAutoGenDsp" SG_ 1621 VBN_BSG_K 1;
BA_ "GenSigAutoGenSnd" SG_ 1621 VBN_BSG_K 1;
BA_ "GenSigSendType" SG_ 1621 VBN_BSG_K 0;
BA_ "GenSigAutoGenDsp" SG_ 1621 VBN_KSG_K 1;
BA_ "GenSigAutoGenSnd" SG_ 1621 VBN_KSG_K 1;
BA_ "GenSigSendType" SG_ 1621 VBN_KSG_K 0;
BA_ "GenSigAutoGenDsp" SG_ 1621 VBN_TSG_FT_K 1;
BA_ "GenSigAutoGenSnd" SG_ 1621 VBN_TSG_FT_K 1;
BA_ "GenSigSendType" SG_ 1621 VBN_TSG_FT_K 0;
BA_ "GenSigAutoGenDsp" SG_ 1621 VBN_TSG_BT_K 1;
BA_ "GenSigAutoGenSnd" SG_ 1621 VBN_TSG_BT_K 1;
BA_ "GenSigSendType" SG_ 1621 VBN_TSG_BT_K 0;
BA_ "GenSigAutoGenDsp" SG_ 1621 VBN_TSG_HL_K 1;
BA_ "GenSigAutoGenSnd" SG_ 1621 VBN_TSG_HL_K 1;
BA_ "GenSigSendType" SG_ 1621 VBN_TSG_HL_K 0;
BA_ "GenSigAutoGenDsp" SG_ 1621 VBN_TSG_HR_K 1;
BA_ "GenSigAutoGenSnd" SG_ 1621 VBN_TSG_HR_K 1;
BA_ "GenSigSendType" SG_ 1621 VBN_TSG_HR_K 0;
BA_ "GenSigAutoGenDsp" SG_ 1621 VBN_Memory_K 1;
BA_ "GenSigAutoGenSnd" SG_ 1621 VBN_Memory_K 1;
BA_ "GenSigSendType" SG_ 1621 VBN_Memory_K 0;
BA_ "GenSigAutoGenDsp" SG_ 1621 VBN_Dachmodul_K 1;
BA_ "GenSigAutoGenSnd" SG_ 1621 VBN_Dachmodul_K 1;
BA_ "GenSigSendType" SG_ 1621 VBN_Dachmodul_K 0;
BA_ "GenSigAutoGenDsp" SG_ 1621 VBN_Zentralelektrik_II_K 1;
BA_ "GenSigAutoGenSnd" SG_ 1621 VBN_Zentralelektrik_II_K 1;
BA_ "GenSigSendType" SG_ 1621 VBN_Zentralelektrik_II_K 0;
BA_ "GenSigAutoGenDsp" SG_ 1621 VBN_RDK_K 1;
BA_ "GenSigAutoGenSnd" SG_ 1621 VBN_RDK_K 1;
BA_ "GenSigSendType" SG_ 1621 VBN_RDK_K 0;
BA_ "GenSigAutoGenDsp" SG_ 1621 VBN_SMLS_K 1;
BA_ "GenSigAutoGenSnd" SG_ 1621 VBN_SMLS_K 1;
BA_ "GenSigSendType" SG_ 1621 VBN_SMLS_K 0;
BA_ "GenSigAutoGenDsp" SG_ 1621 VBN_Gateway_K 1;
BA_ "GenSigAutoGenSnd" SG_ 1621 VBN_Gateway_K 1;
BA_ "GenSigSendType" SG_ 1621 VBN_Gateway_K 0;
BA_ "GenSigAutoGenDsp" SG_ 1621 VBN_Clima_K 1;
BA_ "GenSigAutoGenSnd" SG_ 1621 VBN_Clima_K 1;
BA_ "GenSigSendType" SG_ 1621 VBN_Clima_K 0;
BA_ "GenSigAutoGenDsp" SG_ 1621 VBN_APS_K 1;
BA_ "GenSigAutoGenSnd" SG_ 1621 VBN_APS_K 1;
BA_ "GenSigSendType" SG_ 1621 VBN_APS_K 0;
BA_ "GenSigAutoGenDsp" SG_ 1621 VBN_PTC_Heizung_K 1;
BA_ "GenSigAutoGenSnd" SG_ 1621 VBN_PTC_Heizung_K 1;
BA_ "GenSigSendType" SG_ 1621 VBN_PTC_Heizung_K 0;
BA_ "GenSigAutoGenDsp" SG_ 1621 VBN_Standhzg_K 1;
BA_ "GenSigAutoGenSnd" SG_ 1621 VBN_Standhzg_K 1;
BA_ "GenSigSendType" SG_ 1621 VBN_Standhzg_K 0;
BA_ "GenSigAutoGenDsp" SG_ 1621 VBN_VSG_K 1;
BA_ "GenSigAutoGenSnd" SG_ 1621 VBN_VSG_K 1;
BA_ "GenSigSendType" SG_ 1621 VBN_VSG_K 0;
BA_ "GenSigAutoGenDsp" SG_ 1621 VBN_RSE_I 1;
BA_ "GenSigAutoGenSnd" SG_ 1621 VBN_RSE_I 1;
BA_ "GenSigSendType" SG_ 1621 VBN_RSE_I 0;
BA_ "GenSigAutoGenDsp" SG_ 1621 VBN_Wischer_K 1;
BA_ "GenSigAutoGenSnd" SG_ 1621 VBN_Wischer_K 1;
BA_ "GenSigSendType" SG_ 1621 VBN_Wischer_K 0;
BA_ "GenSigAutoGenDsp" SG_ 1621 VBN_MDI_I 1;
BA_ "GenSigAutoGenSnd" SG_ 1621 VBN_MDI_I 1;
BA_ "GenSigSendType" SG_ 1621 VBN_MDI_I 0;
BA_ "GenSigAutoGenDsp" SG_ 1621 VBN_AAG_K 1;
BA_ "GenSigAutoGenSnd" SG_ 1621 VBN_AAG_K 1;
BA_ "GenSigSendType" SG_ 1621 VBN_AAG_K 0;
BA_ "GenSigAutoGenDsp" SG_ 1621 VBN_Mem_BF_K 1;
BA_ "GenSigAutoGenSnd" SG_ 1621 VBN_Mem_BF_K 1;
BA_ "GenSigSendType" SG_ 1621 VBN_Mem_BF_K 0;
BA_ "GenSigAutoGenDsp" SG_ 1621 VBN_Easy_Entry_VF 1;
BA_ "GenSigAutoGenSnd" SG_ 1621 VBN_Easy_Entry_VF 1;
BA_ "GenSigSendType" SG_ 1621 VBN_Easy_Entry_VF 0;
BA_ "GenSigAutoGenDsp" SG_ 1621 VBN_Easy_Entry_VB 1;
BA_ "GenSigAutoGenSnd" SG_ 1621 VBN_Easy_Entry_VB 1;
BA_ "GenSigSendType" SG_ 1621 VBN_Easy_Entry_VB 0;
BA_ "GenSigAutoGenDsp" SG_ 1621 VBN_Heckdeckel_K 1;
BA_ "GenSigAutoGenSnd" SG_ 1621 VBN_Heckdeckel_K 1;
BA_ "GenSigSendType" SG_ 1621 VBN_Heckdeckel_K 0;
BA_ "GenSigAutoGenDsp" SG_ 1621 VBN_Rearview_I 1;
BA_ "GenSigAutoGenSnd" SG_ 1621 VBN_Rearview_I 1;
BA_ "GenSigSendType" SG_ 1621 VBN_Rearview_I 0;
BA_ "GenSigAutoGenDsp" SG_ 1621 VBN_Sonderfahrzeug_SG_K 1;
BA_ "GenSigAutoGenSnd" SG_ 1621 VBN_Sonderfahrzeug_SG_K 1;
BA_ "GenSigSendType" SG_ 1621 VBN_Sonderfahrzeug_SG_K 0;
BA_ "GenSigAutoGenDsp" SG_ 1621 VBN_Tastenmodul_I 1;
BA_ "GenSigAutoGenSnd" SG_ 1621 VBN_Tastenmodul_I 1;
BA_ "GenSigSendType" SG_ 1621 VBN_Tastenmodul_I 0;
BA_ "GenSigAutoGenDsp" SG_ 1621 VBN_Kompass_I 1;
BA_ "GenSigAutoGenSnd" SG_ 1621 VBN_Kompass_I 1;
BA_ "GenSigSendType" SG_ 1621 VBN_Kompass_I 0;
BA_ "GenSigAutoGenDsp" SG_ 1621 VBN_WFS_K 1;
BA_ "GenSigAutoGenSnd" SG_ 1621 VBN_WFS_K 1;
BA_ "GenSigSendType" SG_ 1621 VBN_WFS_K 0;
BA_ "GenSigAutoGenDsp" SG_ 1621 VBN_GSM_Pager_I 1;
BA_ "GenSigAutoGenSnd" SG_ 1621 VBN_GSM_Pager_I 1;
BA_ "GenSigSendType" SG_ 1621 VBN_GSM_Pager_I 0;
BA_ "GenSigAutoGenDsp" SG_ 1621 VBN_InfoElektronik 1;
BA_ "GenSigAutoGenSnd" SG_ 1621 VBN_InfoElektronik 1;
BA_ "GenSigSendType" SG_ 1621 VBN_InfoElektronik 0;
BA_ "GenSigAutoGenDsp" SG_ 1621 VBN_DSP_I 1;
BA_ "GenSigAutoGenSnd" SG_ 1621 VBN_DSP_I 1;
BA_ "GenSigSendType" SG_ 1621 VBN_DSP_I 0;
BA_ "GenSigAutoGenDsp" SG_ 1621 VBN_DAB_I 1;
BA_ "GenSigAutoGenSnd" SG_ 1621 VBN_DAB_I 1;
BA_ "GenSigSendType" SG_ 1621 VBN_DAB_I 0;
BA_ "GenSigAutoGenDsp" SG_ 1621 VBN_Telematik_I 1;
BA_ "GenSigAutoGenSnd" SG_ 1621 VBN_Telematik_I 1;
BA_ "GenSigSendType" SG_ 1621 VBN_Telematik_I 0;
BA_ "GenSigAutoGenDsp" SG_ 1621 VBN_Navigation_I 1;
BA_ "GenSigAutoGenSnd" SG_ 1621 VBN_Navigation_I 1;
BA_ "GenSigSendType" SG_ 1621 VBN_Navigation_I 0;
BA_ "GenSigAutoGenDsp" SG_ 1621 VBN_TV_Tuner_I 1;
BA_ "GenSigAutoGenSnd" SG_ 1621 VBN_TV_Tuner_I 1;
BA_ "GenSigSendType" SG_ 1621 VBN_TV_Tuner_I 0;
BA_ "GenSigAutoGenDsp" SG_ 1621 VBN_Neigungsmodul_I 1;
BA_ "GenSigAutoGenSnd" SG_ 1621 VBN_Neigungsmodul_I 1;
BA_ "GenSigSendType" SG_ 1621 VBN_Neigungsmodul_I 0;
BA_ "GenSigAutoGenDsp" SG_ 1621 VBN_Radio_I 1;
BA_ "GenSigAutoGenSnd" SG_ 1621 VBN_Radio_I 1;
BA_ "GenSigSendType" SG_ 1621 VBN_Radio_I 0;
BA_ "GenSigAutoGenDsp" SG_ 1621 VBN_Telefon_I 1;
BA_ "GenSigAutoGenSnd" SG_ 1621 VBN_Telefon_I 1;
BA_ "GenSigSendType" SG_ 1621 VBN_Telefon_I 0;
BA_ "GenSigAutoGenDsp" SG_ 997 SH1_Funk_ein 1;
BA_ "GenSigAutoGenSnd" SG_ 997 SH1_Funk_ein 1;
BA_ "GenSigSendType" SG_ 997 SH1_Funk_ein 3;
BA_ "GenSigAutoGenDsp" SG_ 997 SH1_Funk_aus 1;
BA_ "GenSigAutoGenSnd" SG_ 997 SH1_Funk_aus 1;
BA_ "GenSigSendType" SG_ 997 SH1_Funk_aus 3;
BA_ "GenSigAutoGenDsp" SG_ 997 SH1_FunkSH_Ein 1;
BA_ "GenSigAutoGenSnd" SG_ 997 SH1_FunkSH_Ein 1;
BA_ "GenSigSendType" SG_ 997 SH1_FunkSH_Ein 3;
BA_ "GenSigAutoGenDsp" SG_ 997 SH1_FunkStLftg 1;
BA_ "GenSigAutoGenSnd" SG_ 997 SH1_FunkStLftg 1;
BA_ "GenSigSendType" SG_ 997 SH1_FunkStLftg 3;
BA_ "GenSigAutoGenDsp" SG_ 997 SH1_Clima_aus 1;
BA_ "GenSigAutoGenSnd" SG_ 997 SH1_Clima_aus 1;
BA_ "GenSigSendType" SG_ 997 SH1_Clima_aus 3;
BA_ "GenSigAutoGenDsp" SG_ 997 SH1_SH_Modus 1;
BA_ "GenSigAutoGenSnd" SG_ 997 SH1_SH_Modus 1;
BA_ "GenSigSendType" SG_ 997 SH1_SH_Modus 3;
BA_ "GenSigAutoGenDsp" SG_ 997 SH1_Prog_Modus 1;
BA_ "GenSigAutoGenSnd" SG_ 997 SH1_Prog_Modus 1;
BA_ "GenSigSendType" SG_ 997 SH1_Prog_Modus 3;
BA_ "GenSigAutoGenDsp" SG_ 997 SH1_Wake_Up_Komfort 1;
BA_ "GenSigAutoGenSnd" SG_ 997 SH1_Wake_Up_Komfort 1;
BA_ "GenSigSendType" SG_ 997 SH1_Wake_Up_Komfort 3;
BA_ "GenSigAutoGenDsp" SG_ 997 SH1_Geblaese 1;
BA_ "GenSigAutoGenSnd" SG_ 997 SH1_Geblaese 1;
BA_ "GenSigSendType" SG_ 997 SH1_Geblaese 3;
BA_ "GenSigAutoGenDsp" SG_ 997 SH1_LED 1;
BA_ "GenSigAutoGenSnd" SG_ 997 SH1_LED 1;
BA_ "GenSigSendType" SG_ 997 SH1_LED 3;
BA_ "GenSigAutoGenDsp" SG_ 997 SH1_ZusatzHeizung 1;
BA_ "GenSigAutoGenSnd" SG_ 997 SH1_ZusatzHeizung 1;
BA_ "GenSigSendType" SG_ 997 SH1_ZusatzHeizung 3;
BA_ "GenSigAutoGenDsp" SG_ 997 SH1_ein_Wasserpumpe 1;
BA_ "GenSigAutoGenSnd" SG_ 997 SH1_ein_Wasserpumpe 1;
BA_ "GenSigSendType" SG_ 997 SH1_ein_Wasserpumpe 3;
BA_ "GenSigAutoGenDsp" SG_ 997 SH1_Fehlerstatus 1;
BA_ "GenSigAutoGenSnd" SG_ 997 SH1_Fehlerstatus 1;
BA_ "GenSigSendType" SG_ 997 SH1_Fehlerstatus 3;
BA_ "GenSigAutoGenDsp" SG_ 997 SH1_KD_Fehler 1;
BA_ "GenSigAutoGenSnd" SG_ 997 SH1_KD_Fehler 1;
BA_ "GenSigSendType" SG_ 997 SH1_KD_Fehler 3;
BA_ "Fehlerwert" SG_ 997 SH1_KD_Fehler 1;
BA_ "GenSigAutoGenDsp" SG_ 997 SH1_K_Verbrauch 1;
BA_ "GenSigAutoGenSnd" SG_ 997 SH1_K_Verbrauch 1;
BA_ "GenSigSendType" SG_ 997 SH1_K_Verbrauch 3;
BA_ "GenSigAutoGenDsp" SG_ 997 SH1_SH_Verbau 1;
BA_ "GenSigAutoGenSnd" SG_ 997 SH1_SH_Verbau 1;
BA_ "GenSigSendType" SG_ 997 SH1_SH_Verbau 3;
BA_ "GenSigAutoGenDsp" SG_ 997 SH1_K_Fehler 1;
BA_ "GenSigAutoGenSnd" SG_ 997 SH1_K_Fehler 1;
BA_ "GenSigSendType" SG_ 997 SH1_K_Fehler 3;
BA_ "GenSigAutoGenDsp" SG_ 997 SH1_Heizleistung 1;
BA_ "GenSigAutoGenSnd" SG_ 997 SH1_Heizleistung 1;
BA_ "GenSigSendType" SG_ 997 SH1_Heizleistung 3;
BA_ "GenSigAutoGenDsp" SG_ 997 SH1_HeizkreisTemp 1;
BA_ "GenSigAutoGenSnd" SG_ 997 SH1_HeizkreisTemp 1;
BA_ "GenSigSendType" SG_ 997 SH1_HeizkreisTemp 3;
BA_ "GenSigAutoGenDsp" SG_ 997 SH1_Pumpe_on 1;
BA_ "GenSigAutoGenSnd" SG_ 997 SH1_Pumpe_on 1;
BA_ "GenSigSendType" SG_ 997 SH1_Pumpe_on 3;
BA_ "GenSigAutoGenDsp" SG_ 997 SH1_KW_Warm 1;
BA_ "GenSigAutoGenSnd" SG_ 997 SH1_KW_Warm 1;
BA_ "GenSigSendType" SG_ 997 SH1_KW_Warm 3;
BA_ "GenSigAutoGenDsp" SG_ 997 SH1_Lueften 1;
BA_ "GenSigAutoGenSnd" SG_ 997 SH1_Lueften 1;
BA_ "GenSigSendType" SG_ 997 SH1_Lueften 3;
BA_ "GenSigAutoGenDsp" SG_ 1617 SY1_CAN_Extern 1;
BA_ "GenSigAutoGenSnd" SG_ 1617 SY1_CAN_Extern 1;
BA_ "GenSigSendType" SG_ 1617 SY1_CAN_Extern 0;
BA_ "GenSigAutoGenDsp" SG_ 1617 SY1_Diag_Antrieb 1;
BA_ "GenSigAutoGenSnd" SG_ 1617 SY1_Diag_Antrieb 1;
BA_ "GenSigSendType" SG_ 1617 SY1_Diag_Antrieb 0;
BA_ "GenSigAutoGenDsp" SG_ 1617 SY1_Sleep_Komfort 1;
BA_ "GenSigAutoGenSnd" SG_ 1617 SY1_Sleep_Komfort 1;
BA_ "GenSigSendType" SG_ 1617 SY1_Sleep_Komfort 0;
BA_ "GenSigAutoGenDsp" SG_ 1617 SY1_Diag_Komfort 1;
BA_ "GenSigAutoGenSnd" SG_ 1617 SY1_Diag_Komfort 1;
BA_ "GenSigSendType" SG_ 1617 SY1_Diag_Komfort 0;
BA_ "GenSigAutoGenDsp" SG_ 1617 SY1_Sleep_Infotainment 1;
BA_ "GenSigAutoGenSnd" SG_ 1617 SY1_Sleep_Infotainment 1;
BA_ "GenSigSendType" SG_ 1617 SY1_Sleep_Infotainment 0;
BA_ "GenSigAutoGenDsp" SG_ 1617 SY1_Diag_Infotainment 1;
BA_ "GenSigAutoGenSnd" SG_ 1617 SY1_Diag_Infotainment 1;
BA_ "GenSigSendType" SG_ 1617 SY1_Diag_Infotainment 0;
BA_ "GenSigAutoGenDsp" SG_ 1617 SY1_Infotainment 1;
BA_ "GenSigAutoGenSnd" SG_ 1617 SY1_Infotainment 1;
BA_ "GenSigSendType" SG_ 1617 SY1_Infotainment 0;
BA_ "GenSigFuncType" SG_ 1617 SY1_Infotainment 8;
BA_ "GenSigAutoGenDsp" SG_ 1617 SY1_Verbauliste_gueltig 1;
BA_ "GenSigAutoGenSnd" SG_ 1617 SY1_Verbauliste_gueltig 1;
BA_ "GenSigSendType" SG_ 1617 SY1_Verbauliste_gueltig 0;
BA_ "GenSigAutoGenDsp" SG_ 1617 SY1_Klasse 1;
BA_ "GenSigAutoGenSnd" SG_ 1617 SY1_Klasse 1;
BA_ "GenSigSendType" SG_ 1617 SY1_Klasse 0;
BA_ "GenSigAutoGenDsp" SG_ 1617 SY1_Marke 1;
BA_ "GenSigAutoGenSnd" SG_ 1617 SY1_Marke 1;
BA_ "GenSigSendType" SG_ 1617 SY1_Marke 0;
BA_ "GenSigAutoGenDsp" SG_ 1617 SY1_Derivat 1;
BA_ "GenSigAutoGenSnd" SG_ 1617 SY1_Derivat 1;
BA_ "GenSigSendType" SG_ 1617 SY1_Derivat 0;
BA_ "GenSigFuncType" SG_ 1617 SY1_Derivat 8;
BA_ "GenSigAutoGenDsp" SG_ 1617 SY1_Generation 1;
BA_ "GenSigAutoGenSnd" SG_ 1617 SY1_Generation 1;
BA_ "GenSigSendType" SG_ 1617 SY1_Generation 0;
BA_ "GenSigAutoGenDsp" SG_ 1617 SY1_Erweiterung 1;
BA_ "GenSigAutoGenSnd" SG_ 1617 SY1_Erweiterung 1;
BA_ "GenSigSendType" SG_ 1617 SY1_Erweiterung 0;
BA_ "GenSigStartValue" SG_ 1617 SY1_Erweiterung 15;
BA_ "GenSigAutoGenDsp" SG_ 1617 SY1_Rechtslenker 1;
BA_ "GenSigAutoGenSnd" SG_ 1617 SY1_Rechtslenker 1;
BA_ "GenSigSendType" SG_ 1617 SY1_Rechtslenker 0;
BA_ "GenSigAutoGenDsp" SG_ 1617 SY1_Viertuerer 1;
BA_ "GenSigAutoGenSnd" SG_ 1617 SY1_Viertuerer 1;
BA_ "GenSigSendType" SG_ 1617 SY1_Viertuerer 0;
BA_ "GenSigAutoGenDsp" SG_ 1617 SY1_Transportmode 1;
BA_ "GenSigAutoGenSnd" SG_ 1617 SY1_Transportmode 1;
BA_ "GenSigSendType" SG_ 1617 SY1_Transportmode 0;
BA_ "GenSigAutoGenDsp" SG_ 1617 SY1_KD_Fehler 1;
BA_ "GenSigAutoGenSnd" SG_ 1617 SY1_KD_Fehler 1;
BA_ "GenSigSendType" SG_ 1617 SY1_KD_Fehler 0;
BA_ "GenSigAutoGenDsp" SG_ 1617 SY1_VersLowCAN_Komfort 1;
BA_ "GenSigAutoGenSnd" SG_ 1617 SY1_VersLowCAN_Komfort 1;
BA_ "GenSigSendType" SG_ 1617 SY1_VersLowCAN_Komfort 0;
BA_ "GenSigStartValue" SG_ 1617 SY1_VersLowCAN_Komfort 6;
BA_ "GenSigAutoGenDsp" SG_ 1617 SY1_VersHighCAN_Komfort 1;
BA_ "GenSigAutoGenSnd" SG_ 1617 SY1_VersHighCAN_Komfort 1;
BA_ "GenSigSendType" SG_ 1617 SY1_VersHighCAN_Komfort 0;
BA_ "GenSigStartValue" SG_ 1617 SY1_VersHighCAN_Komfort 3;
BA_ "GenSigAutoGenDsp" SG_ 1617 SY1_VersLowCAN_Antrieb 1;
BA_ "GenSigAutoGenSnd" SG_ 1617 SY1_VersLowCAN_Antrieb 1;
BA_ "GenSigSendType" SG_ 1617 SY1_VersLowCAN_Antrieb 0;
BA_ "GenSigStartValue" SG_ 1617 SY1_VersLowCAN_Antrieb 5;
BA_ "GenSigAutoGenDsp" SG_ 1617 SY1_VersHighCAN_Antrieb 1;
BA_ "GenSigAutoGenSnd" SG_ 1617 SY1_VersHighCAN_Antrieb 1;
BA_ "GenSigSendType" SG_ 1617 SY1_VersHighCAN_Antrieb 0;
BA_ "GenSigStartValue" SG_ 1617 SY1_VersHighCAN_Antrieb 5;
BA_ "GenSigAutoGenDsp" SG_ 1617 SY1_Relais_FAS_Zweig 1;
BA_ "GenSigAutoGenSnd" SG_ 1617 SY1_Relais_FAS_Zweig 1;
BA_ "GenSigSendType" SG_ 1617 SY1_Relais_FAS_Zweig 3;
BA_ "GenSigAutoGenDsp" SG_ 1617 SY1_ELV_Lock_Supply 1;
BA_ "GenSigAutoGenSnd" SG_ 1617 SY1_ELV_Lock_Supply 1;
BA_ "GenSigSendType" SG_ 1617 SY1_ELV_Lock_Supply 3;
BA_ "GenSigAutoGenDsp" SG_ 1617 SY1_QRS_Messmodus 1;
BA_ "GenSigAutoGenSnd" SG_ 1617 SY1_QRS_Messmodus 1;
BA_ "GenSigSendType" SG_ 1617 SY1_QRS_Messmodus 3;
BA_ "GenSigAutoGenDsp" SG_ 1617 SY1_NWDF_gueltig 1;
BA_ "GenSigAutoGenSnd" SG_ 1617 SY1_NWDF_gueltig 1;
BA_ "GenSigSendType" SG_ 1617 SY1_NWDF_gueltig 0;
BA_ "GenSigStartValue" SG_ 1617 SY1_NWDF_gueltig 1;
BA_ "GenSigAutoGenDsp" SG_ 1617 SY1_NWDF 1;
BA_ "GenSigAutoGenSnd" SG_ 1617 SY1_NWDF 1;
BA_ "GenSigSendType" SG_ 1617 SY1_NWDF 3;
BA_ "GenSigAutoGenDsp" SG_ 1617 SY1_Notbrems_Status 1;
BA_ "GenSigAutoGenSnd" SG_ 1617 SY1_Notbrems_Status 1;
BA_ "GenSigSendType" SG_ 1617 SY1_Notbrems_Status 3;
BA_ "GenSigAutoGenDsp" SG_ 1477 TAS_TA_on 1;
BA_ "GenSigAutoGenSnd" SG_ 1477 TAS_TA_on 1;
BA_ "GenSigSendType" SG_ 1477 TAS_TA_on 3;
BA_ "GenSigAutoGenDsp" SG_ 1477 TAS_TA_Wake_Up_Komfort 1;
BA_ "GenSigAutoGenSnd" SG_ 1477 TAS_TA_Wake_Up_Komfort 1;
BA_ "GenSigSendType" SG_ 1477 TAS_TA_Wake_Up_Komfort 3;
BA_ "GenSigAutoGenDsp" SG_ 1477 TAS_TA_Error_flag 1;
BA_ "GenSigAutoGenSnd" SG_ 1477 TAS_TA_Error_flag 1;
BA_ "GenSigSendType" SG_ 1477 TAS_TA_Error_flag 3;
BA_ "GenSigAutoGenDsp" SG_ 1477 TAS_TA_Symbol 1;
BA_ "GenSigAutoGenSnd" SG_ 1477 TAS_TA_Symbol 1;
BA_ "GenSigSendType" SG_ 1477 TAS_TA_Symbol 3;
BA_ "GenSigAutoGenDsp" SG_ 1639 TF1_DSP_Zeichen_1 1;
BA_ "GenSigAutoGenSnd" SG_ 1639 TF1_DSP_Zeichen_1 1;
BA_ "GenSigSendType" SG_ 1639 TF1_DSP_Zeichen_1 3;
BA_ "GenSigAutoGenDsp" SG_ 1639 TF1_DSP_Zeichen_2 1;
BA_ "GenSigAutoGenSnd" SG_ 1639 TF1_DSP_Zeichen_2 1;
BA_ "GenSigSendType" SG_ 1639 TF1_DSP_Zeichen_2 3;
BA_ "GenSigAutoGenDsp" SG_ 1639 TF1_DSP_Zeichen_3 1;
BA_ "GenSigAutoGenSnd" SG_ 1639 TF1_DSP_Zeichen_3 1;
BA_ "GenSigSendType" SG_ 1639 TF1_DSP_Zeichen_3 3;
BA_ "GenSigAutoGenDsp" SG_ 1639 TF1_DSP_Zeichen_4 1;
BA_ "GenSigAutoGenSnd" SG_ 1639 TF1_DSP_Zeichen_4 1;
BA_ "GenSigSendType" SG_ 1639 TF1_DSP_Zeichen_4 3;
BA_ "GenSigAutoGenDsp" SG_ 1639 TF1_DSP_Zeichen_5 1;
BA_ "GenSigAutoGenSnd" SG_ 1639 TF1_DSP_Zeichen_5 1;
BA_ "GenSigSendType" SG_ 1639 TF1_DSP_Zeichen_5 3;
BA_ "GenSigAutoGenDsp" SG_ 1639 TF1_DSP_Zeichen_6 1;
BA_ "GenSigAutoGenSnd" SG_ 1639 TF1_DSP_Zeichen_6 1;
BA_ "GenSigSendType" SG_ 1639 TF1_DSP_Zeichen_6 3;
BA_ "GenSigAutoGenDsp" SG_ 1639 TF1_DSP_Zeichen_7 1;
BA_ "GenSigAutoGenSnd" SG_ 1639 TF1_DSP_Zeichen_7 1;
BA_ "GenSigSendType" SG_ 1639 TF1_DSP_Zeichen_7 3;
BA_ "GenSigAutoGenDsp" SG_ 1639 TF1_DSP_Zeichen_8 1;
BA_ "GenSigAutoGenSnd" SG_ 1639 TF1_DSP_Zeichen_8 1;
BA_ "GenSigSendType" SG_ 1639 TF1_DSP_Zeichen_8 3;
BA_ "GenSigAutoGenDsp" SG_ 1643 TF2_DSP_Zeichen_9 1;
BA_ "GenSigAutoGenSnd" SG_ 1643 TF2_DSP_Zeichen_9 1;
BA_ "GenSigSendType" SG_ 1643 TF2_DSP_Zeichen_9 3;
BA_ "GenSigAutoGenDsp" SG_ 1643 TF2_DSP_Zeichen_10 1;
BA_ "GenSigAutoGenSnd" SG_ 1643 TF2_DSP_Zeichen_10 1;
BA_ "GenSigSendType" SG_ 1643 TF2_DSP_Zeichen_10 3;
BA_ "GenSigAutoGenDsp" SG_ 1643 TF2_DSP_Zeichen_11 1;
BA_ "GenSigAutoGenSnd" SG_ 1643 TF2_DSP_Zeichen_11 1;
BA_ "GenSigSendType" SG_ 1643 TF2_DSP_Zeichen_11 3;
BA_ "GenSigAutoGenDsp" SG_ 1643 TF2_DSP_Zeichen_12 1;
BA_ "GenSigAutoGenSnd" SG_ 1643 TF2_DSP_Zeichen_12 1;
BA_ "GenSigSendType" SG_ 1643 TF2_DSP_Zeichen_12 3;
BA_ "GenSigAutoGenDsp" SG_ 1643 TF2_DSP_Zeichen_13 1;
BA_ "GenSigAutoGenSnd" SG_ 1643 TF2_DSP_Zeichen_13 1;
BA_ "GenSigSendType" SG_ 1643 TF2_DSP_Zeichen_13 3;
BA_ "GenSigAutoGenDsp" SG_ 1643 TF2_DSP_Zeichen_14 1;
BA_ "GenSigAutoGenSnd" SG_ 1643 TF2_DSP_Zeichen_14 1;
BA_ "GenSigSendType" SG_ 1643 TF2_DSP_Zeichen_14 3;
BA_ "GenSigAutoGenDsp" SG_ 1643 TF2_DSP_Zeichen_15 1;
BA_ "GenSigAutoGenSnd" SG_ 1643 TF2_DSP_Zeichen_15 1;
BA_ "GenSigSendType" SG_ 1643 TF2_DSP_Zeichen_15 3;
BA_ "GenSigAutoGenDsp" SG_ 1643 TF2_DSP_Zeichen_16 1;
BA_ "GenSigAutoGenSnd" SG_ 1643 TF2_DSP_Zeichen_16 1;
BA_ "GenSigSendType" SG_ 1643 TF2_DSP_Zeichen_16 3;
BA_ "GenSigSendType" SG_ 1637 TF3_BT_ConnectionState 3;
BA_ "GenSigAutoGenSnd" SG_ 1637 TF3_BT_ConnectionState 1;
BA_ "GenSigAutoGenDsp" SG_ 1637 TF3_BT_ConnectionState 1;
BA_ "GenSigAutoGenDsp" SG_ 1637 TF3_Phone_on 1;
BA_ "GenSigAutoGenSnd" SG_ 1637 TF3_Phone_on 1;
BA_ "GenSigSendType" SG_ 1637 TF3_Phone_on 3;
BA_ "GenSigAutoGenDsp" SG_ 1637 TF3_Show_Phone 1;
BA_ "GenSigAutoGenSnd" SG_ 1637 TF3_Show_Phone 1;
BA_ "GenSigSendType" SG_ 1637 TF3_Show_Phone 3;
BA_ "GenSigAutoGenDsp" SG_ 1637 TF3_Phone_mute 1;
BA_ "GenSigAutoGenSnd" SG_ 1637 TF3_Phone_mute 1;
BA_ "GenSigSendType" SG_ 1637 TF3_Phone_mute 3;
BA_ "GenSigAutoGenDsp" SG_ 1637 TF3_Phone_active_call 1;
BA_ "GenSigAutoGenSnd" SG_ 1637 TF3_Phone_active_call 1;
BA_ "GenSigSendType" SG_ 1637 TF3_Phone_active_call 3;
BA_ "GenSigAutoGenDsp" SG_ 1637 TF3_Phone_ring 1;
BA_ "GenSigAutoGenSnd" SG_ 1637 TF3_Phone_ring 1;
BA_ "GenSigSendType" SG_ 1637 TF3_Phone_ring 3;
BA_ "GenSigAutoGenDsp" SG_ 1637 TF3_Phone_sim_OK 1;
BA_ "GenSigAutoGenSnd" SG_ 1637 TF3_Phone_sim_OK 1;
BA_ "GenSigSendType" SG_ 1637 TF3_Phone_sim_OK 3;
BA_ "GenSigAutoGenDsp" SG_ 1637 TF3_Phone_pin_OK 1;
BA_ "GenSigAutoGenSnd" SG_ 1637 TF3_Phone_pin_OK 1;
BA_ "GenSigSendType" SG_ 1637 TF3_Phone_pin_OK 3;
BA_ "GenSigAutoGenDsp" SG_ 1637 TF3_Phone_Error_flag 1;
BA_ "GenSigAutoGenSnd" SG_ 1637 TF3_Phone_Error_flag 1;
BA_ "GenSigSendType" SG_ 1637 TF3_Phone_Error_flag 3;
BA_ "GenSigAutoGenDsp" SG_ 1637 TF3_Phone_Level 1;
BA_ "GenSigAutoGenSnd" SG_ 1637 TF3_Phone_Level 1;
BA_ "GenSigSendType" SG_ 1637 TF3_Phone_Level 3;
BA_ "GenSigAutoGenDsp" SG_ 1637 TF3_Phone_Display_Vol 1;
BA_ "GenSigAutoGenSnd" SG_ 1637 TF3_Phone_Display_Vol 1;
BA_ "GenSigSendType" SG_ 1637 TF3_Phone_Display_Vol 3;
BA_ "GenSigAutoGenDsp" SG_ 1637 TF3_Phone_Init 1;
BA_ "GenSigAutoGenSnd" SG_ 1637 TF3_Phone_Init 1;
BA_ "GenSigSendType" SG_ 1637 TF3_Phone_Init 3;
BA_ "GenSigAutoGenDsp" SG_ 1637 TF3_Mute_Msg_Code 1;
BA_ "GenSigAutoGenSnd" SG_ 1637 TF3_Mute_Msg_Code 1;
BA_ "GenSigSendType" SG_ 1637 TF3_Mute_Msg_Code 3;
BA_ "GenSigAutoGenDsp" SG_ 1637 TF3_Wake_Up_Komfort 1;
BA_ "GenSigAutoGenSnd" SG_ 1637 TF3_Wake_Up_Komfort 1;
BA_ "GenSigSendType" SG_ 1637 TF3_Wake_Up_Komfort 3;
BA_ "GenSigAutoGenDsp" SG_ 1637 TF3_Radio_Access 1;
BA_ "GenSigAutoGenSnd" SG_ 1637 TF3_Radio_Access 1;
BA_ "GenSigSendType" SG_ 1637 TF3_Radio_Access 3;
BA_ "GenSigAutoGenDsp" SG_ 1637 TF3_Provider 1;
BA_ "GenSigAutoGenSnd" SG_ 1637 TF3_Provider 1;
BA_ "GenSigSendType" SG_ 1637 TF3_Provider 3;
BA_ "GenSigAutoGenDsp" SG_ 1637 TF3_Feldstaerke 1;
BA_ "GenSigAutoGenSnd" SG_ 1637 TF3_Feldstaerke 1;
BA_ "GenSigSendType" SG_ 1637 TF3_Feldstaerke 3;
BA_ "GenSigAutoGenDsp" SG_ 1637 TF3_Laendercode 1;
BA_ "GenSigAutoGenSnd" SG_ 1637 TF3_Laendercode 1;
BA_ "GenSigSendType" SG_ 1637 TF3_Laendercode 3;
BA_ "GenSigAutoGenDsp" SG_ 1637 TF3_Feldstaerke_Fehler 1;
BA_ "GenSigAutoGenSnd" SG_ 1637 TF3_Feldstaerke_Fehler 1;
BA_ "GenSigSendType" SG_ 1637 TF3_Feldstaerke_Fehler 3;
BA_ "GenSigAutoGenDsp" SG_ 1637 TF3_Registrierungsstatus 1;
BA_ "GenSigAutoGenSnd" SG_ 1637 TF3_Registrierungsstatus 1;
BA_ "GenSigSendType" SG_ 1637 TF3_Registrierungsstatus 3;
BA_ "GenSigAutoGenDsp" SG_ 1447 TM1_TM_on 1;
BA_ "GenSigAutoGenSnd" SG_ 1447 TM1_TM_on 1;
BA_ "GenSigSendType" SG_ 1447 TM1_TM_on 3;
BA_ "GenSigAutoGenDsp" SG_ 1447 TM1_TM_mute 1;
BA_ "GenSigAutoGenSnd" SG_ 1447 TM1_TM_mute 1;
BA_ "GenSigSendType" SG_ 1447 TM1_TM_mute 3;
BA_ "GenSigAutoGenDsp" SG_ 1447 TM1_TM_Wake_Up_Komfort 1;
BA_ "GenSigAutoGenSnd" SG_ 1447 TM1_TM_Wake_Up_Komfort 1;
BA_ "GenSigSendType" SG_ 1447 TM1_TM_Wake_Up_Komfort 3;
BA_ "GenSigAutoGenDsp" SG_ 1447 TM1_TM_Error_flag 1;
BA_ "GenSigAutoGenSnd" SG_ 1447 TM1_TM_Error_flag 1;
BA_ "GenSigSendType" SG_ 1447 TM1_TM_Error_flag 3;
BA_ "GenSigAutoGenDsp" SG_ 1449 TM2_Warnblink 1;
BA_ "GenSigAutoGenSnd" SG_ 1449 TM2_Warnblink 1;
BA_ "GenSigSendType" SG_ 1449 TM2_Warnblink 0;
BA_ "GenSigAutoGenDsp" SG_ 1449 TM2_Signalhorn 1;
BA_ "GenSigAutoGenSnd" SG_ 1449 TM2_Signalhorn 1;
BA_ "GenSigSendType" SG_ 1449 TM2_Signalhorn 0;
BA_ "GenSigAutoGenDsp" SG_ 1449 TM2_Lock 1;
BA_ "GenSigAutoGenSnd" SG_ 1449 TM2_Lock 1;
BA_ "GenSigSendType" SG_ 1449 TM2_Lock 0;
BA_ "GenSigAutoGenDsp" SG_ 1449 TM2_Unlock 1;
BA_ "GenSigAutoGenSnd" SG_ 1449 TM2_Unlock 1;
BA_ "GenSigSendType" SG_ 1449 TM2_Unlock 0;
BA_ "GenSigAutoGenDsp" SG_ 1745 TP_DAB_Radio 1;
BA_ "GenSigAutoGenSnd" SG_ 1745 TP_DAB_Radio 1;
BA_ "GenSigSendType" SG_ 1745 TP_DAB_Radio 3;
BA_ "GenSigAutoGenDsp" SG_ 1244 TPDyn_DAB_1 1;
BA_ "GenSigAutoGenSnd" SG_ 1244 TPDyn_DAB_1 1;
BA_ "GenSigSendType" SG_ 1244 TPDyn_DAB_1 3;
BA_ "GenSigAutoGenDsp" SG_ 1245 mTPDyn_DAB_2 1;
BA_ "GenSigAutoGenSnd" SG_ 1245 mTPDyn_DAB_2 1;
BA_ "GenSigSendType" SG_ 1245 mTPDyn_DAB_2 3;
BA_ "GenSigAutoGenDsp" SG_ 768 TPDyn_Diag_1_1 1;
BA_ "GenSigAutoGenSnd" SG_ 768 TPDyn_Diag_1_1 1;
BA_ "GenSigSendType" SG_ 768 TPDyn_Diag_1_1 3;
BA_ "GenSigAutoGenDsp" SG_ 769 TPDyn_Diag_1_2 1;
BA_ "GenSigAutoGenSnd" SG_ 769 TPDyn_Diag_1_2 1;
BA_ "GenSigSendType" SG_ 769 TPDyn_Diag_1_2 3;
BA_ "GenSigAutoGenDsp" SG_ 770 TPDyn_Diag_1_3 1;
BA_ "GenSigAutoGenSnd" SG_ 770 TPDyn_Diag_1_3 1;
BA_ "GenSigSendType" SG_ 770 TPDyn_Diag_1_3 3;
BA_ "GenSigAutoGenDsp" SG_ 771 TPDyn_Diag_1_4 1;
BA_ "GenSigAutoGenSnd" SG_ 771 TPDyn_Diag_1_4 1;
BA_ "GenSigSendType" SG_ 771 TPDyn_Diag_1_4 3;
BA_ "GenSigAutoGenDsp" SG_ 772 TPDyn_Diag_1_5 1;
BA_ "GenSigAutoGenSnd" SG_ 772 TPDyn_Diag_1_5 1;
BA_ "GenSigSendType" SG_ 772 TPDyn_Diag_1_5 3;
BA_ "GenSigAutoGenDsp" SG_ 773 TPDyn_Diag_1_6 1;
BA_ "GenSigAutoGenSnd" SG_ 773 TPDyn_Diag_1_6 1;
BA_ "GenSigSendType" SG_ 773 TPDyn_Diag_1_6 3;
BA_ "GenSigAutoGenDsp" SG_ 774 TPDyn_Diag_1_7 1;
BA_ "GenSigAutoGenSnd" SG_ 774 TPDyn_Diag_1_7 1;
BA_ "GenSigSendType" SG_ 774 TPDyn_Diag_1_7 3;
BA_ "GenSigAutoGenDsp" SG_ 775 TPDyn_Diag_1_8 1;
BA_ "GenSigAutoGenSnd" SG_ 775 TPDyn_Diag_1_8 1;
BA_ "GenSigSendType" SG_ 775 TPDyn_Diag_1_8 3;
BA_ "GenSigAutoGenDsp" SG_ 1246 TPDyn_DSP_1 1;
BA_ "GenSigAutoGenSnd" SG_ 1246 TPDyn_DSP_1 1;
BA_ "GenSigSendType" SG_ 1246 TPDyn_DSP_1 3;
BA_ "GenSigAutoGenDsp" SG_ 1247 TPDyn_DSP_2 1;
BA_ "GenSigAutoGenSnd" SG_ 1247 TPDyn_DSP_2 1;
BA_ "GenSigSendType" SG_ 1247 TPDyn_DSP_2 3;
BA_ "GenSigAutoGenDsp" SG_ 1232 TPDyn_Grafik_1 1;
BA_ "GenSigAutoGenSnd" SG_ 1232 TPDyn_Grafik_1 1;
BA_ "GenSigSendType" SG_ 1232 TPDyn_Grafik_1 3;
BA_ "GenSigAutoGenDsp" SG_ 1233 TPDyn_Grafik_2 1;
BA_ "GenSigAutoGenSnd" SG_ 1233 TPDyn_Grafik_2 1;
BA_ "GenSigSendType" SG_ 1233 TPDyn_Grafik_2 3;
BA_ "GenSigAutoGenDsp" SG_ 1234 TPDyn_Grafik_3 1;
BA_ "GenSigAutoGenSnd" SG_ 1234 TPDyn_Grafik_3 1;
BA_ "GenSigSendType" SG_ 1234 TPDyn_Grafik_3 3;
BA_ "GenSigAutoGenDsp" SG_ 1235 TPDyn_Grafik_4 1;
BA_ "GenSigAutoGenSnd" SG_ 1235 TPDyn_Grafik_4 1;
BA_ "GenSigSendType" SG_ 1235 TPDyn_Grafik_4 3;
BA_ "GenSigAutoGenDsp" SG_ 1279 TPDyn_GSM_1 1;
BA_ "GenSigAutoGenSnd" SG_ 1279 TPDyn_GSM_1 1;
BA_ "GenSigSendType" SG_ 1279 TPDyn_GSM_1 3;
BA_ "GenSigAutoGenDsp" SG_ 720 TPDyn_Info_1 1;
BA_ "GenSigAutoGenSnd" SG_ 720 TPDyn_Info_1 1;
BA_ "GenSigSendType" SG_ 720 TPDyn_Info_1 3;
BA_ "GenSigAutoGenDsp" SG_ 721 TPDyn_Info_2 1;
BA_ "GenSigAutoGenSnd" SG_ 721 TPDyn_Info_2 1;
BA_ "GenSigSendType" SG_ 721 TPDyn_Info_2 3;
BA_ "GenSigAutoGenDsp" SG_ 1250 TPDyn_Kompass_1 1;
BA_ "GenSigAutoGenSnd" SG_ 1250 TPDyn_Kompass_1 1;
BA_ "GenSigSendType" SG_ 1250 TPDyn_Kompass_1 3;
BA_ "GenSigAutoGenDsp" SG_ 1251 TPDyn_Kompass_2 1;
BA_ "GenSigAutoGenSnd" SG_ 1251 TPDyn_Kompass_2 1;
BA_ "GenSigSendType" SG_ 1251 TPDyn_Kompass_2 3;
BA_ "GenSigAutoGenDsp" SG_ 1260 TPDyn_MDI_1 1;
BA_ "GenSigAutoGenSnd" SG_ 1260 TPDyn_MDI_1 1;
BA_ "GenSigSendType" SG_ 1260 TPDyn_MDI_1 3;
BA_ "GenSigAutoGenDsp" SG_ 1240 TPDyn_Navi_1 1;
BA_ "GenSigAutoGenSnd" SG_ 1240 TPDyn_Navi_1 1;
BA_ "GenSigSendType" SG_ 1240 TPDyn_Navi_1 3;
BA_ "GenSigAutoGenDsp" SG_ 1241 TPDyn_Navi_2 1;
BA_ "GenSigAutoGenSnd" SG_ 1241 TPDyn_Navi_2 1;
BA_ "GenSigSendType" SG_ 1241 TPDyn_Navi_2 3;
BA_ "GenSigAutoGenDsp" SG_ 1242 TPDyn_Radio_1 1;
BA_ "GenSigAutoGenSnd" SG_ 1242 TPDyn_Radio_1 1;
BA_ "GenSigSendType" SG_ 1242 TPDyn_Radio_1 3;
BA_ "GenSigAutoGenDsp" SG_ 1243 TPDyn_Radio_2 1;
BA_ "GenSigAutoGenSnd" SG_ 1243 TPDyn_Radio_2 1;
BA_ "GenSigSendType" SG_ 1243 TPDyn_Radio_2 3;
BA_ "GenSigAutoGenDsp" SG_ 1276 TPDyn_Rearview_1 1;
BA_ "GenSigAutoGenSnd" SG_ 1276 TPDyn_Rearview_1 1;
BA_ "GenSigSendType" SG_ 1276 TPDyn_Rearview_1 3;
BA_ "GenSigAutoGenDsp" SG_ 1277 TPDyn_Rearview_2 1;
BA_ "GenSigAutoGenSnd" SG_ 1277 TPDyn_Rearview_2 1;
BA_ "GenSigSendType" SG_ 1277 TPDyn_Rearview_2 3;
BA_ "GenSigAutoGenDsp" SG_ 1248 TPDyn_SBS_1 1;
BA_ "GenSigAutoGenSnd" SG_ 1248 TPDyn_SBS_1 1;
BA_ "GenSigSendType" SG_ 1248 TPDyn_SBS_1 3;
BA_ "GenSigAutoGenDsp" SG_ 1249 TPDyn_SBS_2 1;
BA_ "GenSigAutoGenSnd" SG_ 1249 TPDyn_SBS_2 1;
BA_ "GenSigSendType" SG_ 1249 TPDyn_SBS_2 3;
BA_ "GenSigAutoGenDsp" SG_ 804 TPDyn_SH_1 1;
BA_ "GenSigAutoGenSnd" SG_ 804 TPDyn_SH_1 1;
BA_ "GenSigSendType" SG_ 804 TPDyn_SH_1 3;
BA_ "GenSigAutoGenDsp" SG_ 805 TPDyn_SH_2 1;
BA_ "GenSigAutoGenSnd" SG_ 805 TPDyn_SH_2 1;
BA_ "GenSigSendType" SG_ 805 TPDyn_SH_2 3;
BA_ "GenSigAutoGenDsp" SG_ 1270 TPDyn_Tastatur_1 1;
BA_ "GenSigAutoGenSnd" SG_ 1270 TPDyn_Tastatur_1 1;
BA_ "GenSigSendType" SG_ 1270 TPDyn_Tastatur_1 3;
BA_ "GenSigAutoGenDsp" SG_ 1271 TPDyn_Tastatur_2 1;
BA_ "GenSigAutoGenSnd" SG_ 1271 TPDyn_Tastatur_2 1;
BA_ "GenSigSendType" SG_ 1271 TPDyn_Tastatur_2 3;
BA_ "GenSigAutoGenDsp" SG_ 1264 TPDyn_Telefon_1 1;
BA_ "GenSigAutoGenSnd" SG_ 1264 TPDyn_Telefon_1 1;
BA_ "GenSigSendType" SG_ 1264 TPDyn_Telefon_1 3;
BA_ "GenSigAutoGenDsp" SG_ 1265 TPDyn_Telefon_2 1;
BA_ "GenSigAutoGenSnd" SG_ 1265 TPDyn_Telefon_2 1;
BA_ "GenSigSendType" SG_ 1265 TPDyn_Telefon_2 3;
BA_ "GenSigAutoGenDsp" SG_ 1268 TPDyn_Telematik_1 1;
BA_ "GenSigAutoGenSnd" SG_ 1268 TPDyn_Telematik_1 1;
BA_ "GenSigSendType" SG_ 1268 TPDyn_Telematik_1 3;
BA_ "GenSigAutoGenDsp" SG_ 1269 TPDyn_Telematik_2 1;
BA_ "GenSigAutoGenSnd" SG_ 1269 TPDyn_Telematik_2 1;
BA_ "GenSigSendType" SG_ 1269 TPDyn_Telematik_2 3;
BA_ "GenSigAutoGenDsp" SG_ 1272 TPDyn_TV_1 1;
BA_ "GenSigAutoGenSnd" SG_ 1272 TPDyn_TV_1 1;
BA_ "GenSigSendType" SG_ 1272 TPDyn_TV_1 3;
BA_ "GenSigAutoGenDsp" SG_ 1273 TPDyn_TV_2 1;
BA_ "GenSigAutoGenSnd" SG_ 1273 TPDyn_TV_2 1;
BA_ "GenSigSendType" SG_ 1273 TPDyn_TV_2 3;
BA_ "GenSigAutoGenDsp" SG_ 591 DAB_TP_Er 1;
BA_ "GenSigAutoGenSnd" SG_ 591 DAB_TP_Er 1;
BA_ "GenSigSendType" SG_ 591 DAB_TP_Er 3;
BA_ "GenSigAutoGenDsp" SG_ 595 DSP_TP_Er 1;
BA_ "GenSigAutoGenSnd" SG_ 595 DSP_TP_Er 1;
BA_ "GenSigSendType" SG_ 595 DSP_TP_Er 3;
BA_ "GenSigAutoGenDsp" SG_ 584 Grafik_TP_Er 1;
BA_ "GenSigAutoGenSnd" SG_ 584 Grafik_TP_Er 1;
BA_ "GenSigSendType" SG_ 584 Grafik_TP_Er 3;
BA_ "GenSigAutoGenDsp" SG_ 577 GSM_TP_Er 1;
BA_ "GenSigAutoGenSnd" SG_ 577 GSM_TP_Er 1;
BA_ "GenSigSendType" SG_ 577 GSM_TP_Er 3;
BA_ "GenSigAutoGenDsp" SG_ 589 Informationselektronik1_TP_Er 1;
BA_ "GenSigAutoGenSnd" SG_ 589 Informationselektronik1_TP_Er 1;
BA_ "GenSigSendType" SG_ 589 Informationselektronik1_TP_Er 3;
BA_ "GenSigAutoGenDsp" SG_ 576 Kompass_TP_Er 1;
BA_ "GenSigAutoGenSnd" SG_ 576 Kompass_TP_Er 1;
BA_ "GenSigSendType" SG_ 576 Kompass_TP_Er 3;
BA_ "GenSigAutoGenDsp" SG_ 596 MDI_TP_Er 1;
BA_ "GenSigAutoGenSnd" SG_ 596 MDI_TP_Er 1;
BA_ "GenSigSendType" SG_ 596 MDI_TP_Er 3;
BA_ "GenSigAutoGenDsp" SG_ 603 Navi_TP_Er 1;
BA_ "GenSigAutoGenSnd" SG_ 603 Navi_TP_Er 1;
BA_ "GenSigSendType" SG_ 603 Navi_TP_Er 3;
BA_ "GenSigAutoGenDsp" SG_ 594 Radio_TP_Er 1;
BA_ "GenSigAutoGenSnd" SG_ 594 Radio_TP_Er 1;
BA_ "GenSigSendType" SG_ 594 Radio_TP_Er 3;
BA_ "GenSigAutoGenDsp" SG_ 585 Rearview_TP_Er 1;
BA_ "GenSigAutoGenSnd" SG_ 585 Rearview_TP_Er 1;
BA_ "GenSigSendType" SG_ 585 Rearview_TP_Er 3;
BA_ "GenSigAutoGenDsp" SG_ 604 SBS_TP_Er 1;
BA_ "GenSigAutoGenSnd" SG_ 604 SBS_TP_Er 1;
BA_ "GenSigSendType" SG_ 604 SBS_TP_Er 3;
BA_ "GenSigAutoGenDsp" SG_ 559 SH_TP_Er 1;
BA_ "GenSigAutoGenSnd" SG_ 559 SH_TP_Er 1;
BA_ "GenSigSendType" SG_ 559 SH_TP_Er 3;
BA_ "GenSigAutoGenDsp" SG_ 587 Tastatur_TP_Er 1;
BA_ "GenSigAutoGenSnd" SG_ 587 Tastatur_TP_Er 1;
BA_ "GenSigSendType" SG_ 587 Tastatur_TP_Er 3;
BA_ "GenSigAutoGenDsp" SG_ 602 Telefon_TP_Er 1;
BA_ "GenSigAutoGenSnd" SG_ 602 Telefon_TP_Er 1;
BA_ "GenSigSendType" SG_ 602 Telefon_TP_Er 3;
BA_ "GenSigAutoGenDsp" SG_ 597 TM_TP_Er_Telematik 1;
BA_ "GenSigAutoGenSnd" SG_ 597 TM_TP_Er_Telematik 1;
BA_ "GenSigSendType" SG_ 597 TM_TP_Er_Telematik 3;
BA_ "GenSigAutoGenDsp" SG_ 512 Tester_TP_Er 1;
BA_ "GenSigAutoGenSnd" SG_ 512 Tester_TP_Er 1;
BA_ "GenSigSendType" SG_ 512 Tester_TP_Er 3;
BA_ "GenSigAutoGenDsp" SG_ 599 TV_A_TP_Er 1;
BA_ "GenSigAutoGenSnd" SG_ 599 TV_A_TP_Er 1;
BA_ "GenSigSendType" SG_ 599 TV_A_TP_Er 3;
BA_ "GenSigAutoGenDsp" SG_ 1729 DISP_KOM_NSL 1;
BA_ "GenSigAutoGenSnd" SG_ 1729 DISP_KOM_NSL 1;
BA_ "GenSigSendType" SG_ 1729 DISP_KOM_NSL 3;
BA_ "GenSigAutoGenDsp" SG_ 1731 DISP_KOM_TM 1;
BA_ "GenSigAutoGenSnd" SG_ 1731 DISP_KOM_TM 1;
BA_ "GenSigSendType" SG_ 1731 DISP_KOM_TM 3;
BA_ "GenSigAutoGenDsp" SG_ 1728 DISP_NSL_KOM 1;
BA_ "GenSigAutoGenSnd" SG_ 1728 DISP_NSL_KOM 1;
BA_ "GenSigSendType" SG_ 1728 DISP_NSL_KOM 3;
BA_ "GenSigAutoGenDsp" SG_ 1744 TPRadio_DAB 1;
BA_ "GenSigAutoGenSnd" SG_ 1744 TPRadio_DAB 1;
BA_ "GenSigSendType" SG_ 1744 TPRadio_DAB 3;
BA_ "GenSigAutoGenDsp" SG_ 1673 TPStat_Grafik_Kompass 1;
BA_ "GenSigAutoGenSnd" SG_ 1673 TPStat_Grafik_Kompass 1;
BA_ "GenSigSendType" SG_ 1673 TPStat_Grafik_Kompass 3;
BA_ "GenSigAutoGenDsp" SG_ 1665 TPStat_Grafik_Radio 1;
BA_ "GenSigAutoGenSnd" SG_ 1665 TPStat_Grafik_Radio 1;
BA_ "GenSigSendType" SG_ 1665 TPStat_Grafik_Radio 3;
BA_ "GenSigAutoGenDsp" SG_ 1667 TPStat_Grafik_RNS 1;
BA_ "GenSigAutoGenSnd" SG_ 1667 TPStat_Grafik_RNS 1;
BA_ "GenSigSendType" SG_ 1667 TPStat_Grafik_RNS 3;
BA_ "GenSigAutoGenDsp" SG_ 1669 TPStat_Grafik_Telefon 1;
BA_ "GenSigAutoGenSnd" SG_ 1669 TPStat_Grafik_Telefon 1;
BA_ "GenSigSendType" SG_ 1669 TPStat_Grafik_Telefon 3;
BA_ "GenSigAutoGenDsp" SG_ 1671 TPStat_Grafik_Telematik 1;
BA_ "GenSigAutoGenSnd" SG_ 1671 TPStat_Grafik_Telematik 1;
BA_ "GenSigSendType" SG_ 1671 TPStat_Grafik_Telematik 3;
BA_ "GenSigAutoGenDsp" SG_ 1672 TPStat_Kompass_Grafik 1;
BA_ "GenSigAutoGenSnd" SG_ 1672 TPStat_Kompass_Grafik 1;
BA_ "GenSigSendType" SG_ 1672 TPStat_Kompass_Grafik 3;
BA_ "GenSigAutoGenDsp" SG_ 1664 TPStat_Radio_Grafik 1;
BA_ "GenSigAutoGenSnd" SG_ 1664 TPStat_Radio_Grafik 1;
BA_ "GenSigSendType" SG_ 1664 TPStat_Radio_Grafik 3;
BA_ "GenSigAutoGenDsp" SG_ 1666 TPStat_RNS_Grafik 1;
BA_ "GenSigAutoGenSnd" SG_ 1666 TPStat_RNS_Grafik 1;
BA_ "GenSigSendType" SG_ 1666 TPStat_RNS_Grafik 3;
BA_ "GenSigAutoGenDsp" SG_ 1668 TPStat_Telefon_Grafik 1;
BA_ "GenSigAutoGenSnd" SG_ 1668 TPStat_Telefon_Grafik 1;
BA_ "GenSigSendType" SG_ 1668 TPStat_Telefon_Grafik 3;
BA_ "GenSigAutoGenDsp" SG_ 1670 TPStat_Telematik_Grafik 1;
BA_ "GenSigAutoGenSnd" SG_ 1670 TPStat_Telematik_Grafik 1;
BA_ "GenSigSendType" SG_ 1670 TPStat_Telematik_Grafik 3;
BA_ "GenSigAutoGenDsp" SG_ 1730 DISP_TM_KOM 1;
BA_ "GenSigAutoGenSnd" SG_ 1730 DISP_TM_KOM 1;
BA_ "GenSigSendType" SG_ 1730 DISP_TM_KOM 3;
BA_ "GenSigAutoGenDsp" SG_ 1538 TV1_TVA_On 1;
BA_ "GenSigAutoGenSnd" SG_ 1538 TV1_TVA_On 1;
BA_ "GenSigSendType" SG_ 1538 TV1_TVA_On 3;
BA_ "GenSigAutoGenDsp" SG_ 1538 TV1_TVA_mute 1;
BA_ "GenSigAutoGenSnd" SG_ 1538 TV1_TVA_mute 1;
BA_ "GenSigSendType" SG_ 1538 TV1_TVA_mute 3;
BA_ "GenSigAutoGenDsp" SG_ 1538 TV1_TVA_Ueberhitzung 1;
BA_ "GenSigAutoGenSnd" SG_ 1538 TV1_TVA_Ueberhitzung 1;
BA_ "GenSigSendType" SG_ 1538 TV1_TVA_Ueberhitzung 3;
BA_ "GenSigAutoGenDsp" SG_ 1538 TV1_TVA_50Hz 1;
BA_ "GenSigAutoGenSnd" SG_ 1538 TV1_TVA_50Hz 1;
BA_ "GenSigSendType" SG_ 1538 TV1_TVA_50Hz 3;
BA_ "GenSigAutoGenDsp" SG_ 1538 TV1_TVA_Error 1;
BA_ "GenSigAutoGenSnd" SG_ 1538 TV1_TVA_Error 1;
BA_ "GenSigSendType" SG_ 1538 TV1_TVA_Error 3;
BA_ "GenSigAutoGenDsp" SG_ 1538 TV1_TVA_Error_flag 1;
BA_ "GenSigAutoGenSnd" SG_ 1538 TV1_TVA_Error_flag 1;
BA_ "GenSigSendType" SG_ 1538 TV1_TVA_Error_flag 3;
BA_ "GenSigAutoGenDsp" SG_ 1538 TV1_TVA_Mode 1;
BA_ "GenSigAutoGenSnd" SG_ 1538 TV1_TVA_Mode 1;
BA_ "GenSigSendType" SG_ 1538 TV1_TVA_Mode 3;
BA_ "GenSigAutoGenDsp" SG_ 1538 TV1_TVA_Para1 1;
BA_ "GenSigAutoGenSnd" SG_ 1538 TV1_TVA_Para1 1;
BA_ "GenSigSendType" SG_ 1538 TV1_TVA_Para1 3;
BA_ "GenSigAutoGenDsp" SG_ 1538 TV1_TVA_Para2 1;
BA_ "GenSigAutoGenSnd" SG_ 1538 TV1_TVA_Para2 1;
BA_ "GenSigSendType" SG_ 1538 TV1_TVA_Para2 3;
BA_ "GenSigAutoGenDsp" SG_ 1538 TV1_TVA_Para3 1;
BA_ "GenSigAutoGenSnd" SG_ 1538 TV1_TVA_Para3 1;
BA_ "GenSigSendType" SG_ 1538 TV1_TVA_Para3 3;
BA_ "GenSigAutoGenDsp" SG_ 1538 TV1_TVA_Para4 1;
BA_ "GenSigAutoGenSnd" SG_ 1538 TV1_TVA_Para4 1;
BA_ "GenSigSendType" SG_ 1538 TV1_TVA_Para4 3;
BA_ "GenSigAutoGenDsp" SG_ 1538 TV1_TVA_Para5 1;
BA_ "GenSigAutoGenSnd" SG_ 1538 TV1_TVA_Para5 1;
BA_ "GenSigSendType" SG_ 1538 TV1_TVA_Para5 3;
BA_ "GenSigAutoGenDsp" SG_ 1538 TV1_TVA_Para6 1;
BA_ "GenSigAutoGenSnd" SG_ 1538 TV1_TVA_Para6 1;
BA_ "GenSigSendType" SG_ 1538 TV1_TVA_Para6 3;
BA_ "GenSigAutoGenDsp" SG_ 1497 VS1_FH_FT_hoch 1;
BA_ "GenSigAutoGenSnd" SG_ 1497 VS1_FH_FT_hoch 1;
BA_ "GenSigSendType" SG_ 1497 VS1_FH_FT_hoch 3;
BA_ "GenSigAutoGenDsp" SG_ 1497 VS1_FH_FT_tief 1;
BA_ "GenSigAutoGenSnd" SG_ 1497 VS1_FH_FT_tief 1;
BA_ "GenSigSendType" SG_ 1497 VS1_FH_FT_tief 3;
BA_ "GenSigAutoGenDsp" SG_ 1497 VS1_FH_BT_hoch 1;
BA_ "GenSigAutoGenSnd" SG_ 1497 VS1_FH_BT_hoch 1;
BA_ "GenSigSendType" SG_ 1497 VS1_FH_BT_hoch 3;
BA_ "GenSigAutoGenDsp" SG_ 1497 VS1_FH_BT_tief 1;
BA_ "GenSigAutoGenSnd" SG_ 1497 VS1_FH_BT_tief 1;
BA_ "GenSigSendType" SG_ 1497 VS1_FH_BT_tief 3;
BA_ "GenSigAutoGenDsp" SG_ 1497 VS1_FH_HL_hoch 1;
BA_ "GenSigAutoGenSnd" SG_ 1497 VS1_FH_HL_hoch 1;
BA_ "GenSigSendType" SG_ 1497 VS1_FH_HL_hoch 3;
BA_ "GenSigAutoGenDsp" SG_ 1497 VS1_FH_HL_tief 1;
BA_ "GenSigAutoGenSnd" SG_ 1497 VS1_FH_HL_tief 1;
BA_ "GenSigSendType" SG_ 1497 VS1_FH_HL_tief 3;
BA_ "GenSigAutoGenDsp" SG_ 1497 VS1_FH_HR_hoch 1;
BA_ "GenSigAutoGenSnd" SG_ 1497 VS1_FH_HR_hoch 1;
BA_ "GenSigSendType" SG_ 1497 VS1_FH_HR_hoch 3;
BA_ "GenSigAutoGenDsp" SG_ 1497 VS1_FH_HR_tief 1;
BA_ "GenSigAutoGenSnd" SG_ 1497 VS1_FH_HR_tief 1;
BA_ "GenSigSendType" SG_ 1497 VS1_FH_HR_tief 3;
BA_ "GenSigAutoGenDsp" SG_ 1497 VS1_Freigabe_FH 1;
BA_ "GenSigAutoGenSnd" SG_ 1497 VS1_Freigabe_FH 1;
BA_ "GenSigSendType" SG_ 1497 VS1_Freigabe_FH 3;
BA_ "GenSigAutoGenDsp" SG_ 1497 VS1_ZV_auf 1;
BA_ "GenSigAutoGenSnd" SG_ 1497 VS1_ZV_auf 1;
BA_ "GenSigSendType" SG_ 1497 VS1_ZV_auf 3;
BA_ "GenSigAutoGenDsp" SG_ 1497 VS1_ZV_zu 1;
BA_ "GenSigAutoGenSnd" SG_ 1497 VS1_ZV_zu 1;
BA_ "GenSigSendType" SG_ 1497 VS1_ZV_zu 3;
BA_ "GenSigAutoGenDsp" SG_ 1497 VS1_Heckschloss_auf 1;
BA_ "GenSigAutoGenSnd" SG_ 1497 VS1_Heckschloss_auf 1;
BA_ "GenSigSendType" SG_ 1497 VS1_Heckschloss_auf 3;
BA_ "GenSigAutoGenDsp" SG_ 1497 VS1_auf_Verriegelung 1;
BA_ "GenSigAutoGenSnd" SG_ 1497 VS1_auf_Verriegelung 1;
BA_ "GenSigSendType" SG_ 1497 VS1_auf_Verriegelung 3;
BA_ "GenSigAutoGenDsp" SG_ 1497 VS1_zu_Verriegelung 1;
BA_ "GenSigAutoGenSnd" SG_ 1497 VS1_zu_Verriegelung 1;
BA_ "GenSigSendType" SG_ 1497 VS1_zu_Verriegelung 3;
BA_ "GenSigAutoGenDsp" SG_ 1497 VS1_Sperren 1;
BA_ "GenSigAutoGenSnd" SG_ 1497 VS1_Sperren 1;
BA_ "GenSigSendType" SG_ 1497 VS1_Sperren 3;
BA_ "GenSigAutoGenDsp" SG_ 1497 VS1_zent_FH_Schalter 1;
BA_ "GenSigAutoGenSnd" SG_ 1497 VS1_zent_FH_Schalter 1;
BA_ "GenSigSendType" SG_ 1497 VS1_zent_FH_Schalter 3;
BA_ "GenSigAutoGenDsp" SG_ 1497 VS1_VD_zu_ver 1;
BA_ "GenSigAutoGenSnd" SG_ 1497 VS1_VD_zu_ver 1;
BA_ "GenSigSendType" SG_ 1497 VS1_VD_zu_ver 3;
BA_ "GenSigAutoGenDsp" SG_ 1497 VS1_VD_entriegelt 1;
BA_ "GenSigAutoGenSnd" SG_ 1497 VS1_VD_entriegelt 1;
BA_ "GenSigSendType" SG_ 1497 VS1_VD_entriegelt 3;
BA_ "GenSigAutoGenDsp" SG_ 1497 VS1_VD_offen_ver 1;
BA_ "GenSigAutoGenSnd" SG_ 1497 VS1_VD_offen_ver 1;
BA_ "GenSigSendType" SG_ 1497 VS1_VD_offen_ver 3;
BA_ "GenSigAutoGenDsp" SG_ 1497 VS1_VD_Zwischenposition 1;
BA_ "GenSigAutoGenSnd" SG_ 1497 VS1_VD_Zwischenposition 1;
BA_ "GenSigSendType" SG_ 1497 VS1_VD_Zwischenposition 3;
BA_ "GenSigAutoGenDsp" SG_ 1497 VS1_VD_Bew_auf 1;
BA_ "GenSigAutoGenSnd" SG_ 1497 VS1_VD_Bew_auf 1;
BA_ "GenSigSendType" SG_ 1497 VS1_VD_Bew_auf 3;
BA_ "GenSigAutoGenDsp" SG_ 1497 VS1_VD_Bew_zu 1;
BA_ "GenSigAutoGenSnd" SG_ 1497 VS1_VD_Bew_zu 1;
BA_ "GenSigSendType" SG_ 1497 VS1_VD_Bew_zu 3;
BA_ "GenSigAutoGenDsp" SG_ 1497 VS1_Verdeck_Anf 1;
BA_ "GenSigAutoGenSnd" SG_ 1497 VS1_Verdeck_Anf 1;
BA_ "GenSigSendType" SG_ 1497 VS1_Verdeck_Anf 3;
BA_ "GenSigAutoGenDsp" SG_ 1497 VS1_Hardtop 1;
BA_ "GenSigAutoGenSnd" SG_ 1497 VS1_Hardtop 1;
BA_ "GenSigSendType" SG_ 1497 VS1_Hardtop 3;
BA_ "GenSigAutoGenDsp" SG_ 1497 VS1_VD_Fehler 1;
BA_ "GenSigAutoGenSnd" SG_ 1497 VS1_VD_Fehler 1;
BA_ "GenSigSendType" SG_ 1497 VS1_VD_Fehler 3;
BA_ "GenSigAutoGenDsp" SG_ 1497 VS1_Lampe_Blk 1;
BA_ "GenSigAutoGenSnd" SG_ 1497 VS1_Lampe_Blk 1;
BA_ "GenSigSendType" SG_ 1497 VS1_Lampe_Blk 3;
BA_ "GenSigAutoGenDsp" SG_ 1497 VS1_Text_3 1;
BA_ "GenSigAutoGenSnd" SG_ 1497 VS1_Text_3 1;
BA_ "GenSigSendType" SG_ 1497 VS1_Text_3 3;
BA_ "GenSigAutoGenDsp" SG_ 1497 VS1_Buzzer 1;
BA_ "GenSigAutoGenSnd" SG_ 1497 VS1_Buzzer 1;
BA_ "GenSigSendType" SG_ 1497 VS1_Buzzer 3;
BA_ "GenSigAutoGenDsp" SG_ 1497 VS1_HHS_enable 1;
BA_ "GenSigAutoGenSnd" SG_ 1497 VS1_HHS_enable 1;
BA_ "GenSigSendType" SG_ 1497 VS1_HHS_enable 3;
BA_ "GenSigAutoGenDsp" SG_ 1497 VS1_VDKD_auf 1;
BA_ "GenSigAutoGenSnd" SG_ 1497 VS1_VDKD_auf 1;
BA_ "GenSigSendType" SG_ 1497 VS1_VDKD_auf 3;
BA_ "GenSigAutoGenDsp" SG_ 1497 VS1_Text_1 1;
BA_ "GenSigAutoGenSnd" SG_ 1497 VS1_Text_1 1;
BA_ "GenSigSendType" SG_ 1497 VS1_Text_1 3;
BA_ "GenSigAutoGenDsp" SG_ 1497 VS1_KD_Fehler 1;
BA_ "GenSigAutoGenSnd" SG_ 1497 VS1_KD_Fehler 1;
BA_ "GenSigSendType" SG_ 1497 VS1_KD_Fehler 3;
BA_ "GenSigAutoGenDsp" SG_ 1497 VS1_LED 1;
BA_ "GenSigAutoGenSnd" SG_ 1497 VS1_LED 1;
BA_ "GenSigSendType" SG_ 1497 VS1_LED 3;
BA_ "GenSigAutoGenDsp" SG_ 1497 VS1_Blink_LED 1;
BA_ "GenSigAutoGenSnd" SG_ 1497 VS1_Blink_LED 1;
BA_ "GenSigSendType" SG_ 1497 VS1_Blink_LED 3;
BA_ "GenSigAutoGenDsp" SG_ 1497 VS1_1_Akustik 1;
BA_ "GenSigAutoGenSnd" SG_ 1497 VS1_1_Akustik 1;
BA_ "GenSigSendType" SG_ 1497 VS1_1_Akustik 3;
BA_ "GenSigAutoGenDsp" SG_ 1497 VS1_2_Akustik 1;
BA_ "GenSigAutoGenSnd" SG_ 1497 VS1_2_Akustik 1;
BA_ "GenSigSendType" SG_ 1497 VS1_2_Akustik 3;
BA_ "GenSigAutoGenDsp" SG_ 1497 VS1_3_Akustik 1;
BA_ "GenSigAutoGenSnd" SG_ 1497 VS1_3_Akustik 1;
BA_ "GenSigSendType" SG_ 1497 VS1_3_Akustik 3;
BA_ "GenSigAutoGenDsp" SG_ 1497 VS1_Verdeckbetrieb 1;
BA_ "GenSigAutoGenSnd" SG_ 1497 VS1_Verdeckbetrieb 1;
BA_ "GenSigSendType" SG_ 1497 VS1_Verdeckbetrieb 3;
BA_ "GenSigAutoGenDsp" SG_ 1497 VS1_ZZH_offen 1;
BA_ "GenSigAutoGenSnd" SG_ 1497 VS1_ZZH_offen 1;
BA_ "GenSigSendType" SG_ 1497 VS1_ZZH_offen 3;
BA_ "GenSigAutoGenDsp" SG_ 1497 VS1_Text_2 1;
BA_ "GenSigAutoGenSnd" SG_ 1497 VS1_Text_2 1;
BA_ "GenSigSendType" SG_ 1497 VS1_Text_2 3;
BA_ "GenSigAutoGenDsp" SG_ 1497 VS1_Texte 1;
BA_ "GenSigAutoGenSnd" SG_ 1497 VS1_Texte 1;
BA_ "GenSigSendType" SG_ 1497 VS1_Texte 3;
BA_ "GenSigAutoGenDsp" SG_ 707 ZS1_ZAS_Kl_S 1;
BA_ "GenSigAutoGenSnd" SG_ 707 ZS1_ZAS_Kl_S 1;
BA_ "GenSigSendType" SG_ 707 ZS1_ZAS_Kl_S 3;
BA_ "GenSigAutoGenDsp" SG_ 707 ZS1_ZAS_Kl_15 1;
BA_ "GenSigAutoGenSnd" SG_ 707 ZS1_ZAS_Kl_15 1;
BA_ "GenSigSendType" SG_ 707 ZS1_ZAS_Kl_15 3;
BA_ "GenSigFuncType" SG_ 707 ZS1_ZAS_Kl_15 6;
BA_ "GenSigAutoGenDsp" SG_ 707 ZS1_ZAS_Kl_X 1;
BA_ "GenSigAutoGenSnd" SG_ 707 ZS1_ZAS_Kl_X 1;
BA_ "GenSigSendType" SG_ 707 ZS1_ZAS_Kl_X 3;
BA_ "GenSigAutoGenDsp" SG_ 707 ZS1_ZAS_Kl_50 1;
BA_ "GenSigAutoGenSnd" SG_ 707 ZS1_ZAS_Kl_50 1;
BA_ "GenSigSendType" SG_ 707 ZS1_ZAS_Kl_50 3;
BA_ "GenSigAutoGenDsp" SG_ 707 ZS1_ZAS_KL_P 1;
BA_ "GenSigAutoGenSnd" SG_ 707 ZS1_ZAS_KL_P 1;
BA_ "GenSigSendType" SG_ 707 ZS1_ZAS_KL_P 3;
VAL_ 1349 PA3_KD_Fehler 1 "Fehlerspeichereintrag" 0 "kein_Fehlerspeichereintrag" ;
VAL_ 1355 PA5_VL_Abstand 255 "kein_Hindernis" ;
VAL_ 1355 PA5_VR_Abstand 255 "kein_Hindernis" ;
VAL_ 1355 PA5_HL_Abstand 255 "kein_Hindernis" ;
VAL_ 1355 PA5_HR_Abstand 255 "kein_Hindernis" ;
VAL_ 1355 PA5_VML_Abstand 255 "kein_Hindernis" ;
VAL_ 1355 PA5_VMR_Abstand 255 "kein_Hindernis" ;
VAL_ 1355 PA5_HML_Abstand 255 "kein_Hindernis" ;
VAL_ 1355 PA5_HMR_Abstand 255 "kein_Hindernis" ;
VAL_ 1633 RA4_Radio_Surround 0 "inaktiv" 1 "aktiv" ;
VAL_ 1633 RA4_Radio_Error_flag 1 "Fehlerspeichereintrag" 0 "kein_Fehlerspeichereintrag" ;
VAL_ 1347 RV1_KD_Fehler 1 "Fehlerspeichereintrag" 0 "kein_Fehlerspeichereintrag" ;
VAL_ 1621 VBN_Motor_A 0 "kein_Sollverbau" 1 "Sollverbau" ;
VAL_ 1621 VBN_Getriebe_A 0 "kein_Sollverbau" 1 "Sollverbau" ;
VAL_ 1621 VBN_Bremse_A 0 "kein_Sollverbau" 1 "Sollverbau" ;
VAL_ 1621 VBN_Kombi_A 0 "kein_Sollverbau" 1 "Sollverbau" ;
VAL_ 1621 VBN_LSM_A 0 "kein_Sollverbau" 1 "Sollverbau" ;
VAL_ 1621 VBN_Airbag_A 0 "kein_Sollverbau" 1 "Sollverbau" ;
VAL_ 1621 VBN_Lenkhilfe_A 0 "kein_Sollverbau" 1 "Sollverbau" ;
VAL_ 1621 VBN_dyn_LWR_A 0 "kein_Sollverbau" 1 "Sollverbau" ;
VAL_ 1621 VBN_Niveau_A 0 "kein_Sollverbau" 1 "Sollverbau" ;
VAL_ 1621 VBN_Allrad_A 0 "kein_Sollverbau" 1 "Sollverbau" ;
VAL_ 1621 VBN_ADR_Sensor_A 0 "kein_Sollverbau" 1 "Sollverbau" ;
VAL_ 1621 VBN_ADR_getrennt 1 "ADR_getrennt" 0 "ADR_angeschlossen" ;
VAL_ 1621 VBN_Parkbremse_A 0 "kein_Sollverbau" 1 "Sollverbau" ;
VAL_ 1621 VBN_EZS_A 0 "kein_Sollverbau" 1 "Sollverbau" ;
VAL_ 1621 VBN_Daempfer_A 0 "kein_Sollverbau" 1 "Sollverbau" ;
VAL_ 1621 VBN_Quersperre 0 "kein_Sollverbau" 1 "Sollverbau" ;
VAL_ 1621 VBN_Motor_Slave_A 0 "kein_Sollverbau" 1 "Sollverbau" ;
VAL_ 1621 VBN_SWA_A 0 "kein_Sollverbau" 1 "Sollverbau" ;
VAL_ 1621 VBN_LDW_A 0 "kein_Sollverbau" 1 "Sollverbau" ;
VAL_ 1621 VBN_RKA_Plus_A 0 "kein_Sollverbau" 1 "Sollverbau" ;
VAL_ 1621 VBN_PLA_A 0 "kein_Sollverbau" 1 "Sollverbau" ;
VAL_ 1621 VBN_WFS_KBI 0 "kein_Sollverbau" 1 "Sollverbau" ;
VAL_ 1621 VBN_Kombi_KBI 0 "kein_Sollverbau" 1 "Sollverbau" ;
VAL_ 1621 VBN_Soll_Ist_OK 1 "Sollverbau_gleich_Istverbau" 0 "Sollverbau_ungleich_Istverbau" ;
VAL_ 1621 VBN_BSG_K 0 "kein_Sollverbau" 1 "Sollverbau" ;
VAL_ 1621 VBN_KSG_K 0 "kein_Sollverbau" 1 "Sollverbau" ;
VAL_ 1621 VBN_TSG_FT_K 0 "kein_Sollverbau" 1 "Sollverbau" ;
VAL_ 1621 VBN_TSG_BT_K 0 "kein_Sollverbau" 1 "Sollverbau" ;
VAL_ 1621 VBN_TSG_HL_K 0 "kein_Sollverbau" 1 "Sollverbau" ;
VAL_ 1621 VBN_TSG_HR_K 0 "kein_Sollverbau" 1 "Sollverbau" ;
VAL_ 1621 VBN_Memory_K 0 "kein_Sollverbau" 1 "Sollverbau" ;
VAL_ 1621 VBN_Dachmodul_K 0 "kein_Sollverbau" 1 "Sollverbau" ;
VAL_ 1621 VBN_Zentralelektrik_II_K 0 "kein_Sollverbau" 1 "Sollverbau" ;
VAL_ 1621 VBN_RDK_K 0 "kein_Sollverbau" 1 "Sollverbau" ;
VAL_ 1621 VBN_SMLS_K 0 "kein_Sollverbau" 1 "Sollverbau" ;
VAL_ 1621 VBN_Gateway_K 0 "kein_Sollverbau" 1 "Sollverbau" ;
VAL_ 1621 VBN_Clima_K 0 "kein_Sollverbau" 1 "Sollverbau" ;
VAL_ 1621 VBN_APS_K 0 "kein_Sollverbau" 1 "Sollverbau" ;
VAL_ 1621 VBN_PTC_Heizung_K 0 "kein_Sollverbau" 1 "Sollverbau" ;
VAL_ 1621 VBN_Standhzg_K 0 "kein_Sollverbau" 1 "Sollverbau" ;
VAL_ 1621 VBN_VSG_K 0 "kein_Sollverbau" 1 "Sollverbau" ;
VAL_ 1621 VBN_RSE_I 0 "kein_Sollverbau" 1 "Sollverbau" ;
VAL_ 1621 VBN_Wischer_K 0 "kein_Sollverbau" 1 "Sollverbau" ;
VAL_ 1621 VBN_MDI_I 0 "kein_Sollverbau" 1 "Sollverbau" ;
VAL_ 1621 VBN_AAG_K 0 "kein_Sollverbau" 1 "Sollverbau" ;
VAL_ 1621 VBN_Mem_BF_K 0 "kein_Sollverbau" 1 "Sollverbau" ;
VAL_ 1621 VBN_Easy_Entry_VF 0 "kein_Sollverbau" 1 "Sollverbau" ;
VAL_ 1621 VBN_Easy_Entry_VB 0 "kein_Sollverbau" 1 "Sollverbau" ;
VAL_ 1621 VBN_Heckdeckel_K 0 "kein_Sollverbau" 1 "Sollverbau" ;
VAL_ 1621 VBN_Rearview_I 0 "kein_Sollverbau" 1 "Sollverbau" ;
VAL_ 1621 VBN_Sonderfahrzeug_SG_K 0 "kein_Sollverbau" 1 "Sollverbau" ;
VAL_ 1621 VBN_Tastenmodul_I 0 "kein_Sollverbau" 1 "Sollverbau" ;
VAL_ 1621 VBN_Kompass_I 0 "kein_Sollverbau" 1 "Sollverbau" ;
VAL_ 1621 VBN_WFS_K 0 "kein_Sollverbau" 1 "Sollverbau" ;
VAL_ 1621 VBN_GSM_Pager_I 0 "kein_Sollverbau" 1 "Sollverbau" ;
VAL_ 1621 VBN_InfoElektronik 0 "kein_Sollverbau" 1 "Sollverbau" ;
VAL_ 1621 VBN_DSP_I 0 "kein_Sollverbau" 1 "Sollverbau" ;
VAL_ 1621 VBN_DAB_I 0 "kein_Sollverbau" 1 "Sollverbau" ;
VAL_ 1621 VBN_Telematik_I 0 "kein_Sollverbau" 1 "Sollverbau" ;
VAL_ 1621 VBN_Navigation_I 0 "kein_Sollverbau" 1 "Sollverbau" ;
VAL_ 1621 VBN_TV_Tuner_I 0 "kein_Sollverbau" 1 "Sollverbau" ;
VAL_ 1621 VBN_Neigungsmodul_I 0 "kein_Sollverbau" 1 "Sollverbau" ;
VAL_ 1621 VBN_Radio_I 0 "kein_Sollverbau" 1 "Sollverbau" ;
VAL_ 1621 VBN_Telefon_I 0 "kein_Sollverbau" 1 "Sollverbau" ;
VAL_ 997 SH1_SH_Modus 1 "Heizgeraet_ZH" 0 "Heizgeraet_SH" ;
VAL_ 997 SH1_Geblaese 1 "Geblaese_EIN" 0 "Geblaese_AUS" ;
VAL_ 997 SH1_LED 1 "Lampe_ein" 0 "Lampe_aus" ;
VAL_ 997 SH1_ZusatzHeizung 0 "Zuheizer_AUS" 1 "Zuheizer_EIN" ;
VAL_ 997 SH1_ein_Wasserpumpe 1 "Wasserpumpe_EIN" 0 "Wasserpumpe_AUS" ;
VAL_ 997 SH1_Fehlerstatus 0 "kein_Fehler" 3 "HW_defekt" 5 "Betriebsstoerung" 4 "Crash" 7 "keine_StHzg_beim_Tanken" 1 "Battery_Low" 6 "Ueberhitzung" 2 "Fuel_Low" ;
VAL_ 997 SH1_KD_Fehler 1 "Fehlerspeichereintrag" 0 "kein_Fehlerspeichereintrag" ;
VAL_ 997 SH1_SH_Verbau 1 "Standheizung" 0 "Zuheizer" ;
VAL_ 997 SH1_Pumpe_on 1 "Kraftstoffpumpe_ein" 0 "Kraftstoffpumpe_aus" ;
VAL_ 997 SH1_KW_Warm 1 "ja" 0 "nein" ;
VAL_ 997 SH1_Lueften 0 "Standlueften_AUS" 1 "Standlueften_EIN" ;
VAL_ 1617 SY1_CAN_Extern 0 "CANextern_getrennt" 1 "CANextern_zugeschaltet" ;
VAL_ 1617 SY1_Diag_Antrieb 1 "CAN_Antrieb_in_Diagnose" 0 "zZt_keine_Antrieb_Diagnose" ;
VAL_ 1617 SY1_Sleep_Komfort 1 "Busruhe" 0 "keine_Busruhe" ;
VAL_ 1617 SY1_Diag_Komfort 1 "Diagnoseanf_im_CAN_Komf_erkannt" 0 "zZt_keine_Komfort_Diagnose" ;
VAL_ 1617 SY1_Sleep_Infotainment 1 "Busruhe" 0 "keine_Busruhe" ;
VAL_ 1617 SY1_Diag_Infotainment 0 "zZt_keine_Infotainement_Diagnose" 1 "Diagnoseanf_im_CAN_Infot_erkannt" ;
VAL_ 1617 SY1_Infotainment 1 "verbaut" 0 "nicht_verbaut" ;
VAL_ 1617 SY1_Verbauliste_gueltig 1 "gueltig" 0 "ungueltig" ;
VAL_ 1617 SY1_Klasse 8 "LT_Klasse" 3 "A_Klasse" 9 "L_Klasse" 1 "A00_Klasse" 7 "T_Klasse" 4 "B_Klasse" 5 "C_Klasse" 2 "A0_Klasse" 6 "D_Klasse" 0 "A000_Klasse" ;
VAL_ 1617 SY1_Marke 6 "Lamborghini" 5 "Bugatti" 3 "SK_Skoda" 0 "VW_Volkswagen" 7 "Bentley" 8 "RollsRoyce" 14 "Ford" 1 "AU_Audi" 2 "SE_Seat" 15 "Porsche" 4 "VN_VWNutzfzg" ;
VAL_ 1617 SY1_Derivat 7 "CityVan_PickUp" 3 "Fliessheck" 6 "Offroad" 2 "Variant" 1 "Stufenheck_Nutz" 5 "Cabrio_Roadstar_Spider" 0 "Kurzheck_Multivan" 15 "nicht_bekannt" 8 "MPV" 9 "Sonstige" 4 "Coupe_Sportwagen" ;
VAL_ 1617 SY1_Erweiterung 5 "offene_Aufbauten" 15 "nicht_bekannt" 8 "Hochdach" 2 "geaenderte_Front_Heck" 7 "Flachdach" 9 "Sonstige" 6 "geschlossene_Aufbauten" 4 "Hochmotorisierung" 3 "Syncro" 0 "kurzer_Radstand" 1 "langer_Radstand" ;
VAL_ 1617 SY1_Rechtslenker 0 "Linkslenker" 1 "Rechtslenker" ;
VAL_ 1617 SY1_Viertuerer 1 "Vier_Tueren_oder_mehr" 0 "Kleiner_vier_Tueren" ;
VAL_ 1617 SY1_Transportmode 0 "nicht_aktiv" 1 "aktiv" ;
VAL_ 1617 SY1_KD_Fehler 1 "Fehlerspeichereintrag" 0 "kein_Fehlerspeichereintrag" ;
VAL_ 1617 SY1_Relais_FAS_Zweig 0 "Relais_geschlossen" 3 "reserviert" 1 "Relais_planmaessig_geoeffnet" 2 "Relais_im_Fehlerfall_geoeffnet" ;
VAL_ 1617 SY1_ELV_Lock_Supply 0 "keine_Freigabe" 1 "Freigabe" ;
VAL_ 1617 SY1_QRS_Messmodus 1 "QRS_ein" 0 "QRS_aus" ;
VAL_ 1617 SY1_NWDF_gueltig 1 "NWDF_Fkt_unterstuetzt" 0 "NWDF_Fkt_nicht_unterstuetzt" ;
VAL_ 1617 SY1_NWDF 1 "Ueberwachung_freigegeben" 0 "Ueberwachung_nicht_freigegeben" ;
VAL_ 1617 SY1_Notbrems_Status 0 "keine_Notbremsung" 1 "Notbremssituation" ;
VAL_ 1477 TAS_TA_Error_flag 1 "Fehlerspeichereintrag" 0 "kein_Fehlerspeichereintrag" ;
VAL_ 1637 TF3_BT_ConnectionState 1 "BT_Verbindung" 0 "keine_BT_Verbindung" ;
VAL_ 1637 TF3_Phone_Error_flag 1 "Fehlerspeichereintrag" 0 "kein_Fehlerspeichereintrag" ;
VAL_ 1447 TM1_TM_Error_flag 1 "Fehlerspeichereintrag" 0 "kein_Fehlerspeichereintrag" ;
VAL_ 1538 TV1_TVA_Error_flag 1 "Fehlerspeichereintrag" 0 "kein_Fehlerspeichereintrag" ;
VAL_ 1497 VS1_Heckschloss_auf 0 "kein_Oeffnen" 1 "Heckschloss_oeffnen" ;
VAL_ 1497 VS1_auf_Verriegelung 1 "Verriegelung_oeffnen_ansteuern" 0 "keine_Ansteuerung" ;
VAL_ 1497 VS1_zu_Verriegelung 1 "Verriegelung_schliessen_ansteuern" 0 "keine_Ansteuerung" ;
VAL_ 1497 VS1_Sperren 1 "Sperren" 0 "kein_Sperren" ;
VAL_ 1497 VS1_VD_zu_ver 1 "Verdeck_geschl_verr" 0 "Verdeck_nicht_geschl_verr" ;
VAL_ 1497 VS1_VD_entriegelt 1 "Verdeck_bzw_VDKD_auf" 0 "Verdeck_und_VDKD_zu" ;
VAL_ 1497 VS1_VD_offen_ver 0 "Verdeck_nicht_offen_verr" 1 "Verdeck_offen_verr" ;
VAL_ 1497 VS1_Verdeck_Anf 1 "Anforderung_Verdeckbetrieb" 0 "keine_Verdeckanforderung" ;
VAL_ 1497 VS1_Hardtop 0 "Hardtop_nicht_montiert" 1 "Hardtop_montiert" ;
VAL_ 1497 VS1_VDKD_auf 0 "VDKD_nicht_vollst_auf" 1 "VDKD_vollstaendig_auf" ;
VAL_ 1497 VS1_KD_Fehler 1 "Fehlerspeichereintrag" 0 "kein_Fehlerspeichereintrag" ;
VAL_ 1497 VS1_LED 1 "Lampe_ein" 0 "Lampe_aus" ;
VAL_ 1497 VS1_Blink_LED 0 "Kein_Blinken" 1 "Blinken_der_LED" ;
VAL_ 1497 VS1_1_Akustik 1 "Ansteuerung_der_Akustik" 0 "Kein_Ton" ;
VAL_ 1497 VS1_2_Akustik 0 "Kein_Ton" 1 "Ansteuerung_der_Akustik" ;
VAL_ 1497 VS1_3_Akustik 1 "Ansteuerung_der_Akustik" 0 "Kein_Ton" ;
VAL_ 1497 VS1_Verdeckbetrieb 0 "kein_Verdeckbetrieb" 1 "Verdeckbetrieb" ;
VAL_ 1497 VS1_ZZH_offen 1 "Zuziehhilfe_nicht_eingefahren" 0 "Zuziehhilfe_eingefahren" ;
VAL_ 1497 VS1_Texte 0 "keine_Anzeige" ;
